VERSION ""

NS_ :

BS_:

BU_: AHLM ASBS CADM CBC DIAGNOST DPDM DTCM ECM EHPS ESC ESL ESM ETM EVCU2 GPF IC IRCM LTM OCM ORC PTS RF_HUB SCCM SGW TBM TCM

BO_ 1266 D_RS_GPF: 8 GPF
 SG_ D_RS_GPF : 7|64@0+ (1,0) [0|0] ""  SGW,TBM

BO_ 1284 D_RS_CBC: 8 CBC
 SG_ D_RS_CBC : 7|64@0+ (1,0) [0|0] ""  DIAGNOST,SGW,TBM

BO_ 1323 D_RS_TBM: 8 SGW
 SG_ D_RS_TBM : 7|64@0+ (1,0) [0|0] ""  DIAGNOST

BO_ 1408 ECU_APPL_RF_HUB: 8 RF_HUB
 SG_ ECU_APPL_RF_HUB : 7|64@0+ (1,0) [0|0] ""  DIAGNOST,SGW

BO_ 1409 ECU_APPL_CBC: 8 CBC
 SG_ ECU_APPL_CBC : 7|64@0+ (1,0) [0|0] ""  DIAGNOST,SGW

BO_ 1410 ECU_APPL_IC: 8 IC
 SG_ ECU_APPL_IC : 7|64@0+ (1,0) [0|0] ""  DIAGNOST,SGW

BO_ 1412 ECU_APPL_ORC: 8 ORC
 SG_ ECU_APPL_ORC : 7|64@0+ (1,0) [0|0] ""  DIAGNOST,SGW

BO_ 1415 ECU_APPL_ESC: 8 ESC
 SG_ ECU_APPL_ESC : 7|64@0+ (1,0) [0|0] ""  DIAGNOST,SGW

BO_ 1416 ECU_APPL_ESL: 8 ESL
 SG_ ECU_APPL_ESL : 7|64@0+ (1,0) [0|0] ""  DIAGNOST,SGW

BO_ 1417 ECU_APPL_ESM: 8 ESM
 SG_ ECU_APPL_ESM : 7|64@0+ (1,0) [0|0] ""  DIAGNOST,SGW

BO_ 1418 ECU_APPL_ASBS: 8 ASBS
 SG_ ECU_APPL_ASBS : 7|64@0+ (1,0) [0|0] ""  DIAGNOST,SGW

BO_ 1419 ECU_APPL_DTCM: 8 DTCM
 SG_ ECU_APPL_DTCM : 7|64@0+ (1,0) [0|0] ""  DIAGNOST,SGW

BO_ 1425 ECU_APPL_DPDM: 8 DPDM
 SG_ ECU_APPL_DPDM : 7|64@0+ (1,0) [0|0] ""  DIAGNOST,SGW

BO_ 1427 ECU_APPL_DASM: 8 CADM
 SG_ ECU_APPL_DASM : 7|64@0+ (1,0) [0|0] ""  DIAGNOST,SGW

BO_ 1434 ECU_APPL_EPS: 8 EHPS
 SG_ ECU_APPL_EPS : 7|64@0+ (1,0) [0|0] ""  DIAGNOST,SGW

BO_ 1438 ECU_APPL_OCM: 8 OCM
 SG_ ECU_APPL_OCM : 7|64@0+ (1,0) [0|0] ""  DIAGNOST,SGW

BO_ 1442 ECU_APPL_PTS: 8 PTS
 SG_ ECU_APPL_PTS : 7|64@0+ (1,0) [0|0] ""  DIAGNOST,SGW

BO_ 1443 ECU_APPL_SCCM: 8 SCCM
 SG_ ECU_APPL_SCCM : 7|64@0+ (1,0) [0|0] ""  DIAGNOST,SGW

BO_ 1449 ECU_APPL_AHLM: 8 AHLM
 SG_ ECU_APPL_AHLM : 7|64@0+ (1,0) [0|0] ""  DIAGNOST,SGW

BO_ 1464 ECU_APPL_ECM: 8 ECM
 SG_ ECU_APPL_ECM : 7|64@0+ (1,0) [0|0] ""  DIAGNOST,SGW

BO_ 1465 ECU_APPL_TCM: 8 TCM
 SG_ ECU_APPL_TCM : 7|64@0+ (1,0) [0|0] ""  DIAGNOST,SGW

BO_ 1468 ECU_APPL_BSMO: 8 ESC
 SG_ ECU_APPL_BSMO : 7|64@0+ (1,0) [0|0] ""  DIAGNOST,SGW

BO_ 1515 ECU_APPL_TBM: 8 SGW
 SG_ ECU_APPL_TBM : 7|64@0+ (1,0) [0|0] ""  DIAGNOST

BO_ 1536 SD_RS_RF_HUB: 8 RF_HUB
 SG_ SD_RS_RF_HUB : 7|64@0+ (1,0) [0|0] ""  SGW,TBM

BO_ 1537 SD_RS_CBC: 8 CBC
 SG_ SD_RS_CBC : 7|64@0+ (1,0) [0|0] ""  SGW,TBM

BO_ 1538 SD_RS_IC: 8 IC
 SG_ SD_RS_IC : 7|64@0+ (1,0) [0|0] ""  SGW,TBM

BO_ 1540 SD_RS_ORC: 8 ORC
 SG_ SD_RS_ORC : 7|64@0+ (1,0) [0|0] ""  SGW,TBM

BO_ 1543 SD_RS_ESC: 8 ESC
 SG_ SD_RS_ESC : 7|64@0+ (1,0) [0|0] ""  SGW,TBM

BO_ 1544 SD_RS_ESL: 8 ESL
 SG_ SD_RS_ESL : 7|64@0+ (1,0) [0|0] ""  SGW,TBM

BO_ 1545 SD_RS_ESM: 8 ESM
 SG_ SD_RS_ESM : 7|64@0+ (1,0) [0|0] ""  SGW,TBM

BO_ 1546 SD_RS_ASBS: 8 ASBS
 SG_ SD_RS_ASBS : 7|64@0+ (1,0) [0|0] ""  SGW,TBM

BO_ 1547 SD_RS_DTCM: 8 DTCM
 SG_ SD_RS_DTCM : 7|64@0+ (1,0) [0|0] ""  SGW,TBM

BO_ 1553 SD_RS_DPDM: 8 DPDM
 SG_ SD_RS_DPDM : 7|64@0+ (1,0) [0|0] ""  SGW,TBM

BO_ 1555 SD_RS_DASM: 8 CADM
 SG_ SD_RS_DASM : 7|64@0+ (1,0) [0|0] ""  SGW,TBM

BO_ 1562 SD_RS_EPS: 8 EHPS
 SG_ SD_RS_EPS : 7|64@0+ (1,0) [0|0] ""  SGW,TBM

BO_ 1566 SD_RS_OCM: 8 OCM
 SG_ SD_RS_OCM : 7|64@0+ (1,0) [0|0] ""  SGW,TBM

BO_ 1568 D_RQ_CBC: 8 DIAGNOST
 SG_ D_RQ_CBC : 7|64@0+ (1,0) [0|0] ""  CBC

BO_ 1570 SD_RS_PTS: 8 PTS
 SG_ SD_RS_PTS : 7|64@0+ (1,0) [0|0] ""  SGW,TBM

BO_ 1571 SD_RS_SCCM: 8 SCCM
 SG_ SD_RS_SCCM : 7|64@0+ (1,0) [0|0] ""  SGW,TBM

BO_ 1577 SD_RS_AHLM: 8 AHLM
 SG_ SD_RS_AHLM : 7|64@0+ (1,0) [0|0] ""  SGW,TBM

BO_ 1586 SD_RS_GPF: 8 GPF
 SG_ SD_RS_GPF : 7|64@0+ (1,0) [0|0] ""  SGW,TBM

BO_ 1592 SD_RS_ECM: 8 ECM
 SG_ SD_RS_ECM : 7|64@0+ (1,0) [0|0] ""  DIAGNOST,SGW,TBM

BO_ 1593 SD_RS_TCM: 8 TCM
 SG_ SD_RS_TCM : 7|64@0+ (1,0) [0|0] ""  SGW,TBM

BO_ 1596 SD_RS_BSMO: 8 ESC
 SG_ SD_RS_BSMO : 7|64@0+ (1,0) [0|0] ""  ETM,SGW,TBM

BO_ 1643 SD_RS_TBM: 8 SGW
 SG_ SD_RS_TBM : 7|64@0+ (1,0) [0|0] "" Vector__XXX

BO_ 1728 APPL_ECU_RF_HUB: 8 DIAGNOST
 SG_ APPL_ECU_RF_HUB : 7|64@0+ (1,0) [0|0] ""  RF_HUB

BO_ 1729 APPL_ECU_CBC: 8 DIAGNOST
 SG_ APPL_ECU_CBC : 7|64@0+ (1,0) [0|0] ""  CBC

BO_ 1730 APPL_ECU_IC: 8 DIAGNOST
 SG_ APPL_ECU_IC : 7|64@0+ (1,0) [0|0] ""  IC

BO_ 1732 APPL_ECU_ORC: 8 DIAGNOST
 SG_ APPL_ECU_ORC : 7|64@0+ (1,0) [0|0] ""  ORC

BO_ 1735 APPL_ECU_ESC: 8 DIAGNOST
 SG_ APPL_ECU_ESC : 7|64@0+ (1,0) [0|0] ""  ESC

BO_ 1736 APPL_ECU_ESL: 8 DIAGNOST
 SG_ APPL_ECU_ESL : 7|64@0+ (1,0) [0|0] ""  ESL

BO_ 1737 APPL_ECU_ESM: 8 DIAGNOST
 SG_ APPL_ECU_ESM : 7|64@0+ (1,0) [0|0] ""  ESM

BO_ 1738 APPL_ECU_ASBS: 8 DIAGNOST
 SG_ APPL_ECU_ASBS : 7|64@0+ (1,0) [0|0] ""  ASBS

BO_ 1739 APPL_ECU_DTCM: 8 DIAGNOST
 SG_ APPL_ECU_DTCM : 7|64@0+ (1,0) [0|0] ""  DTCM

BO_ 1745 APPL_ECU_DPDM: 8 DIAGNOST
 SG_ APPL_ECU_DPDM : 7|64@0+ (1,0) [0|0] ""  DPDM

BO_ 1747 APPL_ECU_DASM: 8 DIAGNOST
 SG_ APPL_ECU_DASM : 7|64@0+ (1,0) [0|0] ""  CADM,IRCM

BO_ 1754 APPL_ECU_EPS: 8 DIAGNOST
 SG_ APPL_ECU_EPS : 7|64@0+ (1,0) [0|0] ""  EHPS

BO_ 1758 APPL_ECU_OCM: 8 DIAGNOST
 SG_ APPL_ECU_OCM : 7|64@0+ (1,0) [0|0] ""  OCM

BO_ 1762 APPL_ECU_PTS: 8 DIAGNOST
 SG_ APPL_ECU_PTS : 7|64@0+ (1,0) [0|0] ""  PTS

BO_ 1763 APPL_ECU_SCCM: 8 DIAGNOST
 SG_ APPL_ECU_SCCM : 7|64@0+ (1,0) [0|0] ""  SCCM

BO_ 1769 APPL_ECU_AHLM: 8 DIAGNOST
 SG_ APPL_ECU_AHLM : 7|64@0+ (1,0) [0|0] ""  AHLM

BO_ 1784 APPL_ECU_ECM: 8 DIAGNOST
 SG_ APPL_ECU_ECM : 7|64@0+ (1,0) [0|0] ""  ECM

BO_ 1785 APPL_ECU_TCM: 8 DIAGNOST
 SG_ APPL_ECU_TCM : 7|64@0+ (1,0) [0|0] ""  TCM

BO_ 1788 APPL_ECU_BSMO: 8 DIAGNOST
 SG_ APPL_ECU_BSMO : 7|64@0+ (1,0) [0|0] ""  ESC

BO_ 1835 APPL_ECU_TBM: 8 DIAGNOST
 SG_ APPL_ECU_TBM : 7|64@0+ (1,0) [0|0] ""  TBM

BO_ 1856 D_RQ_RF_HUB: 8 DIAGNOST
 SG_ D_RQ_RF_HUB : 7|64@0+ (1,0) [0|0] ""  RF_HUB

BO_ 1858 D_RQ_IC: 8 DIAGNOST
 SG_ D_RQ_IC : 7|64@0+ (1,0) [0|0] ""  IC

BO_ 1860 D_RQ_ORC: 8 DIAGNOST
 SG_ D_RQ_ORC : 7|64@0+ (1,0) [0|0] ""  ORC

BO_ 1863 D_RQ_ESC: 8 DIAGNOST
 SG_ D_RQ_ESC : 7|64@0+ (1,0) [0|0] ""  ESC

BO_ 1864 D_RQ_ESL: 8 DIAGNOST
 SG_ D_RQ_ESL : 7|64@0+ (1,0) [0|0] ""  ESL

BO_ 1865 D_RQ_ESM: 8 DIAGNOST
 SG_ D_RQ_ESM : 7|64@0+ (1,0) [0|0] ""  ESM

BO_ 1866 D_RQ_ASBS: 8 DIAGNOST
 SG_ D_RQ_ASBS : 7|64@0+ (1,0) [0|0] ""  ASBS

BO_ 1867 D_RQ_DTCM: 8 DIAGNOST
 SG_ D_RQ_DTCM : 7|64@0+ (1,0) [0|0] ""  DTCM

BO_ 1873 D_RQ_DPDM: 8 DIAGNOST
 SG_ D_RQ_DPDM : 7|64@0+ (1,0) [0|0] ""  DPDM

BO_ 1875 D_RQ_DASM: 8 DIAGNOST
 SG_ D_RQ_DASM : 7|64@0+ (1,0) [0|0] ""  CADM,IRCM

BO_ 1882 D_RQ_EPS: 8 DIAGNOST
 SG_ D_RQ_EPS : 7|64@0+ (1,0) [0|0] ""  EHPS

BO_ 1886 D_RQ_OCM: 8 DIAGNOST
 SG_ D_RQ_OCM : 7|64@0+ (1,0) [0|0] ""  OCM

BO_ 1890 D_RQ_PTS: 8 DIAGNOST
 SG_ D_RQ_PTS : 7|64@0+ (1,0) [0|0] ""  PTS

BO_ 1891 D_RQ_SCCM: 8 DIAGNOST
 SG_ D_RQ_SCCM : 7|64@0+ (1,0) [0|0] ""  SCCM

BO_ 1897 D_RQ_AHLM: 8 DIAGNOST
 SG_ D_RQ_AHLM : 7|64@0+ (1,0) [0|0] ""  AHLM

BO_ 1901 D_RQ_IDCM: 8 DIAGNOST
 SG_ D_RQ_IDCM : 7|64@0+ (1,0) [0|0] ""  EVCU2

BO_ 1906 D_RQ_GPF: 8 SGW
 SG_ D_RQ_GPF : 7|64@0+ (1,0) [0|0] ""  GPF

BO_ 1963 D_RQ_TBM: 8 DIAGNOST
 SG_ D_RQ_TBM : 7|64@0+ (1,0) [0|0] ""  TBM

BO_ 2015 DG_RQ_GLOBAL: 8 DIAGNOST
 SG_ DG_RQ_GLOBAL : 7|64@0+ (1,0) [0|0] ""  ECM,EVCU2,TCM

BO_ 2016 D_RQ_ECM: 8 DIAGNOST
 SG_ D_RQ_ECM : 7|64@0+ (1,0) [0|0] ""  ECM

BO_ 2017 D_RQ_TCM: 8 DIAGNOST
 SG_ D_RQ_TCM : 7|64@0+ (1,0) [0|0] ""  TCM

BO_ 2020 D_RQ_BSMO: 8 DIAGNOST
 SG_ D_RQ_BSMO : 7|64@0+ (1,0) [0|0] ""  ESC

BO_ 2021 D_RQ_MCPA: 8 DIAGNOST
 SG_ D_RQ_MCPA : 7|64@0+ (1,0) [0|0] ""  EVCU2

BO_ 2023 D_RQ_BPCM: 8 DIAGNOST
 SG_ D_RQ_BPCM : 7|64@0+ (1,0) [0|0] ""  EVCU2

BO_ 2024 D_RS_ECM: 8 ECM
 SG_ D_RS_ECM : 7|64@0+ (1,0) [0|0] ""  DIAGNOST,SGW,TBM

BO_ 2025 D_RS_TCM: 8 TCM
 SG_ D_RS_TCM : 7|64@0+ (1,0) [0|0] ""  DIAGNOST,SGW,TBM

BO_ 2028 D_RS_BSMO: 8 ESC
 SG_ D_RS_BSMO : 7|64@0+ (1,0) [0|0] ""  DIAGNOST,ETM,SGW,TBM

BO_ 2029 D_RS_MCPA: 8 EVCU2
 SG_ D_RS_MCPA : 7|64@0+ (1,0) [0|0] ""  DIAGNOST,SGW,TBM

BO_ 2031 D_RS_BPCM: 8 EVCU2
 SG_ D_RS_BPCM : 7|64@0+ (1,0) [0|0] ""  DIAGNOST,SGW,TBM

BO_ 2047 WAKE_SGW: 1 SGW
 SG_ WAKE_SGW_Signal : 0|8@1+ (1,0) [0|0] "" Vector__XXX

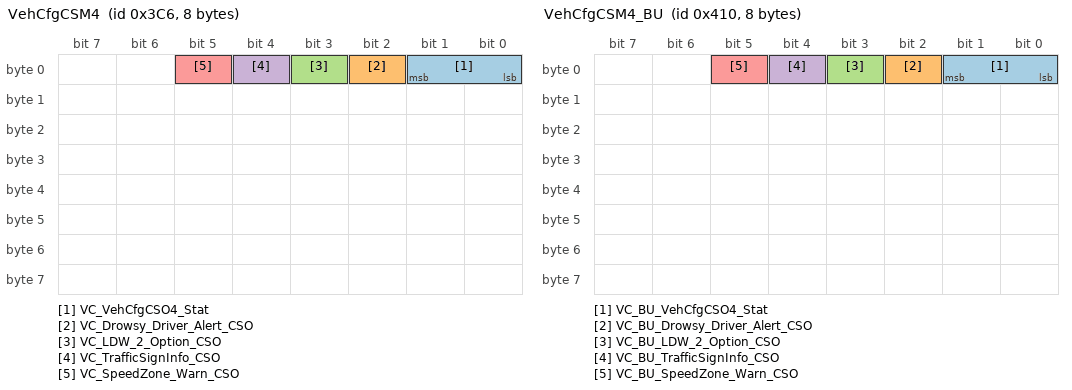
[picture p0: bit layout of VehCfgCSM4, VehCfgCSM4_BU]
BO_ 966 VehCfgCSM4: 8 CBC
 SG_ VC_VehCfgCSO4_Stat : 0|2@1+ (1,0) [0|0] ""  EVCU2,RF_HUB,SGW
 SG_ VC_Drowsy_Driver_Alert_CSO : 2|1@1+ (1,0) [0|0] ""  RF_HUB,SGW
 SG_ VC_LDW_2_Option_CSO : 3|1@1+ (1,0) [0|0] ""  RF_HUB,SGW
 SG_ VC_TrafficSignInfo_CSO : 4|1@1+ (1,0) [0|0] ""  RF_HUB,SGW
 SG_ VC_SpeedZone_Warn_CSO : 5|1@1+ (1,0) [0|0] ""  RF_HUB,SGW

BO_ 1040 VehCfgCSM4_BU: 8 RF_HUB
 SG_ VC_BU_VehCfgCSO4_Stat : 0|2@1+ (1,0) [0|0] ""  CBC,SGW
 SG_ VC_BU_Drowsy_Driver_Alert_CSO : 2|1@1+ (1,0) [0|0] ""  CBC,SGW
 SG_ VC_BU_LDW_2_Option_CSO : 3|1@1+ (1,0) [0|0] ""  CBC,SGW
 SG_ VC_BU_TrafficSignInfo_CSO : 4|1@1+ (1,0) [0|0] ""  CBC,SGW
 SG_ VC_BU_SpeedZone_Warn_CSO : 5|1@1+ (1,0) [0|0] ""  CBC,SGW

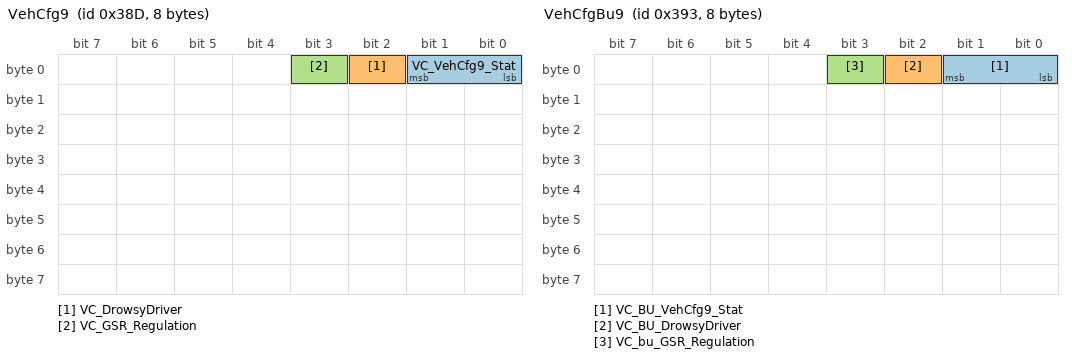
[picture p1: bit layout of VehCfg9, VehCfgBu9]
BO_ 909 VehCfg9: 8 CBC
 SG_ VC_VehCfg9_Stat : 0|2@1+ (1,0) [0|0] ""  CADM,EVCU2,IC,ORC,SGW
 SG_ VC_DrowsyDriver : 2|1@1+ (1,0) [0|0] ""  CADM,IC,ORC,RF_HUB,SGW
 SG_ VC_GSR_Regulation : 3|1@1+ (1,0) [0|0] ""  IC,CADM,ESC,IRCM,RF_HUB,SGW

BO_ 915 VehCfgBu9: 8 RF_HUB
 SG_ VC_BU_VehCfg9_Stat : 0|2@1+ (1,0) [0|0] ""  CBC,SGW
 SG_ VC_BU_DrowsyDriver : 2|1@1+ (1,0) [0|0] ""  CBC,SGW
 SG_ VC_bu_GSR_Regulation : 3|1@1+ (1,0) [0|0] ""  CBC,SGW

BO_ 232 DAS_A4: 8 CADM
 SG_ HMI_Screens : 0|8@1+ (1,0) [0|254] "Text"  IC,SGW
 SG_ SetSpeed_KPH : 8|8@1+ (1,0) [0|250] "km/h"  ECM,EVCU2,IC,SGW,TCM
 SG_ SetSpeed_MPH : 16|8@1+ (1,0) [0|250] "mph"  IC,ORC,SGW,TCM
 SG_ FCW_Error : 26|2@1+ (1,0) [0|0] ""  IC,ORC,SGW
 SG_ FCW_BrkOn : 29|1@1+ (1,0) [0|0] ""  CBC,ORC,SGW
 SG_ CIPV_Fused : 30|1@1+ (1,0) [0|0] ""  ORC,SGW
 SG_ ACCOnOff : 36|3@1+ (1,0) [0|0] ""  ECM,ETM,EVCU2,IC,ORC,SGW,TBM
 SG_ RadarBlocked : 46|1@1+ (1,0) [0|0] ""  CBC,IC,ORC,SGW
 SG_ FCWBrakingOff : 47|1@1+ (1,0) [0|0] ""  IC,SGW
 SG_ ACConlyNA_DASMSts : 48|1@1+ (1,0) [0|0] ""  ETM,IC,SGW,TBM
 SG_ NCConlyNA_DASMSts : 49|1@1+ (1,0) [0|0] ""  ETM,IC,SGW,TBM
 SG_ ACCFaulted : 50|1@1+ (1,0) [0|0] ""  ETM,IC,ORC,SGW,TBM
 SG_ FCWonlyNA_DASMSts : 51|1@1+ (1,0) [0|0] ""  IC,SGW
 SG_ ACCNA_DASMSts : 52|1@1+ (1,0) [0|0] ""  IC,SGW
 SG_ NCCNA_DASMSts : 53|1@1+ (1,0) [0|0] ""  IC,SGW
 SG_ CameraBlocked : 54|1@1+ (1,0) [0|0] ""  CBC,IC,ORC,SGW
 SG_ CameraFailure : 55|1@1+ (1,0) [0|0] ""  IC,ORC,SGW
 SG_ ObjIntrstDist : 56|8@1+ (1,0) [0|253] "m"  ORC,SGW,TCM
 SG_ Sm_ICON_Dspl : 40|6@1+ (1,0) [0|0] ""  IC,SGW

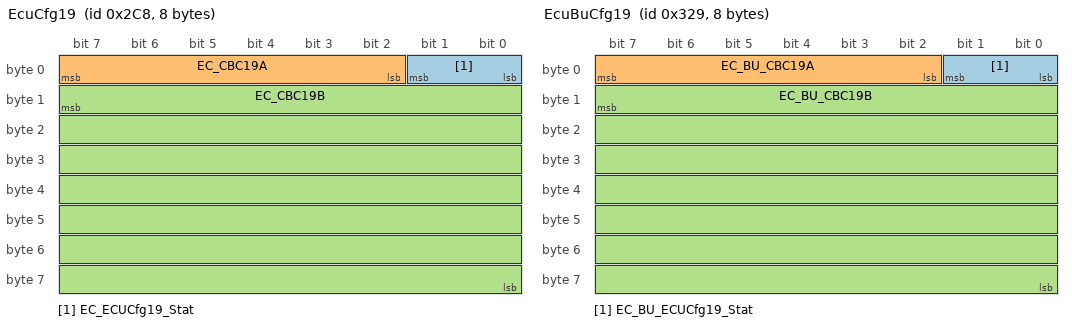
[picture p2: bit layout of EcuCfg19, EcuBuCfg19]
BO_ 712 EcuCfg19: 8 CBC
 SG_ EC_ECUCfg19_Stat : 0|2@1+ (1,0) [0|0] ""  RF_HUB,SGW
 SG_ EC_CBC19A : 2|6@1+ (1,0) [0|0] ""  RF_HUB,SGW
 SG_ EC_CBC19B : 15|56@0+ (1,0) [0|0] ""  RF_HUB,SGW

BO_ 809 EcuBuCfg19: 8 RF_HUB
 SG_ EC_BU_ECUCfg19_Stat : 0|2@1+ (1,0) [0|0] ""  CBC,SGW
 SG_ EC_BU_CBC19A : 2|6@1+ (1,0) [0|0] ""  CBC,SGW
 SG_ EC_BU_CBC19B : 15|56@0+ (1,0) [0|0] ""  CBC,SGW

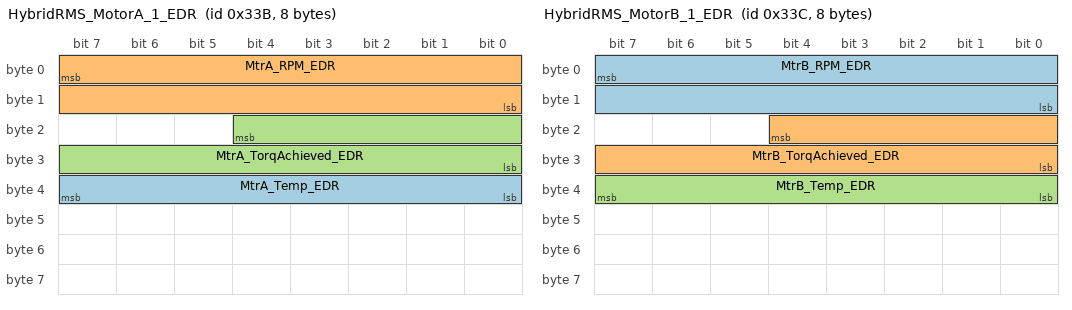
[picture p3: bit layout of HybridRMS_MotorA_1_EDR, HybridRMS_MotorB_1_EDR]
BO_ 827 HybridRMS_MotorA_1_EDR: 8 EVCU2
 SG_ MtrA_Temp_EDR : 32|8@1+ (1,-40) [-40|215] "∞C"  SGW,TBM
 SG_ MtrA_RPM_EDR : 7|16@0+ (1,-32768) [-32768|32767] "RPM"  ORC,SGW,TBM
 SG_ MtrA_TorqAchieved_EDR : 20|13@0+ (0.125,-512) [-512|511.875] "Nm"  SGW,TBM

BO_ 828 HybridRMS_MotorB_1_EDR: 8 EVCU2
 SG_ MtrB_RPM_EDR : 7|16@0+ (1,-32768) [-32768|32767] "RPM"  ORC,SGW,TBM
 SG_ MtrB_TorqAchieved_EDR : 20|13@0+ (0.125,-512) [-512|511.875] "Nm"  SGW,TBM
 SG_ MtrB_Temp_EDR : 32|8@1+ (1,-40) [-40|215] "∞C"  SGW,TBM

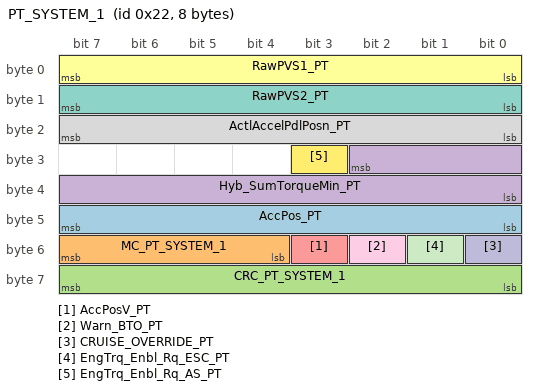
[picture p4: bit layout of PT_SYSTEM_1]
BO_ 34 PT_SYSTEM_1: 8 EVCU2
 SG_ AccPos_PT : 40|8@1+ (0.392157,0) [0|99.607878] "%"  CBC,DTCM,ECM,ESC,SGW,TBM,TCM
 SG_ MC_PT_SYSTEM_1 : 52|4@1+ (1,0) [0|15] ""  ECM,ESC,ORC,SGW,TCM
 SG_ CRC_PT_SYSTEM_1 : 56|8@1+ (1,0) [0|0] ""  ECM,ESC,ORC,SGW,TCM
 SG_ Hyb_SumTorqueMin_PT : 26|11@0+ (1,-500) [-500|1546] "Nm"  DTCM,ESC,SGW,TCM
 SG_ AccPosV_PT : 51|1@1+ (1,0) [0|0] ""  CBC,DTCM,ECM,ESC,SGW,TCM
 SG_ RawPVS1_PT : 0|8@1+ (0.019607843,0) [0|4.999999965] "Volts"  ORC,SGW
 SG_ RawPVS2_PT : 8|8@1+ (0.019607843,0) [0|4.999999965] "Volts"  ORC,SGW
 SG_ ActlAccelPdlPosn_PT : 16|8@1+ (0.4,0) [0|102] "%"  ECM,ESC,ETM,ORC,SGW,TBM
 SG_ Warn_BTO_PT : 50|1@1+ (1,0) [0|0] ""  IC,SGW
 SG_ CRUISE_OVERRIDE_PT : 48|1@1+ (1,0) [0|0] ""  ECM,ESC,ORC,SGW,TCM
 SG_ EngTrq_Enbl_Rq_ESC_PT : 49|1@1+ (1,0) [0|0] ""  ECM,ESC,SGW
 SG_ EngTrq_Enbl_Rq_AS_PT : 27|1@1+ (1,0) [0|0] ""  ECM,ESC,SGW

BO_ 2026 D_RS_EVCU2: 8 EVCU2
 SG_ D_RS_EVCU2 : 7|64@0+ (1,0) [0|0] ""  DIAGNOST,SGW,TBM

BO_ 1594 SD_RS_EVCU2: 8 EVCU2
 SG_ SD_RS_EVCU2 : 7|64@0+ (1,0) [0|0] ""  SGW,TBM

BO_ 2018 D_RQ_EVCU2: 8 DIAGNOST
 SG_ D_RQ_EVCU2 : 7|64@0+ (1,0) [0|0] ""  EVCU2

BO_ 1466 ECU_APPL_EVCU2: 8 EVCU2
 SG_ ECU_APPL_EVCU2 : 7|64@0+ (1,0) [0|0] ""  DIAGNOST,SGW

BO_ 1786 APPL_ECU_EVCU2: 8 DIAGNOST
 SG_ APPL_ECU_EVCU2 : 7|64@0+ (1,0) [0|0] ""  EVCU2

BO_ 1082 NM_EVCU2: 8 EVCU2
 SG_ NM_Mode : 0|8@1+ (1,0) [0|0] ""  CBC,EHPS,ESC,ESL,ESM,EVCU2,IC,RF_HUB,SCCM,SGW
 SG_ NM_Sleep_Ack : 22|1@1+ (1,0) [0|0] ""  CBC,EHPS,ESC,ESL,ESM,EVCU2,IC,RF_HUB,SCCM,SGW
 SG_ Nw_Id : 56|8@1+ (1,0) [0|0] ""  CBC,EHPS,ESC,ESL,ESM,EVCU2,IC,RF_HUB,SCCM,SGW
 SG_ NM_Successor : 8|8@1+ (1,0) [0|63] ""  CBC,EHPS,ESC,ESL,ESM,EVCU2,IC,RF_HUB,SCCM,SGW
 SG_ NM_Ud_Launch : 16|6@1+ (1,0) [0|0] ""  CBC,EHPS,ESC,ESL,ESM,EVCU2,IC,RF_HUB,SCCM,SGW
 SG_ NM_Sleep_Ind : 23|1@1+ (1,0) [0|0] ""  CBC,EHPS,ESC,ESL,ESM,EVCU2,IC,RF_HUB,SCCM,SGW
 SG_ NM_Ud_Srv M : 24|8@1+ (1,0) [0|0] ""  CBC,EHPS,ESC,ESL,ESM,EVCU2,IC,RF_HUB,SCCM,SGW
 SG_ WakeupRsn_EVCU2 m2 : 32|8@1+ (1,0) [0|0] ""  CBC,EHPS,ESC,ESL,ESM,EVCU2,IC,RF_HUB,SCCM,SGW
 SG_ Awake_Chg_ST m15 : 35|1@1+ (1,0) [0|0] ""  CBC,EHPS,ESC,ESL,ESM,EVCU2,IC,RF_HUB,SCCM,SGW
 SG_ Awake_OBCM_WU m15 : 34|1@1+ (1,0) [0|0] ""  CBC,EHPS,ESC,ESL,ESM,EVCU2,IC,RF_HUB,SCCM,SGW
 SG_ Awake_Diag_Actv m15 : 33|1@1+ (1,0) [0|0] ""  CBC,EHPS,ESC,ESL,ESM,EVCU2,IC,RF_HUB,SCCM,SGW
 SG_ Awake_NwSt m15 : 32|1@1+ (1,0) [0|0] ""  CBC,EHPS,ESC,ESL,ESM,EVCU2,IC,RF_HUB,SCCM,SGW
 SG_ WakeupCnt m2 : 40|8@1+ (1,0) [0|254] ""  CBC,EHPS,ESC,ESL,ESM,EVCU2,IC,RF_HUB,SCCM,SGW

BO_ 1268 D_RS_MCPB: 8 EVCU2
 SG_ D_RS_MCPB : 7|64@0+ (1,0) [0|0] ""  DIAGNOST,SGW,TBM

BO_TX_BU_ 1323 : SGW,TBM;
BO_TX_BU_ 1427 : CADM,IRCM;
BO_TX_BU_ 1515 : SGW,TBM;
BO_TX_BU_ 1555 : CADM,IRCM;
BO_TX_BU_ 1568 : DIAGNOST,SGW,TBM;
BO_TX_BU_ 1643 : SGW,TBM;
BO_TX_BU_ 1728 : DIAGNOST,SGW;
BO_TX_BU_ 1729 : DIAGNOST,SGW;
BO_TX_BU_ 1730 : DIAGNOST,SGW;
BO_TX_BU_ 1732 : DIAGNOST,SGW;
BO_TX_BU_ 1735 : DIAGNOST,SGW;
BO_TX_BU_ 1736 : DIAGNOST,SGW;
BO_TX_BU_ 1737 : DIAGNOST,SGW;
BO_TX_BU_ 1738 : DIAGNOST,SGW;
BO_TX_BU_ 1739 : DIAGNOST,SGW;
BO_TX_BU_ 1745 : DIAGNOST,SGW;
BO_TX_BU_ 1747 : DIAGNOST,SGW;
BO_TX_BU_ 1754 : DIAGNOST,SGW;
BO_TX_BU_ 1758 : DIAGNOST,SGW;
BO_TX_BU_ 1762 : DIAGNOST,SGW;
BO_TX_BU_ 1763 : DIAGNOST,SGW;
BO_TX_BU_ 1769 : DIAGNOST,SGW;
BO_TX_BU_ 1784 : DIAGNOST,SGW;
BO_TX_BU_ 1785 : DIAGNOST,SGW;
BO_TX_BU_ 1788 : DIAGNOST,SGW;
BO_TX_BU_ 1835 : DIAGNOST,SGW;
BO_TX_BU_ 1856 : DIAGNOST,SGW,TBM;
BO_TX_BU_ 1858 : DIAGNOST,SGW,TBM;
BO_TX_BU_ 1860 : DIAGNOST,SGW,TBM;
BO_TX_BU_ 1863 : DIAGNOST,SGW,TBM;
BO_TX_BU_ 1864 : DIAGNOST,SGW,TBM;
BO_TX_BU_ 1865 : DIAGNOST,SGW,TBM;
BO_TX_BU_ 1866 : DIAGNOST,SGW,TBM;
BO_TX_BU_ 1867 : DIAGNOST,SGW,TBM;
BO_TX_BU_ 1873 : DIAGNOST,SGW,TBM;
BO_TX_BU_ 1875 : DIAGNOST,SGW,TBM;
BO_TX_BU_ 1882 : DIAGNOST,SGW,TBM;
BO_TX_BU_ 1886 : DIAGNOST,SGW,TBM;
BO_TX_BU_ 1890 : DIAGNOST,SGW,TBM;
BO_TX_BU_ 1891 : DIAGNOST,SGW,TBM;
BO_TX_BU_ 1897 : DIAGNOST,SGW,TBM;
BO_TX_BU_ 1901 : DIAGNOST,SGW,TBM;
BO_TX_BU_ 1906 : SGW,TBM;
BO_TX_BU_ 1963 : DIAGNOST,SGW;
BO_TX_BU_ 2015 : DIAGNOST,SGW;
BO_TX_BU_ 2016 : DIAGNOST,SGW,TBM;
BO_TX_BU_ 2017 : DIAGNOST,SGW,TBM;
BO_TX_BU_ 2020 : DIAGNOST,ETM,SGW,TBM;
BO_TX_BU_ 2021 : DIAGNOST,SGW,TBM;
BO_TX_BU_ 2023 : DIAGNOST,SGW,TBM;
BO_TX_BU_ 232 : CADM,IRCM;
BO_TX_BU_ 2018 : DIAGNOST,SGW,TBM;
BO_TX_BU_ 1786 : DIAGNOST,SGW;
CM_ SG_ 1266 D_RS_GPF "Diagnostic-Response";
CM_ SG_ 1284 D_RS_CBC "Diagnostic-Response";
CM_ SG_ 1323 D_RS_TBM "Diagnostic-Response";
CM_ SG_ 1408 ECU_APPL_RF_HUB "ECU to External Application";
CM_ SG_ 1409 ECU_APPL_CBC "ECU to External Application";
CM_ SG_ 1410 ECU_APPL_IC "ECU to External Application";
CM_ SG_ 1412 ECU_APPL_ORC "ECU to External Application";
CM_ SG_ 1415 ECU_APPL_ESC "ECU to External Application";
CM_ SG_ 1416 ECU_APPL_ESL "ECU to External Application";
CM_ SG_ 1417 ECU_APPL_ESM "ECU to External Application";
CM_ SG_ 1418 ECU_APPL_ASBS "ECU to External Application";
CM_ SG_ 1419 ECU_APPL_DTCM "ECU to External Application";
CM_ SG_ 1425 ECU_APPL_DPDM "ECU to External Application";
CM_ SG_ 1427 ECU_APPL_DASM "ECU to External Application";
CM_ SG_ 1434 ECU_APPL_EPS "ECU to External Application";
CM_ SG_ 1438 ECU_APPL_OCM "ECU to External Application";
CM_ SG_ 1442 ECU_APPL_PTS "ECU to External Application";
CM_ SG_ 1443 ECU_APPL_SCCM "ECU to External Application";
CM_ SG_ 1449 ECU_APPL_AHLM "ECU to External Application";
CM_ SG_ 1464 ECU_APPL_ECM "ECU to External Application";
CM_ SG_ 1465 ECU_APPL_TCM "ECU to External Application";
CM_ SG_ 1468 ECU_APPL_BSMO "ECU to External Application";
CM_ SG_ 1515 ECU_APPL_TBM "ECU to External Application";
CM_ SG_ 1536 SD_RS_RF_HUB "Response on Event - light";
CM_ SG_ 1537 SD_RS_CBC "Response on Event - light";
CM_ SG_ 1538 SD_RS_IC "Response on Event - light";
CM_ SG_ 1540 SD_RS_ORC "Response on Event - light";
CM_ SG_ 1543 SD_RS_ESC "Response on Event - light";
CM_ SG_ 1544 SD_RS_ESL "Response on Event - light";
CM_ SG_ 1545 SD_RS_ESM "Response on Event - light";
CM_ SG_ 1546 SD_RS_ASBS "Response on Event - light";
CM_ SG_ 1547 SD_RS_DTCM "Response on Event - light";
CM_ SG_ 1553 SD_RS_DPDM "Response on Event - light";
CM_ SG_ 1555 SD_RS_DASM "Response on Event - light";
CM_ SG_ 1562 SD_RS_EPS "Response on Event - light";
CM_ SG_ 1566 SD_RS_OCM "Response on Event - light";
CM_ SG_ 1568 D_RQ_CBC "Diagnostic-Request";
CM_ SG_ 1570 SD_RS_PTS "Response on Event - light";
CM_ SG_ 1571 SD_RS_SCCM "Response on Event - light";
CM_ SG_ 1577 SD_RS_AHLM "Response on Event - light";
CM_ SG_ 1586 SD_RS_GPF "Response on Event - light";
CM_ SG_ 1592 SD_RS_ECM "Response on Event - light";
CM_ SG_ 1593 SD_RS_TCM "Response on Event - light";
CM_ SG_ 1596 SD_RS_BSMO "Response on Event - light";
CM_ SG_ 1643 SD_RS_TBM "Response on Event - light";
CM_ SG_ 1728 APPL_ECU_RF_HUB "External Application to ECU";
CM_ SG_ 1729 APPL_ECU_CBC "External Application to ECU";
CM_ SG_ 1730 APPL_ECU_IC "External Application to ECU";
CM_ SG_ 1732 APPL_ECU_ORC "External Application to ECU";
CM_ SG_ 1735 APPL_ECU_ESC "External Application to ECU";
CM_ SG_ 1736 APPL_ECU_ESL "External Application to ECU";
CM_ SG_ 1737 APPL_ECU_ESM "External Application to ECU";
CM_ SG_ 1738 APPL_ECU_ASBS "External Application to ECU";
CM_ SG_ 1739 APPL_ECU_DTCM "External Application to ECU";
CM_ SG_ 1745 APPL_ECU_DPDM "External Application to ECU";
CM_ SG_ 1747 APPL_ECU_DASM "External Application to ECU";
CM_ SG_ 1754 APPL_ECU_EPS "External Application to ECU";
CM_ SG_ 1758 APPL_ECU_OCM "External Application to ECU";
CM_ SG_ 1762 APPL_ECU_PTS "External Application to ECU";
CM_ SG_ 1763 APPL_ECU_SCCM "External Application to ECU";
CM_ SG_ 1769 APPL_ECU_AHLM "External Application to ECU";
CM_ SG_ 1784 APPL_ECU_ECM "External Application to ECU";
CM_ SG_ 1785 APPL_ECU_TCM "External Application to ECU";
CM_ SG_ 1788 APPL_ECU_BSMO "External Application to ECU";
CM_ SG_ 1835 APPL_ECU_TBM "External Application to ECU";
CM_ SG_ 1856 D_RQ_RF_HUB "Diagnostic-Request";
CM_ SG_ 1858 D_RQ_IC "Diagnostic-Request";
CM_ SG_ 1860 D_RQ_ORC "Diagnostic-Request";
CM_ SG_ 1863 D_RQ_ESC "Diagnostic-Request";
CM_ SG_ 1864 D_RQ_ESL "Diagnostic-Request";
CM_ SG_ 1865 D_RQ_ESM "Diagnostic-Request";
CM_ SG_ 1866 D_RQ_ASBS "Diagnostic-Request";
CM_ SG_ 1867 D_RQ_DTCM "Diagnostic-Request";
CM_ SG_ 1873 D_RQ_DPDM "Diagnostic-Request";
CM_ SG_ 1875 D_RQ_DASM "Diagnostic-Request";
CM_ SG_ 1882 D_RQ_EPS "Diagnostic-Request";
CM_ SG_ 1886 D_RQ_OCM "Diagnostic-Request";
CM_ SG_ 1890 D_RQ_PTS "Diagnostic-Request";
CM_ SG_ 1891 D_RQ_SCCM "Diagnostic-Request";
CM_ SG_ 1897 D_RQ_AHLM "Diagnostic-Request";
CM_ SG_ 1901 D_RQ_IDCM "Diagnostic-Request";
CM_ SG_ 1906 D_RQ_GPF "Diagnostic-Request";
CM_ SG_ 1963 D_RQ_TBM "Diagnostic-Request";
CM_ SG_ 2015 DG_RQ_GLOBAL "Diagnostic-Request";
CM_ SG_ 2016 D_RQ_ECM "Diagnostic-Request";
CM_ SG_ 2017 D_RQ_TCM "Diagnostic-Request";
CM_ SG_ 2020 D_RQ_BSMO "Diagnostic-Request";
CM_ SG_ 2021 D_RQ_MCPA "Diagnostic-Request";
CM_ SG_ 2023 D_RQ_BPCM "Diagnostic-Request";
CM_ SG_ 2024 D_RS_ECM "Diagnostic-Response";
CM_ SG_ 2025 D_RS_TCM "Diagnostic-Response";
CM_ SG_ 2028 D_RS_BSMO "Diagnostic-Response";
CM_ SG_ 2029 D_RS_MCPA "Diagnostic-Response";
CM_ SG_ 2031 D_RS_BPCM "Diagnostic-Response";
CM_ SG_ 2047 WAKE_SGW_Signal "This signal is used to wakeup networks";
CM_ SG_ 966 VC_VehCfgCSO4_Stat "Configuration message CSO4 status";
CM_ SG_ 966 VC_Drowsy_Driver_Alert_CSO "Droswy Driver Alert customer setting, Present = 1";
CM_ SG_ 966 VC_LDW_2_Option_CSO "Lane Departure Warning - 2 Option Customer setting, Present = 1";
CM_ SG_ 966 VC_TrafficSignInfo_CSO "Lane Departure Warning - 2 Option Customer setting, Present = 1";
CM_ SG_ 966 VC_SpeedZone_Warn_CSO "New Speed Zone Warning customer setting, Present = 1";
CM_ SG_ 1040 VC_BU_VehCfgCSO4_Stat "Configuration message CSO4 status";
CM_ SG_ 1040 VC_BU_Drowsy_Driver_Alert_CSO "Droswy Driver Alert customer setting, Present = 1";
CM_ SG_ 1040 VC_BU_LDW_2_Option_CSO "Lane Departure Warning - 2 Option Customer setting, Present = 1";
CM_ SG_ 1040 VC_BU_TrafficSignInfo_CSO "Lane Departure Warning - 2 Option Customer setting, Present = 1";
CM_ SG_ 1040 VC_BU_SpeedZone_Warn_CSO "New Speed Zone Warning customer setting, Present = 1";
CM_ SG_ 909 VC_VehCfg9_Stat "Configuration messages status 9";
CM_ SG_ 909 VC_DrowsyDriver "Trailer Reverse Guidance Present; 0 = Not Set, 1 = Set";
CM_ SG_ 909 VC_GSR_Regulation "Trailer Reverse Guidance Present; 0 = Off, 1 = On";
CM_ SG_ 915 VC_BU_VehCfg9_Stat "Backup for Configuration messages status 9";
CM_ SG_ 915 VC_BU_DrowsyDriver "Vehicle Configured for Drowsy Driver; 0 = On, 1 = Off";
CM_ SG_ 915 VC_bu_GSR_Regulation "Vehicle Configured to meet GSR Regulatory Requirements; 0 = On, 1 = Off";
CM_ SG_ 232 HMI_Screens "HMI screens";
CM_ SG_ 232 SetSpeed_KPH "Desired set speed in kilometers per hour";
CM_ SG_ 232 SetSpeed_MPH "Desired set speed in miles per hour";
CM_ SG_ 232 FCW_Error "Forward collision warning error";
CM_ SG_ 232 FCW_BrkOn "FCW braking is on; true = [1]";
CM_ SG_ 232 CIPV_Fused "Closest in-path vehicle is fused; True = [1]";
CM_ SG_ 232 ACCOnOff "ACC on off status";
CM_ SG_ 232 RadarBlocked "ACC FCW not available: clean radar snsr; True = [1]";
CM_ SG_ 232 FCWBrakingOff "FCW autobraking disabled; True = [1]";
CM_ SG_ 232 ACConlyNA_DASMSts "ACC only not available: vehicle system error; True = [1]";
CM_ SG_ 232 NCConlyNA_DASMSts "NCC only not available: vehicle system error; True = [1]";
CM_ SG_ 232 ACCFaulted "ACC faulted; True = [1]";
CM_ SG_ 232 FCWonlyNA_DASMSts "FCW only not available: vehicle system error; True = [1]";
CM_ SG_ 232 ACCNA_DASMSts "ACC/FCW not avail: vehicle system error; True = [1]";
CM_ SG_ 232 NCCNA_DASMSts "NCC/FCW not avail: vehicle system error; True = [1]";
CM_ SG_ 232 CameraBlocked "ACC FCW limited functionality: camera blocked; True = [1]";
CM_ SG_ 232 CameraFailure "ACC/FCW limited functionality: camera failure; True = [1]";
CM_ SG_ 232 ObjIntrstDist "Object of interest distance";
CM_ SG_ 232 Sm_ICON_Dspl "Small graphic display";
CM_ SG_ 712 EC_ECUCfg19_Stat "ECU Configuration messages status 19";
CM_ SG_ 712 EC_CBC19A "CBC ecu configuration 19A";
CM_ SG_ 712 EC_CBC19B "CBC ecu configuration 19B";
CM_ SG_ 809 EC_BU_ECUCfg19_Stat "Backup for ECU Configuration messages status 19";
CM_ SG_ 809 EC_BU_CBC19A "Backup for CBC ecu configuration 19A";
CM_ SG_ 809 EC_BU_CBC19B "Backup for CBC ecu configuration 19B";
CM_ SG_ 827 MtrA_Temp_EDR "Motor A temperature";
CM_ SG_ 827 MtrA_RPM_EDR "Motor A Speed Raw";
CM_ SG_ 827 MtrA_TorqAchieved_EDR "Motor A Torque Achieved";
CM_ SG_ 828 MtrB_RPM_EDR "Motor B Speed Raw";
CM_ SG_ 828 MtrB_TorqAchieved_EDR "Motor B Torque Achieved";
CM_ SG_ 828 MtrB_Temp_EDR "Motor B temperature";
CM_ SG_ 34 AccPos_PT "Accelerator Effective Position";
CM_ SG_ 34 MC_PT_SYSTEM_1 "Message counter";
CM_ SG_ 34 CRC_PT_SYSTEM_1 "CRC-checksum byte 1 to 7 according to SAE J1850";
CM_ SG_ 34 Hyb_SumTorqueMin_PT "Minimum sum torque (tactical limit)";
CM_ SG_ 34 AccPosV_PT "Accelerator effective position validity";
CM_ SG_ 34 RawPVS1_PT "Raw Pedal Voltage - Sensor 1";
CM_ SG_ 34 RawPVS2_PT "Raw Pedal Voltage - Sensor 2";
CM_ SG_ 34 ActlAccelPdlPosn_PT "Accelerator Pedal Position (actual)";
CM_ SG_ 34 Warn_BTO_PT "Brake Throttle Override status";
CM_ SG_ 34 CRUISE_OVERRIDE_PT "Driver is over-riding cruise set speed";
CM_ SG_ 34 EngTrq_Enbl_Rq_ESC_PT "Allow ESC torque request";
CM_ SG_ 34 EngTrq_Enbl_Rq_AS_PT "Allow LCM torque requests";
CM_ SG_ 2026 D_RS_EVCU2 "Diagnostic-Response";
CM_ SG_ 1594 SD_RS_EVCU2 "Response on Event - light";
CM_ SG_ 2018 D_RQ_EVCU2 "Diagnostic-Request";
CM_ SG_ 1466 ECU_APPL_EVCU2 "ECU to External Application";
CM_ SG_ 1786 APPL_ECU_EVCU2 "External Application to ECU";
CM_ SG_ 1082 NM_Mode "Network management mode";
CM_ SG_ 1082 NM_Sleep_Ack "Network management sleep acknowledge; True = [1]";
CM_ SG_ 1082 Nw_Id "Network identification no.";
CM_ SG_ 1082 NM_Successor "Network management logical successor";
CM_ SG_ 1082 NM_Ud_Launch "Network management userdata launch type";
CM_ SG_ 1082 NM_Sleep_Ind "Network management sleep indication; True = [1]";
CM_ SG_ 1082 NM_Ud_Srv "Network management userdata service no.";
CM_ SG_ 1082 WakeupRsn_EVCU2 "Wakeup reason EVCU2";
CM_ SG_ 1082 Awake_Chg_ST "Stay awake for charging status indiaction; True = [1]";
CM_ SG_ 1082 Awake_OBCM_WU "Stay awake for OBCM wakeup; True = [1]";
CM_ SG_ 1082 Awake_Diag_Actv "Stay awake for diagnostics active; True = [1]";
CM_ SG_ 1082 Awake_NwSt "Stay awake for network startup; True = [1]";
CM_ SG_ 1082 WakeupCnt "Counter for module wakeup states during network sleep";
CM_ SG_ 1268 D_RS_MCPB "Diagnostic-Response";
BA_DEF_ BO_  "App-Botschaft" ENUM  "nein","ja";
BA_DEF_ BO_  "CanMsgMinLen" INT 0 8;
BA_DEF_ BO_  "DiagRequest" ENUM  "nein","ja";
BA_DEF_ BO_  "DiagResponse" ENUM  "nein","ja";
BA_DEF_ BO_  "DiagState" ENUM  "nein","ja";
BA_DEF_ BO_  "GenMsgCycleTime" INT 0 65535;
BA_DEF_ BO_  "GenMsgCycleTimeActive" INT 0 65535;
BA_DEF_ BO_  "GenMsgDelayTime" INT 0 65535;
BA_DEF_ BO_  "GenMsgNrOfRepetitions" INT 0 65535;
BA_DEF_ BO_  "GenMsgSendType" ENUM  "cyclicX","spontanX","cyclicIfActiveX","spontanWithDelay","cyclicAndSpontanX","cyclicAndSpontanWithDelay","spontanWithRepitition","cyclicIfActiveAndSpontanWD","cyclicIfActiveFast","cyclicWithRepeatOnDemand","none";
BA_DEF_ BO_  "GenMsgStartDelayTime" INT 0 65535;
BA_DEF_ BO_  "GenMsgStartValue" STRING ;
BA_DEF_ BO_  "NWM-Botschaft" ENUM  "nein","ja";
BA_DEF_ BO_  "TpTxIndex" INT 0 99;
BA_DEF_ SG_  "FlexKomComment" STRING ;
BA_DEF_ SG_  "FlexKomIsMotorola" ENUM  "nein","ja";
BA_DEF_ SG_  "FlexKomSID" INT 0 2147483647;
BA_DEF_ SG_  "FlexKomSigLaenge" INT 0 64;
BA_DEF_ SG_  "FlexKomSigName" STRING ;
BA_DEF_ SG_  "FlexKomSigStartPos" INT 0 63;
BA_DEF_ SG_  "FlexKomSigStartValue" STRING ;
BA_DEF_ SG_  "GenSigCycleTime" INT 0 65535;
BA_DEF_ SG_  "GenSigCycleTimeActive" INT 0 65535;
BA_DEF_ SG_  "GenSigSendType" ENUM  "cyclicX","spontanX","cyclicIfActiveX","spontanWithDelay","cyclicAndSpontanX","cyclicAndSpontanWithDelay","spontanWithRepitition","cyclicIfActiveAndSpontanWD","cyclicIfActiveFast","cyclicWithRepeatOnDemand","none";
BA_DEF_ SG_  "GenSigSNA" STRING ;
BA_DEF_ SG_  "GenSigStartValue" HEX 0 2147483648;
BA_DEF_ SG_  "GenSigTimeout_AHLM" INT 0 65535;
BA_DEF_ SG_  "GenSigTimeout_ASBS" INT 0 65535;
BA_DEF_ SG_  "GenSigTimeout_CBC" INT 0 65535;
BA_DEF_ SG_  "GenSigTimeout_DPDM" INT 0 65535;
BA_DEF_ SG_  "GenSigTimeout_DTCM" INT 0 65535;
BA_DEF_ SG_  "GenSigTimeout_EHPS" INT 0 65535;
BA_DEF_ SG_  "GenSigTimeout_ESC" INT 0 65535;
BA_DEF_ SG_  "GenSigTimeout_ESL" INT 0 65535;
BA_DEF_ SG_  "GenSigTimeout_ESM" INT 0 65535;
BA_DEF_ SG_  "GenSigTimeout_ETM" INT 0 65535;
BA_DEF_ SG_  "GenSigTimeout_IC" INT 0 65535;
BA_DEF_ SG_  "GenSigTimeout_OCM" INT 0 65535;
BA_DEF_ SG_  "GenSigTimeout_ORC" INT 0 65535;
BA_DEF_ SG_  "GenSigTimeout_PTS" INT 0 65535;
BA_DEF_ SG_  "GenSigTimeout_RF_HUB" INT 0 65535;
BA_DEF_ SG_  "GenSigTimeout_SCCM" INT 0 65535;
BA_DEF_ SG_  "GenSigTimeout_TBM" INT 0 65535;
BA_DEF_ SG_  "GenSigTimeout_TCM" INT 0 65535;
BA_DEF_ SG_  "GenSigTimeout_TPM" INT 0 65535;
BA_DEF_ SG_  "RID" STRING ;
BA_DEF_ SG_  "SystemSignalLongSymbol" STRING ;
BA_DEF_DEF_  "App-Botschaft" "nein";
BA_DEF_DEF_  "CanMsgMinLen" 0;
BA_DEF_DEF_  "DiagRequest" "nein";
BA_DEF_DEF_  "DiagResponse" "nein";
BA_DEF_DEF_  "DiagState" "nein";
BA_DEF_DEF_  "GenMsgCycleTime" 0;
BA_DEF_DEF_  "GenMsgCycleTimeActive" 0;
BA_DEF_DEF_  "GenMsgDelayTime" 0;
BA_DEF_DEF_  "GenMsgNrOfRepetitions" 0;
BA_DEF_DEF_  "GenMsgSendType" "cyclicX";
BA_DEF_DEF_  "GenMsgStartDelayTime" 0;
BA_DEF_DEF_  "GenMsgStartValue" "";
BA_DEF_DEF_  "NWM-Botschaft" "nein";
BA_DEF_DEF_  "TpTxIndex" 0;
BA_DEF_DEF_  "FlexKomComment" "";
BA_DEF_DEF_  "FlexKomIsMotorola" "nein";
BA_DEF_DEF_  "FlexKomSID" 0;
BA_DEF_DEF_  "FlexKomSigLaenge" 0;
BA_DEF_DEF_  "FlexKomSigName" "";
BA_DEF_DEF_  "FlexKomSigStartPos" 0;
BA_DEF_DEF_  "FlexKomSigStartValue" "";
BA_DEF_DEF_  "GenSigCycleTime" 0;
BA_DEF_DEF_  "GenSigCycleTimeActive" 0;
BA_DEF_DEF_  "GenSigSendType" "cyclicX";
BA_DEF_DEF_  "GenSigSNA" "";
BA_DEF_DEF_  "GenSigStartValue" 0;
BA_DEF_DEF_  "GenSigTimeout_AHLM" 0;
BA_DEF_DEF_  "GenSigTimeout_ASBS" 0;
BA_DEF_DEF_  "GenSigTimeout_CBC" 0;
BA_DEF_DEF_  "GenSigTimeout_DPDM" 0;
BA_DEF_DEF_  "GenSigTimeout_DTCM" 0;
BA_DEF_DEF_  "GenSigTimeout_EHPS" 0;
BA_DEF_DEF_  "GenSigTimeout_ESC" 0;
BA_DEF_DEF_  "GenSigTimeout_ESL" 0;
BA_DEF_DEF_  "GenSigTimeout_ESM" 0;
BA_DEF_DEF_  "GenSigTimeout_ETM" 0;
BA_DEF_DEF_  "GenSigTimeout_IC" 0;
BA_DEF_DEF_  "GenSigTimeout_OCM" 0;
BA_DEF_DEF_  "GenSigTimeout_ORC" 0;
BA_DEF_DEF_  "GenSigTimeout_PTS" 0;
BA_DEF_DEF_  "GenSigTimeout_RF_HUB" 0;
BA_DEF_DEF_  "GenSigTimeout_SCCM" 0;
BA_DEF_DEF_  "GenSigTimeout_TBM" 0;
BA_DEF_DEF_  "GenSigTimeout_TCM" 0;
BA_DEF_DEF_  "GenSigTimeout_TPM" 0;
BA_DEF_DEF_  "RID" "";
BA_DEF_DEF_  "SystemSignalLongSymbol" "";
BA_ "GenMsgStartValue" BO_ 1266 "0000000000000000h";
BA_ "GenMsgSendType" BO_ 1266 1;
BA_ "GenMsgNrOfRepetitions" BO_ 1266 2;
BA_ "GenMsgDelayTime" BO_ 1266 20;
BA_ "DiagResponse" BO_ 1266 1;
BA_ "GenMsgStartValue" BO_ 1284 "0000000000000000h";
BA_ "GenMsgSendType" BO_ 1284 1;
BA_ "GenMsgNrOfRepetitions" BO_ 1284 2;
BA_ "GenMsgDelayTime" BO_ 1284 20;
BA_ "DiagResponse" BO_ 1284 1;
BA_ "GenMsgStartValue" BO_ 1323 "0000000000000000h";
BA_ "GenMsgSendType" BO_ 1323 1;
BA_ "GenMsgNrOfRepetitions" BO_ 1323 2;
BA_ "GenMsgDelayTime" BO_ 1323 20;
BA_ "DiagResponse" BO_ 1323 1;
BA_ "GenMsgStartValue" BO_ 1408 "0000000000000000h";
BA_ "GenMsgSendType" BO_ 1408 1;
BA_ "GenMsgNrOfRepetitions" BO_ 1408 2;
BA_ "GenMsgDelayTime" BO_ 1408 20;
BA_ "App-Botschaft" BO_ 1408 1;
BA_ "GenMsgStartValue" BO_ 1409 "0000000000000000h";
BA_ "GenMsgSendType" BO_ 1409 1;
BA_ "GenMsgNrOfRepetitions" BO_ 1409 2;
BA_ "GenMsgDelayTime" BO_ 1409 20;
BA_ "App-Botschaft" BO_ 1409 1;
BA_ "GenMsgStartValue" BO_ 1410 "0000000000000000h";
BA_ "GenMsgSendType" BO_ 1410 1;
BA_ "GenMsgNrOfRepetitions" BO_ 1410 2;
BA_ "GenMsgDelayTime" BO_ 1410 20;
BA_ "App-Botschaft" BO_ 1410 1;
BA_ "GenMsgStartValue" BO_ 1412 "0000000000000000h";
BA_ "GenMsgSendType" BO_ 1412 1;
BA_ "GenMsgNrOfRepetitions" BO_ 1412 2;
BA_ "GenMsgDelayTime" BO_ 1412 20;
BA_ "App-Botschaft" BO_ 1412 1;
BA_ "GenMsgStartValue" BO_ 1415 "0000000000000000h";
BA_ "GenMsgSendType" BO_ 1415 1;
BA_ "GenMsgNrOfRepetitions" BO_ 1415 2;
BA_ "GenMsgDelayTime" BO_ 1415 20;
BA_ "App-Botschaft" BO_ 1415 1;
BA_ "GenMsgStartValue" BO_ 1416 "0000000000000000h";
BA_ "GenMsgSendType" BO_ 1416 1;
BA_ "GenMsgNrOfRepetitions" BO_ 1416 2;
BA_ "GenMsgDelayTime" BO_ 1416 20;
BA_ "App-Botschaft" BO_ 1416 1;
BA_ "GenMsgStartValue" BO_ 1417 "0000000000000000h";
BA_ "GenMsgSendType" BO_ 1417 1;
BA_ "GenMsgNrOfRepetitions" BO_ 1417 2;
BA_ "GenMsgDelayTime" BO_ 1417 20;
BA_ "App-Botschaft" BO_ 1417 1;
BA_ "GenMsgStartValue" BO_ 1418 "0000000000000000h";
BA_ "GenMsgSendType" BO_ 1418 1;
BA_ "GenMsgNrOfRepetitions" BO_ 1418 2;
BA_ "GenMsgDelayTime" BO_ 1418 20;
BA_ "App-Botschaft" BO_ 1418 1;
BA_ "GenMsgStartValue" BO_ 1419 "0000000000000000h";
BA_ "GenMsgSendType" BO_ 1419 1;
BA_ "GenMsgNrOfRepetitions" BO_ 1419 2;
BA_ "GenMsgDelayTime" BO_ 1419 20;
BA_ "App-Botschaft" BO_ 1419 1;
BA_ "GenMsgStartValue" BO_ 1425 "0000000000000000h";
BA_ "GenMsgSendType" BO_ 1425 1;
BA_ "GenMsgNrOfRepetitions" BO_ 1425 2;
BA_ "GenMsgDelayTime" BO_ 1425 20;
BA_ "App-Botschaft" BO_ 1425 1;
BA_ "GenMsgStartValue" BO_ 1427 "0000000000000000h";
BA_ "GenMsgSendType" BO_ 1427 1;
BA_ "GenMsgNrOfRepetitions" BO_ 1427 2;
BA_ "GenMsgDelayTime" BO_ 1427 20;
BA_ "App-Botschaft" BO_ 1427 1;
BA_ "GenMsgStartValue" BO_ 1434 "0000000000000000h";
BA_ "GenMsgSendType" BO_ 1434 1;
BA_ "GenMsgNrOfRepetitions" BO_ 1434 2;
BA_ "GenMsgDelayTime" BO_ 1434 20;
BA_ "App-Botschaft" BO_ 1434 1;
BA_ "GenMsgStartValue" BO_ 1438 "0000000000000000h";
BA_ "GenMsgSendType" BO_ 1438 1;
BA_ "GenMsgNrOfRepetitions" BO_ 1438 2;
BA_ "GenMsgDelayTime" BO_ 1438 20;
BA_ "App-Botschaft" BO_ 1438 1;
BA_ "GenMsgStartValue" BO_ 1442 "0000000000000000h";
BA_ "GenMsgSendType" BO_ 1442 1;
BA_ "GenMsgNrOfRepetitions" BO_ 1442 2;
BA_ "GenMsgDelayTime" BO_ 1442 20;
BA_ "App-Botschaft" BO_ 1442 1;
BA_ "GenMsgStartValue" BO_ 1443 "0000000000000000h";
BA_ "GenMsgSendType" BO_ 1443 1;
BA_ "GenMsgNrOfRepetitions" BO_ 1443 2;
BA_ "GenMsgDelayTime" BO_ 1443 20;
BA_ "App-Botschaft" BO_ 1443 1;
BA_ "GenMsgStartValue" BO_ 1449 "0000000000000000h";
BA_ "GenMsgSendType" BO_ 1449 1;
BA_ "GenMsgNrOfRepetitions" BO_ 1449 2;
BA_ "GenMsgDelayTime" BO_ 1449 20;
BA_ "App-Botschaft" BO_ 1449 1;
BA_ "GenMsgStartValue" BO_ 1464 "0000000000000000h";
BA_ "GenMsgSendType" BO_ 1464 1;
BA_ "GenMsgNrOfRepetitions" BO_ 1464 2;
BA_ "GenMsgDelayTime" BO_ 1464 20;
BA_ "App-Botschaft" BO_ 1464 1;
BA_ "GenMsgStartValue" BO_ 1465 "0000000000000000h";
BA_ "GenMsgSendType" BO_ 1465 1;
BA_ "GenMsgNrOfRepetitions" BO_ 1465 2;
BA_ "GenMsgDelayTime" BO_ 1465 20;
BA_ "App-Botschaft" BO_ 1465 1;
BA_ "GenMsgStartValue" BO_ 1468 "0000000000000000h";
BA_ "GenMsgSendType" BO_ 1468 1;
BA_ "GenMsgNrOfRepetitions" BO_ 1468 2;
BA_ "GenMsgDelayTime" BO_ 1468 20;
BA_ "App-Botschaft" BO_ 1468 1;
BA_ "GenMsgStartValue" BO_ 1515 "0000000000000000h";
BA_ "GenMsgSendType" BO_ 1515 1;
BA_ "GenMsgNrOfRepetitions" BO_ 1515 2;
BA_ "GenMsgDelayTime" BO_ 1515 20;
BA_ "App-Botschaft" BO_ 1515 1;
BA_ "GenMsgStartValue" BO_ 1536 "0000000000000000h";
BA_ "GenMsgStartDelayTime" BO_ 1536 800;
BA_ "GenMsgSendType" BO_ 1536 9;
BA_ "GenMsgDelayTime" BO_ 1536 200;
BA_ "GenMsgCycleTime" BO_ 1536 200;
BA_ "GenMsgStartValue" BO_ 1537 "0000000000000000h";
BA_ "GenMsgStartDelayTime" BO_ 1537 810;
BA_ "GenMsgSendType" BO_ 1537 9;
BA_ "GenMsgDelayTime" BO_ 1537 200;
BA_ "GenMsgCycleTime" BO_ 1537 200;
BA_ "GenMsgStartValue" BO_ 1538 "0000000000000000h";
BA_ "GenMsgStartDelayTime" BO_ 1538 820;
BA_ "GenMsgSendType" BO_ 1538 9;
BA_ "GenMsgDelayTime" BO_ 1538 200;
BA_ "GenMsgCycleTime" BO_ 1538 200;
BA_ "GenMsgStartValue" BO_ 1540 "0000000000000000h";
BA_ "GenMsgStartDelayTime" BO_ 1540 800;
BA_ "GenMsgSendType" BO_ 1540 9;
BA_ "GenMsgDelayTime" BO_ 1540 200;
BA_ "GenMsgCycleTime" BO_ 1540 200;
BA_ "GenMsgStartValue" BO_ 1543 "0000000000000000h";
BA_ "GenMsgStartDelayTime" BO_ 1543 870;
BA_ "GenMsgSendType" BO_ 1543 9;
BA_ "GenMsgDelayTime" BO_ 1543 200;
BA_ "GenMsgCycleTime" BO_ 1543 200;
BA_ "GenMsgStartValue" BO_ 1544 "0000000000000000h";
BA_ "GenMsgStartDelayTime" BO_ 1544 880;
BA_ "GenMsgSendType" BO_ 1544 9;
BA_ "GenMsgDelayTime" BO_ 1544 200;
BA_ "GenMsgCycleTime" BO_ 1544 200;
BA_ "GenMsgStartValue" BO_ 1545 "0000000000000000h";
BA_ "GenMsgStartDelayTime" BO_ 1545 890;
BA_ "GenMsgSendType" BO_ 1545 9;
BA_ "GenMsgDelayTime" BO_ 1545 200;
BA_ "GenMsgCycleTime" BO_ 1545 200;
BA_ "GenMsgStartValue" BO_ 1546 "0000000000000000h";
BA_ "GenMsgStartDelayTime" BO_ 1546 800;
BA_ "GenMsgSendType" BO_ 1546 9;
BA_ "GenMsgDelayTime" BO_ 1546 200;
BA_ "GenMsgCycleTime" BO_ 1546 200;
BA_ "GenMsgStartValue" BO_ 1547 "0000000000000000h";
BA_ "GenMsgStartDelayTime" BO_ 1547 800;
BA_ "GenMsgSendType" BO_ 1547 9;
BA_ "GenMsgDelayTime" BO_ 1547 200;
BA_ "GenMsgCycleTime" BO_ 1547 200;
BA_ "GenMsgStartValue" BO_ 1553 "0000000000000000h";
BA_ "GenMsgStartDelayTime" BO_ 1553 800;
BA_ "GenMsgSendType" BO_ 1553 9;
BA_ "GenMsgDelayTime" BO_ 1553 200;
BA_ "GenMsgCycleTime" BO_ 1553 200;
BA_ "GenMsgStartValue" BO_ 1555 "0000000000000000h";
BA_ "GenMsgStartDelayTime" BO_ 1555 800;
BA_ "GenMsgSendType" BO_ 1555 9;
BA_ "GenMsgDelayTime" BO_ 1555 200;
BA_ "GenMsgCycleTime" BO_ 1555 200;
BA_ "GenMsgStartValue" BO_ 1562 "0000000000000000h";
BA_ "GenMsgStartDelayTime" BO_ 1562 860;
BA_ "GenMsgSendType" BO_ 1562 9;
BA_ "GenMsgDelayTime" BO_ 1562 200;
BA_ "GenMsgCycleTime" BO_ 1562 200;
BA_ "GenMsgStartValue" BO_ 1566 "0000000000000000h";
BA_ "GenMsgStartDelayTime" BO_ 1566 800;
BA_ "GenMsgSendType" BO_ 1566 9;
BA_ "GenMsgDelayTime" BO_ 1566 200;
BA_ "GenMsgCycleTime" BO_ 1566 200;
BA_ "GenMsgStartValue" BO_ 1568 "0000000000000000h";
BA_ "GenMsgSendType" BO_ 1568 1;
BA_ "GenMsgNrOfRepetitions" BO_ 1568 2;
BA_ "GenMsgDelayTime" BO_ 1568 20;
BA_ "DiagRequest" BO_ 1568 1;
BA_ "GenMsgStartValue" BO_ 1570 "0000000000000000h";
BA_ "GenMsgStartDelayTime" BO_ 1570 800;
BA_ "GenMsgSendType" BO_ 1570 9;
BA_ "GenMsgDelayTime" BO_ 1570 200;
BA_ "GenMsgCycleTime" BO_ 1570 200;
BA_ "GenMsgStartValue" BO_ 1571 "0000000000000000h";
BA_ "GenMsgStartDelayTime" BO_ 1571 950;
BA_ "GenMsgSendType" BO_ 1571 9;
BA_ "GenMsgDelayTime" BO_ 1571 200;
BA_ "GenMsgCycleTime" BO_ 1571 200;
BA_ "GenMsgStartValue" BO_ 1577 "0000000000000000h";
BA_ "GenMsgStartDelayTime" BO_ 1577 800;
BA_ "GenMsgSendType" BO_ 1577 9;
BA_ "GenMsgDelayTime" BO_ 1577 200;
BA_ "GenMsgCycleTime" BO_ 1577 200;
BA_ "GenMsgStartValue" BO_ 1586 "0000000000000000h";
BA_ "GenMsgStartDelayTime" BO_ 1586 860;
BA_ "GenMsgSendType" BO_ 1586 9;
BA_ "GenMsgDelayTime" BO_ 1586 200;
BA_ "GenMsgCycleTime" BO_ 1586 200;
BA_ "GenMsgStartValue" BO_ 1592 "0000000000000000h";
BA_ "GenMsgStartDelayTime" BO_ 1592 800;
BA_ "GenMsgSendType" BO_ 1592 9;
BA_ "GenMsgDelayTime" BO_ 1592 200;
BA_ "GenMsgCycleTime" BO_ 1592 200;
BA_ "GenMsgStartValue" BO_ 1593 "0000000000000000h";
BA_ "GenMsgStartDelayTime" BO_ 1593 800;
BA_ "GenMsgSendType" BO_ 1593 9;
BA_ "GenMsgDelayTime" BO_ 1593 200;
BA_ "GenMsgCycleTime" BO_ 1593 200;
BA_ "GenMsgStartValue" BO_ 1596 "0000000000000000h";
BA_ "GenMsgStartDelayTime" BO_ 1596 870;
BA_ "GenMsgSendType" BO_ 1596 9;
BA_ "GenMsgDelayTime" BO_ 1596 200;
BA_ "GenMsgCycleTime" BO_ 1596 200;
BA_ "GenMsgStartValue" BO_ 1643 "0000000000000000h";
BA_ "GenMsgStartDelayTime" BO_ 1643 830;
BA_ "GenMsgSendType" BO_ 1643 9;
BA_ "GenMsgDelayTime" BO_ 1643 200;
BA_ "GenMsgCycleTime" BO_ 1643 200;
BA_ "GenMsgStartValue" BO_ 1728 "0000000000000000h";
BA_ "GenMsgSendType" BO_ 1728 1;
BA_ "GenMsgNrOfRepetitions" BO_ 1728 2;
BA_ "GenMsgDelayTime" BO_ 1728 20;
BA_ "App-Botschaft" BO_ 1728 1;
BA_ "GenMsgStartValue" BO_ 1729 "0000000000000000h";
BA_ "GenMsgSendType" BO_ 1729 1;
BA_ "GenMsgNrOfRepetitions" BO_ 1729 2;
BA_ "GenMsgDelayTime" BO_ 1729 20;
BA_ "App-Botschaft" BO_ 1729 1;
BA_ "GenMsgStartValue" BO_ 1730 "0000000000000000h";
BA_ "GenMsgSendType" BO_ 1730 1;
BA_ "GenMsgNrOfRepetitions" BO_ 1730 2;
BA_ "GenMsgDelayTime" BO_ 1730 20;
BA_ "App-Botschaft" BO_ 1730 1;
BA_ "GenMsgStartValue" BO_ 1732 "0000000000000000h";
BA_ "GenMsgSendType" BO_ 1732 1;
BA_ "GenMsgNrOfRepetitions" BO_ 1732 2;
BA_ "GenMsgDelayTime" BO_ 1732 20;
BA_ "App-Botschaft" BO_ 1732 1;
BA_ "GenMsgStartValue" BO_ 1735 "0000000000000000h";
BA_ "GenMsgSendType" BO_ 1735 1;
BA_ "GenMsgNrOfRepetitions" BO_ 1735 2;
BA_ "GenMsgDelayTime" BO_ 1735 20;
BA_ "App-Botschaft" BO_ 1735 1;
BA_ "GenMsgStartValue" BO_ 1736 "0000000000000000h";
BA_ "GenMsgSendType" BO_ 1736 1;
BA_ "GenMsgNrOfRepetitions" BO_ 1736 2;
BA_ "GenMsgDelayTime" BO_ 1736 20;
BA_ "App-Botschaft" BO_ 1736 1;
BA_ "GenMsgStartValue" BO_ 1737 "0000000000000000h";
BA_ "GenMsgSendType" BO_ 1737 1;
BA_ "GenMsgNrOfRepetitions" BO_ 1737 2;
BA_ "GenMsgDelayTime" BO_ 1737 20;
BA_ "App-Botschaft" BO_ 1737 1;
BA_ "GenMsgStartValue" BO_ 1738 "0000000000000000h";
BA_ "GenMsgSendType" BO_ 1738 1;
BA_ "GenMsgNrOfRepetitions" BO_ 1738 2;
BA_ "GenMsgDelayTime" BO_ 1738 20;
BA_ "App-Botschaft" BO_ 1738 1;
BA_ "GenMsgStartValue" BO_ 1739 "0000000000000000h";
BA_ "GenMsgSendType" BO_ 1739 1;
BA_ "GenMsgNrOfRepetitions" BO_ 1739 2;
BA_ "GenMsgDelayTime" BO_ 1739 20;
BA_ "App-Botschaft" BO_ 1739 1;
BA_ "GenMsgStartValue" BO_ 1745 "0000000000000000h";
BA_ "GenMsgSendType" BO_ 1745 1;
BA_ "GenMsgNrOfRepetitions" BO_ 1745 2;
BA_ "GenMsgDelayTime" BO_ 1745 20;
BA_ "App-Botschaft" BO_ 1745 1;
BA_ "GenMsgStartValue" BO_ 1747 "0000000000000000h";
BA_ "GenMsgSendType" BO_ 1747 1;
BA_ "GenMsgNrOfRepetitions" BO_ 1747 2;
BA_ "GenMsgDelayTime" BO_ 1747 20;
BA_ "App-Botschaft" BO_ 1747 1;
BA_ "GenMsgStartValue" BO_ 1754 "0000000000000000h";
BA_ "GenMsgSendType" BO_ 1754 1;
BA_ "GenMsgNrOfRepetitions" BO_ 1754 2;
BA_ "GenMsgDelayTime" BO_ 1754 20;
BA_ "App-Botschaft" BO_ 1754 1;
BA_ "GenMsgStartValue" BO_ 1758 "0000000000000000h";
BA_ "GenMsgSendType" BO_ 1758 1;
BA_ "GenMsgNrOfRepetitions" BO_ 1758 2;
BA_ "GenMsgDelayTime" BO_ 1758 20;
BA_ "App-Botschaft" BO_ 1758 1;
BA_ "GenMsgStartValue" BO_ 1762 "0000000000000000h";
BA_ "GenMsgSendType" BO_ 1762 1;
BA_ "GenMsgNrOfRepetitions" BO_ 1762 2;
BA_ "GenMsgDelayTime" BO_ 1762 20;
BA_ "App-Botschaft" BO_ 1762 1;
BA_ "GenMsgStartValue" BO_ 1763 "0000000000000000h";
BA_ "GenMsgSendType" BO_ 1763 1;
BA_ "GenMsgNrOfRepetitions" BO_ 1763 2;
BA_ "GenMsgDelayTime" BO_ 1763 20;
BA_ "App-Botschaft" BO_ 1763 1;
BA_ "GenMsgStartValue" BO_ 1769 "0000000000000000h";
BA_ "GenMsgSendType" BO_ 1769 1;
BA_ "GenMsgNrOfRepetitions" BO_ 1769 2;
BA_ "GenMsgDelayTime" BO_ 1769 20;
BA_ "App-Botschaft" BO_ 1769 1;
BA_ "GenMsgStartValue" BO_ 1784 "0000000000000000h";
BA_ "GenMsgSendType" BO_ 1784 1;
BA_ "GenMsgNrOfRepetitions" BO_ 1784 2;
BA_ "GenMsgDelayTime" BO_ 1784 20;
BA_ "App-Botschaft" BO_ 1784 1;
BA_ "GenMsgStartValue" BO_ 1785 "0000000000000000h";
BA_ "GenMsgSendType" BO_ 1785 1;
BA_ "GenMsgNrOfRepetitions" BO_ 1785 2;
BA_ "GenMsgDelayTime" BO_ 1785 20;
BA_ "App-Botschaft" BO_ 1785 1;
BA_ "GenMsgStartValue" BO_ 1788 "0000000000000000h";
BA_ "GenMsgSendType" BO_ 1788 1;
BA_ "GenMsgNrOfRepetitions" BO_ 1788 2;
BA_ "GenMsgDelayTime" BO_ 1788 20;
BA_ "App-Botschaft" BO_ 1788 1;
BA_ "GenMsgStartValue" BO_ 1835 "0000000000000000h";
BA_ "GenMsgSendType" BO_ 1835 1;
BA_ "GenMsgNrOfRepetitions" BO_ 1835 2;
BA_ "GenMsgDelayTime" BO_ 1835 20;
BA_ "App-Botschaft" BO_ 1835 1;
BA_ "GenMsgStartValue" BO_ 1856 "0000000000000000h";
BA_ "GenMsgSendType" BO_ 1856 1;
BA_ "GenMsgNrOfRepetitions" BO_ 1856 2;
BA_ "GenMsgDelayTime" BO_ 1856 20;
BA_ "DiagRequest" BO_ 1856 1;
BA_ "GenMsgStartValue" BO_ 1858 "0000000000000000h";
BA_ "GenMsgSendType" BO_ 1858 1;
BA_ "GenMsgNrOfRepetitions" BO_ 1858 2;
BA_ "GenMsgDelayTime" BO_ 1858 20;
BA_ "DiagRequest" BO_ 1858 1;
BA_ "GenMsgStartValue" BO_ 1860 "0000000000000000h";
BA_ "GenMsgSendType" BO_ 1860 1;
BA_ "GenMsgNrOfRepetitions" BO_ 1860 2;
BA_ "GenMsgDelayTime" BO_ 1860 20;
BA_ "DiagRequest" BO_ 1860 1;
BA_ "GenMsgStartValue" BO_ 1863 "0000000000000000h";
BA_ "GenMsgSendType" BO_ 1863 1;
BA_ "GenMsgNrOfRepetitions" BO_ 1863 2;
BA_ "GenMsgDelayTime" BO_ 1863 20;
BA_ "DiagRequest" BO_ 1863 1;
BA_ "GenMsgStartValue" BO_ 1864 "0000000000000000h";
BA_ "GenMsgSendType" BO_ 1864 1;
BA_ "GenMsgNrOfRepetitions" BO_ 1864 2;
BA_ "GenMsgDelayTime" BO_ 1864 20;
BA_ "DiagRequest" BO_ 1864 1;
BA_ "GenMsgStartValue" BO_ 1865 "0000000000000000h";
BA_ "GenMsgSendType" BO_ 1865 1;
BA_ "GenMsgNrOfRepetitions" BO_ 1865 2;
BA_ "GenMsgDelayTime" BO_ 1865 20;
BA_ "DiagRequest" BO_ 1865 1;
BA_ "GenMsgStartValue" BO_ 1866 "0000000000000000h";
BA_ "GenMsgSendType" BO_ 1866 1;
BA_ "GenMsgNrOfRepetitions" BO_ 1866 2;
BA_ "GenMsgDelayTime" BO_ 1866 20;
BA_ "DiagRequest" BO_ 1866 1;
BA_ "GenMsgStartValue" BO_ 1867 "0000000000000000h";
BA_ "GenMsgSendType" BO_ 1867 1;
BA_ "GenMsgNrOfRepetitions" BO_ 1867 2;
BA_ "GenMsgDelayTime" BO_ 1867 20;
BA_ "DiagRequest" BO_ 1867 1;
BA_ "GenMsgStartValue" BO_ 1873 "0000000000000000h";
BA_ "GenMsgSendType" BO_ 1873 1;
BA_ "GenMsgNrOfRepetitions" BO_ 1873 2;
BA_ "GenMsgDelayTime" BO_ 1873 20;
BA_ "DiagRequest" BO_ 1873 1;
BA_ "GenMsgStartValue" BO_ 1875 "0000000000000000h";
BA_ "GenMsgSendType" BO_ 1875 1;
BA_ "GenMsgNrOfRepetitions" BO_ 1875 2;
BA_ "GenMsgDelayTime" BO_ 1875 20;
BA_ "DiagRequest" BO_ 1875 1;
BA_ "GenMsgStartValue" BO_ 1882 "0000000000000000h";
BA_ "GenMsgSendType" BO_ 1882 1;
BA_ "GenMsgNrOfRepetitions" BO_ 1882 2;
BA_ "GenMsgDelayTime" BO_ 1882 20;
BA_ "DiagRequest" BO_ 1882 1;
BA_ "GenMsgStartValue" BO_ 1886 "0000000000000000h";
BA_ "GenMsgSendType" BO_ 1886 1;
BA_ "GenMsgNrOfRepetitions" BO_ 1886 2;
BA_ "GenMsgDelayTime" BO_ 1886 20;
BA_ "DiagRequest" BO_ 1886 1;
BA_ "GenMsgStartValue" BO_ 1890 "0000000000000000h";
BA_ "GenMsgSendType" BO_ 1890 1;
BA_ "GenMsgNrOfRepetitions" BO_ 1890 2;
BA_ "GenMsgDelayTime" BO_ 1890 20;
BA_ "DiagRequest" BO_ 1890 1;
BA_ "GenMsgStartValue" BO_ 1891 "0000000000000000h";
BA_ "GenMsgSendType" BO_ 1891 1;
BA_ "GenMsgNrOfRepetitions" BO_ 1891 2;
BA_ "GenMsgDelayTime" BO_ 1891 20;
BA_ "DiagRequest" BO_ 1891 1;
BA_ "GenMsgStartValue" BO_ 1897 "0000000000000000h";
BA_ "GenMsgSendType" BO_ 1897 1;
BA_ "GenMsgNrOfRepetitions" BO_ 1897 2;
BA_ "GenMsgDelayTime" BO_ 1897 20;
BA_ "DiagRequest" BO_ 1897 1;
BA_ "GenMsgStartValue" BO_ 1901 "0000000000000000h";
BA_ "GenMsgSendType" BO_ 1901 1;
BA_ "GenMsgNrOfRepetitions" BO_ 1901 2;
BA_ "GenMsgDelayTime" BO_ 1901 20;
BA_ "DiagRequest" BO_ 1901 1;
BA_ "GenMsgStartValue" BO_ 1906 "0000000000000000h";
BA_ "GenMsgSendType" BO_ 1906 1;
BA_ "GenMsgNrOfRepetitions" BO_ 1906 2;
BA_ "GenMsgDelayTime" BO_ 1906 20;
BA_ "DiagRequest" BO_ 1906 1;
BA_ "GenMsgStartValue" BO_ 1963 "0000000000000000h";
BA_ "GenMsgSendType" BO_ 1963 1;
BA_ "GenMsgNrOfRepetitions" BO_ 1963 2;
BA_ "GenMsgDelayTime" BO_ 1963 20;
BA_ "DiagRequest" BO_ 1963 1;
BA_ "GenMsgStartValue" BO_ 2015 "0000000000000000h";
BA_ "GenMsgNrOfRepetitions" BO_ 2015 2;
BA_ "GenMsgDelayTime" BO_ 2015 20;
BA_ "DiagState" BO_ 2015 1;
BA_ "GenMsgStartValue" BO_ 2016 "0000000000000000h";
BA_ "GenMsgSendType" BO_ 2016 1;
BA_ "GenMsgNrOfRepetitions" BO_ 2016 2;
BA_ "GenMsgDelayTime" BO_ 2016 20;
BA_ "DiagRequest" BO_ 2016 1;
BA_ "GenMsgStartValue" BO_ 2017 "0000000000000000h";
BA_ "GenMsgSendType" BO_ 2017 1;
BA_ "GenMsgNrOfRepetitions" BO_ 2017 2;
BA_ "GenMsgDelayTime" BO_ 2017 20;
BA_ "DiagRequest" BO_ 2017 1;
BA_ "GenMsgStartValue" BO_ 2020 "0000000000000000h";
BA_ "GenMsgSendType" BO_ 2020 1;
BA_ "GenMsgNrOfRepetitions" BO_ 2020 2;
BA_ "GenMsgDelayTime" BO_ 2020 20;
BA_ "DiagRequest" BO_ 2020 1;
BA_ "GenMsgStartValue" BO_ 2021 "0000000000000000h";
BA_ "GenMsgSendType" BO_ 2021 1;
BA_ "GenMsgNrOfRepetitions" BO_ 2021 2;
BA_ "GenMsgDelayTime" BO_ 2021 20;
BA_ "DiagRequest" BO_ 2021 1;
BA_ "GenMsgStartValue" BO_ 2023 "0000000000000000h";
BA_ "GenMsgSendType" BO_ 2023 1;
BA_ "GenMsgNrOfRepetitions" BO_ 2023 2;
BA_ "GenMsgDelayTime" BO_ 2023 20;
BA_ "DiagRequest" BO_ 2023 1;
BA_ "GenMsgStartValue" BO_ 2024 "0000000000000000h";
BA_ "GenMsgSendType" BO_ 2024 1;
BA_ "GenMsgNrOfRepetitions" BO_ 2024 2;
BA_ "GenMsgDelayTime" BO_ 2024 20;
BA_ "DiagResponse" BO_ 2024 1;
BA_ "GenMsgStartValue" BO_ 2025 "0000000000000000h";
BA_ "GenMsgSendType" BO_ 2025 1;
BA_ "GenMsgNrOfRepetitions" BO_ 2025 2;
BA_ "GenMsgDelayTime" BO_ 2025 20;
BA_ "DiagResponse" BO_ 2025 1;
BA_ "GenMsgStartValue" BO_ 2028 "0000000000000000h";
BA_ "GenMsgSendType" BO_ 2028 1;
BA_ "GenMsgNrOfRepetitions" BO_ 2028 2;
BA_ "GenMsgDelayTime" BO_ 2028 20;
BA_ "DiagResponse" BO_ 2028 1;
BA_ "GenMsgStartValue" BO_ 2029 "0000000000000000h";
BA_ "GenMsgSendType" BO_ 2029 1;
BA_ "GenMsgNrOfRepetitions" BO_ 2029 2;
BA_ "GenMsgDelayTime" BO_ 2029 20;
BA_ "DiagResponse" BO_ 2029 1;
BA_ "GenMsgStartValue" BO_ 2031 "0000000000000000h";
BA_ "GenMsgSendType" BO_ 2031 1;
BA_ "GenMsgNrOfRepetitions" BO_ 2031 2;
BA_ "GenMsgDelayTime" BO_ 2031 20;
BA_ "DiagResponse" BO_ 2031 1;
BA_ "GenMsgStartValue" BO_ 2047 "00h";
BA_ "GenMsgSendType" BO_ 2047 1;
BA_ "GenMsgNrOfRepetitions" BO_ 2047 2;
BA_ "GenMsgDelayTime" BO_ 2047 20;
BA_ "GenMsgStartValue" BO_ 966 "0300000000000000h";
BA_ "GenMsgStartDelayTime" BO_ 966 70;
BA_ "GenMsgSendType" BO_ 966 5;
BA_ "GenMsgNrOfRepetitions" BO_ 966 2;
BA_ "GenMsgDelayTime" BO_ 966 20;
BA_ "GenMsgCycleTime" BO_ 966 2000;
BA_ "GenMsgStartValue" BO_ 1040 "0300000000000000h";
BA_ "GenMsgSendType" BO_ 1040 1;
BA_ "GenMsgNrOfRepetitions" BO_ 1040 2;
BA_ "GenMsgDelayTime" BO_ 1040 20;
BA_ "GenMsgCycleTime" BO_ 1040 2000;
BA_ "GenMsgStartValue" BO_ 909 "0300000000000000h";
BA_ "GenMsgSendType" BO_ 909 5;
BA_ "GenMsgNrOfRepetitions" BO_ 909 2;
BA_ "GenMsgDelayTime" BO_ 909 20;
BA_ "GenMsgCycleTime" BO_ 909 2000;
BA_ "GenMsgStartValue" BO_ 915 "0300000000000000h";
BA_ "GenMsgSendType" BO_ 915 1;
BA_ "GenMsgNrOfRepetitions" BO_ 915 2;
BA_ "GenMsgDelayTime" BO_ 915 20;
BA_ "GenMsgStartValue" BO_ 232 "00FFFF00000000FFh";
BA_ "GenMsgSendType" BO_ 232 5;
BA_ "GenMsgNrOfRepetitions" BO_ 232 2;
BA_ "GenMsgDelayTime" BO_ 232 20;
BA_ "GenMsgCycleTime" BO_ 232 60;
BA_ "GenMsgStartValue" BO_ 712 "0300000000000000h";
BA_ "GenMsgSendType" BO_ 712 5;
BA_ "GenMsgNrOfRepetitions" BO_ 712 2;
BA_ "GenMsgDelayTime" BO_ 712 20;
BA_ "GenMsgCycleTime" BO_ 712 2000;
BA_ "GenMsgStartValue" BO_ 809 "0300000000000000h";
BA_ "GenMsgSendType" BO_ 809 1;
BA_ "GenMsgNrOfRepetitions" BO_ 809 2;
BA_ "GenMsgDelayTime" BO_ 809 20;
BA_ "GenMsgCycleTime" BO_ 809 2000;
BA_ "GenMsgStartValue" BO_ 827 "8000100028000000h";
BA_ "GenMsgNrOfRepetitions" BO_ 827 2;
BA_ "GenMsgDelayTime" BO_ 827 20;
BA_ "GenMsgCycleTime" BO_ 827 500;
BA_ "GenMsgStartValue" BO_ 828 "8000100028000000h";
BA_ "GenMsgNrOfRepetitions" BO_ 828 2;
BA_ "GenMsgDelayTime" BO_ 828 20;
BA_ "GenMsgCycleTime" BO_ 828 500;
BA_ "GenMsgStartValue" BO_ 34 "00000001F40000FFh";
BA_ "GenMsgNrOfRepetitions" BO_ 34 2;
BA_ "GenMsgDelayTime" BO_ 34 20;
BA_ "GenMsgCycleTime" BO_ 34 10;
BA_ "GenMsgStartValue" BO_ 2026 "0000000000000000h";
BA_ "GenMsgSendType" BO_ 2026 1;
BA_ "GenMsgNrOfRepetitions" BO_ 2026 2;
BA_ "GenMsgDelayTime" BO_ 2026 20;
BA_ "DiagResponse" BO_ 2026 1;
BA_ "GenMsgStartValue" BO_ 1594 "0000000000000000h";
BA_ "GenMsgStartDelayTime" BO_ 1594 980;
BA_ "GenMsgSendType" BO_ 1594 9;
BA_ "GenMsgDelayTime" BO_ 1594 200;
BA_ "GenMsgCycleTime" BO_ 1594 200;
BA_ "GenMsgStartValue" BO_ 2018 "0000000000000000h";
BA_ "GenMsgSendType" BO_ 2018 1;
BA_ "GenMsgNrOfRepetitions" BO_ 2018 2;
BA_ "GenMsgDelayTime" BO_ 2018 20;
BA_ "DiagRequest" BO_ 2018 1;
BA_ "GenMsgStartValue" BO_ 1466 "0000000000000000h";
BA_ "GenMsgSendType" BO_ 1466 1;
BA_ "GenMsgNrOfRepetitions" BO_ 1466 2;
BA_ "GenMsgDelayTime" BO_ 1466 20;
BA_ "App-Botschaft" BO_ 1466 1;
BA_ "GenMsgStartValue" BO_ 1786 "0000000000000000h";
BA_ "GenMsgSendType" BO_ 1786 1;
BA_ "GenMsgNrOfRepetitions" BO_ 1786 2;
BA_ "GenMsgDelayTime" BO_ 1786 20;
BA_ "App-Botschaft" BO_ 1786 1;
BA_ "NWM-Botschaft" BO_ 1082 1;
BA_ "GenMsgStartValue" BO_ 1082 "FFFFFFFF000000FFh";
BA_ "GenMsgSendType" BO_ 1082 1;
BA_ "GenMsgNrOfRepetitions" BO_ 1082 2;
BA_ "GenMsgDelayTime" BO_ 1082 20;
BA_ "GenMsgStartValue" BO_ 1268 "0000000000000000h";
BA_ "GenMsgNrOfRepetitions" BO_ 1268 2;
BA_ "GenMsgDelayTime" BO_ 1268 20;
BA_ "DiagResponse" BO_ 1268 1;
BA_ "GenSigSNA" SG_ 1266 D_RS_GPF "0h";
BA_ "GenSigSendType" SG_ 1266 D_RS_GPF 1;
BA_ "FlexKomSigStartValue" SG_ 1266 D_RS_GPF "0000000000000000h";
BA_ "FlexKomSigStartPos" SG_ 1266 D_RS_GPF 7;
BA_ "FlexKomSigName" SG_ 1266 D_RS_GPF "D_RS_GPF";
BA_ "FlexKomSigLaenge" SG_ 1266 D_RS_GPF 64;
BA_ "FlexKomSID" SG_ 1266 D_RS_GPF 2825;
BA_ "FlexKomIsMotorola" SG_ 1266 D_RS_GPF 1;
BA_ "FlexKomComment" SG_ 1266 D_RS_GPF "Diagnostic-Response";
BA_ "GenSigSNA" SG_ 1284 D_RS_CBC "0h";
BA_ "GenSigSendType" SG_ 1284 D_RS_CBC 1;
BA_ "FlexKomSigStartValue" SG_ 1284 D_RS_CBC "0000000000000000h";
BA_ "FlexKomSigStartPos" SG_ 1284 D_RS_CBC 7;
BA_ "FlexKomSigName" SG_ 1284 D_RS_CBC "D_RS_CBC";
BA_ "FlexKomSigLaenge" SG_ 1284 D_RS_CBC 64;
BA_ "FlexKomSID" SG_ 1284 D_RS_CBC 132;
BA_ "FlexKomIsMotorola" SG_ 1284 D_RS_CBC 1;
BA_ "FlexKomComment" SG_ 1284 D_RS_CBC "Diagnostic-Response";
BA_ "GenSigSNA" SG_ 1323 D_RS_TBM "0h";
BA_ "GenSigSendType" SG_ 1323 D_RS_TBM 1;
BA_ "FlexKomSigStartValue" SG_ 1323 D_RS_TBM "0000000000000000h";
BA_ "FlexKomSigStartPos" SG_ 1323 D_RS_TBM 7;
BA_ "FlexKomSigName" SG_ 1323 D_RS_TBM "D_RS_TBM";
BA_ "FlexKomSigLaenge" SG_ 1323 D_RS_TBM 64;
BA_ "FlexKomSID" SG_ 1323 D_RS_TBM 2431;
BA_ "FlexKomIsMotorola" SG_ 1323 D_RS_TBM 1;
BA_ "FlexKomComment" SG_ 1323 D_RS_TBM "Diagnostic-Response";
BA_ "GenSigSNA" SG_ 1408 ECU_APPL_RF_HUB "0h";
BA_ "GenSigSendType" SG_ 1408 ECU_APPL_RF_HUB 1;
BA_ "FlexKomSigStartValue" SG_ 1408 ECU_APPL_RF_HUB "0000000000000000h";
BA_ "FlexKomSigStartPos" SG_ 1408 ECU_APPL_RF_HUB 7;
BA_ "FlexKomSigName" SG_ 1408 ECU_APPL_RF_HUB "ECU_APPL_RF_HUB";
BA_ "FlexKomSigLaenge" SG_ 1408 ECU_APPL_RF_HUB 64;
BA_ "FlexKomSID" SG_ 1408 ECU_APPL_RF_HUB 358;
BA_ "FlexKomIsMotorola" SG_ 1408 ECU_APPL_RF_HUB 1;
BA_ "FlexKomComment" SG_ 1408 ECU_APPL_RF_HUB "ECU to External Application";
BA_ "GenSigSNA" SG_ 1409 ECU_APPL_CBC "0h";
BA_ "GenSigSendType" SG_ 1409 ECU_APPL_CBC 1;
BA_ "FlexKomSigStartValue" SG_ 1409 ECU_APPL_CBC "0000000000000000h";
BA_ "FlexKomSigStartPos" SG_ 1409 ECU_APPL_CBC 7;
BA_ "FlexKomSigName" SG_ 1409 ECU_APPL_CBC "ECU_APPL_CBC";
BA_ "FlexKomSigLaenge" SG_ 1409 ECU_APPL_CBC 64;
BA_ "FlexKomSID" SG_ 1409 ECU_APPL_CBC 344;
BA_ "FlexKomIsMotorola" SG_ 1409 ECU_APPL_CBC 1;
BA_ "FlexKomComment" SG_ 1409 ECU_APPL_CBC "ECU to External Application";
BA_ "GenSigSNA" SG_ 1410 ECU_APPL_IC "0h";
BA_ "GenSigSendType" SG_ 1410 ECU_APPL_IC 1;
BA_ "FlexKomSigStartValue" SG_ 1410 ECU_APPL_IC "0000000000000000h";
BA_ "FlexKomSigStartPos" SG_ 1410 ECU_APPL_IC 7;
BA_ "FlexKomSigName" SG_ 1410 ECU_APPL_IC "ECU_APPL_IC";
BA_ "FlexKomSigLaenge" SG_ 1410 ECU_APPL_IC 64;
BA_ "FlexKomSID" SG_ 1410 ECU_APPL_IC 361;
BA_ "FlexKomIsMotorola" SG_ 1410 ECU_APPL_IC 1;
BA_ "FlexKomComment" SG_ 1410 ECU_APPL_IC "ECU to External Application";
BA_ "GenSigSNA" SG_ 1412 ECU_APPL_ORC "0h";
BA_ "GenSigSendType" SG_ 1412 ECU_APPL_ORC 1;
BA_ "FlexKomSigStartValue" SG_ 1412 ECU_APPL_ORC "0000000000000000h";
BA_ "FlexKomSigStartPos" SG_ 1412 ECU_APPL_ORC 7;
BA_ "FlexKomSigName" SG_ 1412 ECU_APPL_ORC "ECU_APPL_ORC";
BA_ "FlexKomSigLaenge" SG_ 1412 ECU_APPL_ORC 64;
BA_ "FlexKomSID" SG_ 1412 ECU_APPL_ORC 368;
BA_ "FlexKomIsMotorola" SG_ 1412 ECU_APPL_ORC 1;
BA_ "FlexKomComment" SG_ 1412 ECU_APPL_ORC "ECU to External Application";
BA_ "GenSigSNA" SG_ 1415 ECU_APPL_ESC "0h";
BA_ "GenSigSendType" SG_ 1415 ECU_APPL_ESC 1;
BA_ "FlexKomSigStartValue" SG_ 1415 ECU_APPL_ESC "0000000000000000h";
BA_ "FlexKomSigStartPos" SG_ 1415 ECU_APPL_ESC 7;
BA_ "FlexKomSigName" SG_ 1415 ECU_APPL_ESC "ECU_APPL_ESC";
BA_ "FlexKomSigLaenge" SG_ 1415 ECU_APPL_ESC 64;
BA_ "FlexKomSID" SG_ 1415 ECU_APPL_ESC 356;
BA_ "FlexKomIsMotorola" SG_ 1415 ECU_APPL_ESC 1;
BA_ "FlexKomComment" SG_ 1415 ECU_APPL_ESC "ECU to External Application";
BA_ "GenSigSNA" SG_ 1416 ECU_APPL_ESL "0h";
BA_ "GenSigSendType" SG_ 1416 ECU_APPL_ESL 1;
BA_ "FlexKomSigStartValue" SG_ 1416 ECU_APPL_ESL "0000000000000000h";
BA_ "FlexKomSigStartPos" SG_ 1416 ECU_APPL_ESL 7;
BA_ "FlexKomSigName" SG_ 1416 ECU_APPL_ESL "ECU_APPL_ESL";
BA_ "FlexKomSigLaenge" SG_ 1416 ECU_APPL_ESL 64;
BA_ "FlexKomSID" SG_ 1416 ECU_APPL_ESL 2341;
BA_ "FlexKomIsMotorola" SG_ 1416 ECU_APPL_ESL 1;
BA_ "FlexKomComment" SG_ 1416 ECU_APPL_ESL "ECU to External Application";
BA_ "GenSigSNA" SG_ 1417 ECU_APPL_ESM "0h";
BA_ "GenSigSendType" SG_ 1417 ECU_APPL_ESM 1;
BA_ "FlexKomSigStartValue" SG_ 1417 ECU_APPL_ESM "0000000000000000h";
BA_ "FlexKomSigStartPos" SG_ 1417 ECU_APPL_ESM 7;
BA_ "FlexKomSigName" SG_ 1417 ECU_APPL_ESM "ECU_APPL_ESM";
BA_ "FlexKomSigLaenge" SG_ 1417 ECU_APPL_ESM 64;
BA_ "FlexKomSID" SG_ 1417 ECU_APPL_ESM 355;
BA_ "FlexKomIsMotorola" SG_ 1417 ECU_APPL_ESM 1;
BA_ "FlexKomComment" SG_ 1417 ECU_APPL_ESM "ECU to External Application";
BA_ "GenSigSNA" SG_ 1418 ECU_APPL_ASBS "0h";
BA_ "GenSigSendType" SG_ 1418 ECU_APPL_ASBS 1;
BA_ "FlexKomSigStartValue" SG_ 1418 ECU_APPL_ASBS "0000000000000000h";
BA_ "FlexKomSigStartPos" SG_ 1418 ECU_APPL_ASBS 7;
BA_ "FlexKomSigName" SG_ 1418 ECU_APPL_ASBS "ECU_APPL_ASBS";
BA_ "FlexKomSigLaenge" SG_ 1418 ECU_APPL_ASBS 64;
BA_ "FlexKomSID" SG_ 1418 ECU_APPL_ASBS 2625;
BA_ "FlexKomIsMotorola" SG_ 1418 ECU_APPL_ASBS 1;
BA_ "FlexKomComment" SG_ 1418 ECU_APPL_ASBS "ECU to External Application";
BA_ "GenSigSNA" SG_ 1419 ECU_APPL_DTCM "0h";
BA_ "GenSigSendType" SG_ 1419 ECU_APPL_DTCM 1;
BA_ "FlexKomSigStartValue" SG_ 1419 ECU_APPL_DTCM "0000000000000000h";
BA_ "FlexKomSigStartPos" SG_ 1419 ECU_APPL_DTCM 7;
BA_ "FlexKomSigName" SG_ 1419 ECU_APPL_DTCM "ECU_APPL_DTCM";
BA_ "FlexKomSigLaenge" SG_ 1419 ECU_APPL_DTCM 64;
BA_ "FlexKomSID" SG_ 1419 ECU_APPL_DTCM 351;
BA_ "FlexKomIsMotorola" SG_ 1419 ECU_APPL_DTCM 1;
BA_ "FlexKomComment" SG_ 1419 ECU_APPL_DTCM "ECU to External Application";
BA_ "GenSigSNA" SG_ 1425 ECU_APPL_DPDM "0h";
BA_ "GenSigSendType" SG_ 1425 ECU_APPL_DPDM 1;
BA_ "FlexKomSigStartValue" SG_ 1425 ECU_APPL_DPDM "0000000000000000h";
BA_ "FlexKomSigStartPos" SG_ 1425 ECU_APPL_DPDM 7;
BA_ "FlexKomSigName" SG_ 1425 ECU_APPL_DPDM "ECU_APPL_DPDM";
BA_ "FlexKomSigLaenge" SG_ 1425 ECU_APPL_DPDM 64;
BA_ "FlexKomSID" SG_ 1425 ECU_APPL_DPDM 2659;
BA_ "FlexKomIsMotorola" SG_ 1425 ECU_APPL_DPDM 1;
BA_ "FlexKomComment" SG_ 1425 ECU_APPL_DPDM "ECU to External Application";
BA_ "GenSigSNA" SG_ 1427 ECU_APPL_DASM "0h";
BA_ "GenSigSendType" SG_ 1427 ECU_APPL_DASM 1;
BA_ "FlexKomSigStartValue" SG_ 1427 ECU_APPL_DASM "0000000000000000h";
BA_ "FlexKomSigStartPos" SG_ 1427 ECU_APPL_DASM 7;
BA_ "FlexKomSigName" SG_ 1427 ECU_APPL_DASM "ECU_APPL_DASM";
BA_ "FlexKomSigLaenge" SG_ 1427 ECU_APPL_DASM 64;
BA_ "FlexKomSID" SG_ 1427 ECU_APPL_DASM 364;
BA_ "FlexKomIsMotorola" SG_ 1427 ECU_APPL_DASM 1;
BA_ "FlexKomComment" SG_ 1427 ECU_APPL_DASM "ECU to External Application";
BA_ "GenSigSNA" SG_ 1434 ECU_APPL_EPS "0h";
BA_ "GenSigSendType" SG_ 1434 ECU_APPL_EPS 1;
BA_ "FlexKomSigStartValue" SG_ 1434 ECU_APPL_EPS "0000000000000000h";
BA_ "FlexKomSigStartPos" SG_ 1434 ECU_APPL_EPS 7;
BA_ "FlexKomSigName" SG_ 1434 ECU_APPL_EPS "ECU_APPL_EPS";
BA_ "FlexKomSigLaenge" SG_ 1434 ECU_APPL_EPS 64;
BA_ "FlexKomSID" SG_ 1434 ECU_APPL_EPS 354;
BA_ "FlexKomIsMotorola" SG_ 1434 ECU_APPL_EPS 1;
BA_ "FlexKomComment" SG_ 1434 ECU_APPL_EPS "ECU to External Application";
BA_ "GenSigSNA" SG_ 1438 ECU_APPL_OCM "0h";
BA_ "GenSigSendType" SG_ 1438 ECU_APPL_OCM 1;
BA_ "FlexKomSigStartValue" SG_ 1438 ECU_APPL_OCM "0000000000000000h";
BA_ "FlexKomSigStartPos" SG_ 1438 ECU_APPL_OCM 7;
BA_ "FlexKomSigName" SG_ 1438 ECU_APPL_OCM "ECU_APPL_OCM";
BA_ "FlexKomSigLaenge" SG_ 1438 ECU_APPL_OCM 64;
BA_ "FlexKomSID" SG_ 1438 ECU_APPL_OCM 1540;
BA_ "FlexKomIsMotorola" SG_ 1438 ECU_APPL_OCM 1;
BA_ "FlexKomComment" SG_ 1438 ECU_APPL_OCM "ECU to External Application";
BA_ "GenSigSNA" SG_ 1442 ECU_APPL_PTS "0h";
BA_ "GenSigSendType" SG_ 1442 ECU_APPL_PTS 1;
BA_ "FlexKomSigStartValue" SG_ 1442 ECU_APPL_PTS "0000000000000000h";
BA_ "FlexKomSigStartPos" SG_ 1442 ECU_APPL_PTS 7;
BA_ "FlexKomSigName" SG_ 1442 ECU_APPL_PTS "ECU_APPL_PTS";
BA_ "FlexKomSigLaenge" SG_ 1442 ECU_APPL_PTS 64;
BA_ "FlexKomSID" SG_ 1442 ECU_APPL_PTS 376;
BA_ "FlexKomIsMotorola" SG_ 1442 ECU_APPL_PTS 1;
BA_ "FlexKomComment" SG_ 1442 ECU_APPL_PTS "ECU to External Application";
BA_ "GenSigSNA" SG_ 1443 ECU_APPL_SCCM "0h";
BA_ "GenSigSendType" SG_ 1443 ECU_APPL_SCCM 1;
BA_ "FlexKomSigStartValue" SG_ 1443 ECU_APPL_SCCM "0000000000000000h";
BA_ "FlexKomSigStartPos" SG_ 1443 ECU_APPL_SCCM 7;
BA_ "FlexKomSigName" SG_ 1443 ECU_APPL_SCCM "ECU_APPL_SCCM";
BA_ "FlexKomSigLaenge" SG_ 1443 ECU_APPL_SCCM 64;
BA_ "FlexKomSID" SG_ 1443 ECU_APPL_SCCM 380;
BA_ "FlexKomIsMotorola" SG_ 1443 ECU_APPL_SCCM 1;
BA_ "FlexKomComment" SG_ 1443 ECU_APPL_SCCM "ECU to External Application";
BA_ "GenSigSNA" SG_ 1449 ECU_APPL_AHLM "0h";
BA_ "GenSigSendType" SG_ 1449 ECU_APPL_AHLM 1;
BA_ "FlexKomSigStartValue" SG_ 1449 ECU_APPL_AHLM "0000000000000000h";
BA_ "FlexKomSigStartPos" SG_ 1449 ECU_APPL_AHLM 7;
BA_ "FlexKomSigName" SG_ 1449 ECU_APPL_AHLM "ECU_APPL_AHLM";
BA_ "FlexKomSigLaenge" SG_ 1449 ECU_APPL_AHLM 64;
BA_ "FlexKomSID" SG_ 1449 ECU_APPL_AHLM 339;
BA_ "FlexKomIsMotorola" SG_ 1449 ECU_APPL_AHLM 1;
BA_ "FlexKomComment" SG_ 1449 ECU_APPL_AHLM "ECU to External Application";
BA_ "GenSigSNA" SG_ 1464 ECU_APPL_ECM "0h";
BA_ "GenSigSendType" SG_ 1464 ECU_APPL_ECM 1;
BA_ "FlexKomSigStartValue" SG_ 1464 ECU_APPL_ECM "0000000000000000h";
BA_ "FlexKomSigStartPos" SG_ 1464 ECU_APPL_ECM 7;
BA_ "FlexKomSigName" SG_ 1464 ECU_APPL_ECM "ECU_APPL_ECM";
BA_ "FlexKomSigLaenge" SG_ 1464 ECU_APPL_ECM 64;
BA_ "FlexKomSID" SG_ 1464 ECU_APPL_ECM 352;
BA_ "FlexKomIsMotorola" SG_ 1464 ECU_APPL_ECM 1;
BA_ "FlexKomComment" SG_ 1464 ECU_APPL_ECM "ECU to External Application";
BA_ "GenSigSNA" SG_ 1465 ECU_APPL_TCM "0h";
BA_ "GenSigSendType" SG_ 1465 ECU_APPL_TCM 1;
BA_ "FlexKomSigStartValue" SG_ 1465 ECU_APPL_TCM "0000000000000000h";
BA_ "FlexKomSigStartPos" SG_ 1465 ECU_APPL_TCM 7;
BA_ "FlexKomSigName" SG_ 1465 ECU_APPL_TCM "ECU_APPL_TCM";
BA_ "FlexKomSigLaenge" SG_ 1465 ECU_APPL_TCM 64;
BA_ "FlexKomSID" SG_ 1465 ECU_APPL_TCM 384;
BA_ "FlexKomIsMotorola" SG_ 1465 ECU_APPL_TCM 1;
BA_ "FlexKomComment" SG_ 1465 ECU_APPL_TCM "ECU to External Application";
BA_ "GenSigSNA" SG_ 1468 ECU_APPL_BSMO "0h";
BA_ "GenSigSendType" SG_ 1468 ECU_APPL_BSMO 1;
BA_ "FlexKomSigStartValue" SG_ 1468 ECU_APPL_BSMO "0000000000000000h";
BA_ "FlexKomSigStartPos" SG_ 1468 ECU_APPL_BSMO 7;
BA_ "FlexKomSigName" SG_ 1468 ECU_APPL_BSMO "ECU_APPL_BSMO";
BA_ "FlexKomSigLaenge" SG_ 1468 ECU_APPL_BSMO 64;
BA_ "FlexKomSID" SG_ 1468 ECU_APPL_BSMO 2283;
BA_ "FlexKomIsMotorola" SG_ 1468 ECU_APPL_BSMO 1;
BA_ "FlexKomComment" SG_ 1468 ECU_APPL_BSMO "ECU to External Application";
BA_ "GenSigSNA" SG_ 1515 ECU_APPL_TBM "0h";
BA_ "GenSigSendType" SG_ 1515 ECU_APPL_TBM 1;
BA_ "FlexKomSigStartValue" SG_ 1515 ECU_APPL_TBM "0000000000000000h";
BA_ "FlexKomSigStartPos" SG_ 1515 ECU_APPL_TBM 7;
BA_ "FlexKomSigName" SG_ 1515 ECU_APPL_TBM "ECU_APPL_TBM";
BA_ "FlexKomSigLaenge" SG_ 1515 ECU_APPL_TBM 64;
BA_ "FlexKomSID" SG_ 1515 ECU_APPL_TBM 2432;
BA_ "FlexKomIsMotorola" SG_ 1515 ECU_APPL_TBM 1;
BA_ "FlexKomComment" SG_ 1515 ECU_APPL_TBM "ECU to External Application";
BA_ "GenSigSNA" SG_ 1536 SD_RS_RF_HUB "0h";
BA_ "GenSigSendType" SG_ 1536 SD_RS_RF_HUB 9;
BA_ "GenSigCycleTime" SG_ 1536 SD_RS_RF_HUB 200;
BA_ "FlexKomSigStartValue" SG_ 1536 SD_RS_RF_HUB "0000000000000000h";
BA_ "FlexKomSigStartPos" SG_ 1536 SD_RS_RF_HUB 7;
BA_ "FlexKomSigName" SG_ 1536 SD_RS_RF_HUB "SD_RS_RF_HUB";
BA_ "FlexKomSigLaenge" SG_ 1536 SD_RS_RF_HUB 64;
BA_ "FlexKomSID" SG_ 1536 SD_RS_RF_HUB 198;
BA_ "FlexKomIsMotorola" SG_ 1536 SD_RS_RF_HUB 1;
BA_ "FlexKomComment" SG_ 1536 SD_RS_RF_HUB "Response on Event - light";
BA_ "GenSigSNA" SG_ 1537 SD_RS_CBC "0h";
BA_ "GenSigSendType" SG_ 1537 SD_RS_CBC 9;
BA_ "GenSigCycleTime" SG_ 1537 SD_RS_CBC 200;
BA_ "FlexKomSigStartValue" SG_ 1537 SD_RS_CBC "0000000000000000h";
BA_ "FlexKomSigStartPos" SG_ 1537 SD_RS_CBC 7;
BA_ "FlexKomSigName" SG_ 1537 SD_RS_CBC "SD_RS_CBC";
BA_ "FlexKomSigLaenge" SG_ 1537 SD_RS_CBC 64;
BA_ "FlexKomSID" SG_ 1537 SD_RS_CBC 185;
BA_ "FlexKomIsMotorola" SG_ 1537 SD_RS_CBC 1;
BA_ "FlexKomComment" SG_ 1537 SD_RS_CBC "Response on Event - light";
BA_ "GenSigSNA" SG_ 1538 SD_RS_IC "0h";
BA_ "GenSigSendType" SG_ 1538 SD_RS_IC 9;
BA_ "GenSigCycleTime" SG_ 1538 SD_RS_IC 200;
BA_ "FlexKomSigStartValue" SG_ 1538 SD_RS_IC "0000000000000000h";
BA_ "FlexKomSigStartPos" SG_ 1538 SD_RS_IC 7;
BA_ "FlexKomSigName" SG_ 1538 SD_RS_IC "SD_RS_IC";
BA_ "FlexKomSigLaenge" SG_ 1538 SD_RS_IC 64;
BA_ "FlexKomSID" SG_ 1538 SD_RS_IC 201;
BA_ "FlexKomIsMotorola" SG_ 1538 SD_RS_IC 1;
BA_ "FlexKomComment" SG_ 1538 SD_RS_IC "Response on Event - light";
BA_ "GenSigSNA" SG_ 1540 SD_RS_ORC "0h";
BA_ "GenSigSendType" SG_ 1540 SD_RS_ORC 9;
BA_ "GenSigCycleTime" SG_ 1540 SD_RS_ORC 200;
BA_ "FlexKomSigStartValue" SG_ 1540 SD_RS_ORC "0000000000000000h";
BA_ "FlexKomSigStartPos" SG_ 1540 SD_RS_ORC 7;
BA_ "FlexKomSigName" SG_ 1540 SD_RS_ORC "SD_RS_ORC";
BA_ "FlexKomSigLaenge" SG_ 1540 SD_RS_ORC 64;
BA_ "FlexKomSID" SG_ 1540 SD_RS_ORC 207;
BA_ "FlexKomIsMotorola" SG_ 1540 SD_RS_ORC 1;
BA_ "FlexKomComment" SG_ 1540 SD_RS_ORC "Response on Event - light";
BA_ "GenSigSNA" SG_ 1543 SD_RS_ESC "0h";
BA_ "GenSigSendType" SG_ 1543 SD_RS_ESC 9;
BA_ "GenSigCycleTime" SG_ 1543 SD_RS_ESC 200;
BA_ "FlexKomSigStartValue" SG_ 1543 SD_RS_ESC "0000000000000000h";
BA_ "FlexKomSigStartPos" SG_ 1543 SD_RS_ESC 7;
BA_ "FlexKomSigName" SG_ 1543 SD_RS_ESC "SD_RS_ESC";
BA_ "FlexKomSigLaenge" SG_ 1543 SD_RS_ESC 64;
BA_ "FlexKomSID" SG_ 1543 SD_RS_ESC 196;
BA_ "FlexKomIsMotorola" SG_ 1543 SD_RS_ESC 1;
BA_ "FlexKomComment" SG_ 1543 SD_RS_ESC "Response on Event - light";
BA_ "GenSigSNA" SG_ 1544 SD_RS_ESL "0h";
BA_ "GenSigSendType" SG_ 1544 SD_RS_ESL 9;
BA_ "GenSigCycleTime" SG_ 1544 SD_RS_ESL 200;
BA_ "FlexKomSigStartValue" SG_ 1544 SD_RS_ESL "0000000000000000h";
BA_ "FlexKomSigStartPos" SG_ 1544 SD_RS_ESL 7;
BA_ "FlexKomSigName" SG_ 1544 SD_RS_ESL "SD_RS_ESL";
BA_ "FlexKomSigLaenge" SG_ 1544 SD_RS_ESL 64;
BA_ "FlexKomSID" SG_ 1544 SD_RS_ESL 2342;
BA_ "FlexKomIsMotorola" SG_ 1544 SD_RS_ESL 1;
BA_ "FlexKomComment" SG_ 1544 SD_RS_ESL "Response on Event - light";
BA_ "GenSigSNA" SG_ 1545 SD_RS_ESM "0h";
BA_ "GenSigSendType" SG_ 1545 SD_RS_ESM 9;
BA_ "GenSigCycleTime" SG_ 1545 SD_RS_ESM 200;
BA_ "FlexKomSigStartValue" SG_ 1545 SD_RS_ESM "0000000000000000h";
BA_ "FlexKomSigStartPos" SG_ 1545 SD_RS_ESM 7;
BA_ "FlexKomSigName" SG_ 1545 SD_RS_ESM "SD_RS_ESM";
BA_ "FlexKomSigLaenge" SG_ 1545 SD_RS_ESM 64;
BA_ "FlexKomSID" SG_ 1545 SD_RS_ESM 195;
BA_ "FlexKomIsMotorola" SG_ 1545 SD_RS_ESM 1;
BA_ "FlexKomComment" SG_ 1545 SD_RS_ESM "Response on Event - light";
BA_ "GenSigSNA" SG_ 1546 SD_RS_ASBS "0h";
BA_ "GenSigSendType" SG_ 1546 SD_RS_ASBS 9;
BA_ "GenSigCycleTime" SG_ 1546 SD_RS_ASBS 200;
BA_ "FlexKomSigStartValue" SG_ 1546 SD_RS_ASBS "0000000000000000h";
BA_ "FlexKomSigStartPos" SG_ 1546 SD_RS_ASBS 7;
BA_ "FlexKomSigName" SG_ 1546 SD_RS_ASBS "SD_RS_ASBS";
BA_ "FlexKomSigLaenge" SG_ 1546 SD_RS_ASBS 64;
BA_ "FlexKomSID" SG_ 1546 SD_RS_ASBS 2624;
BA_ "FlexKomIsMotorola" SG_ 1546 SD_RS_ASBS 1;
BA_ "FlexKomComment" SG_ 1546 SD_RS_ASBS "Response on Event - light";
BA_ "GenSigSNA" SG_ 1547 SD_RS_DTCM "0h";
BA_ "GenSigSendType" SG_ 1547 SD_RS_DTCM 9;
BA_ "GenSigCycleTime" SG_ 1547 SD_RS_DTCM 200;
BA_ "FlexKomSigStartValue" SG_ 1547 SD_RS_DTCM "0000000000000000h";
BA_ "FlexKomSigStartPos" SG_ 1547 SD_RS_DTCM 7;
BA_ "FlexKomSigName" SG_ 1547 SD_RS_DTCM "SD_RS_DTCM";
BA_ "FlexKomSigLaenge" SG_ 1547 SD_RS_DTCM 64;
BA_ "FlexKomSID" SG_ 1547 SD_RS_DTCM 191;
BA_ "FlexKomIsMotorola" SG_ 1547 SD_RS_DTCM 1;
BA_ "FlexKomComment" SG_ 1547 SD_RS_DTCM "Response on Event - light";
BA_ "GenSigSNA" SG_ 1553 SD_RS_DPDM "0h";
BA_ "GenSigSendType" SG_ 1553 SD_RS_DPDM 9;
BA_ "GenSigCycleTime" SG_ 1553 SD_RS_DPDM 200;
BA_ "FlexKomSigStartValue" SG_ 1553 SD_RS_DPDM "0000000000000000h";
BA_ "FlexKomSigStartPos" SG_ 1553 SD_RS_DPDM 7;
BA_ "FlexKomSigName" SG_ 1553 SD_RS_DPDM "SD_RS_DPDM";
BA_ "FlexKomSigLaenge" SG_ 1553 SD_RS_DPDM 64;
BA_ "FlexKomSID" SG_ 1553 SD_RS_DPDM 2662;
BA_ "FlexKomIsMotorola" SG_ 1553 SD_RS_DPDM 1;
BA_ "FlexKomComment" SG_ 1553 SD_RS_DPDM "Response on Event - light";
BA_ "GenSigSNA" SG_ 1555 SD_RS_DASM "0h";
BA_ "GenSigSendType" SG_ 1555 SD_RS_DASM 9;
BA_ "GenSigCycleTime" SG_ 1555 SD_RS_DASM 200;
BA_ "FlexKomSigStartValue" SG_ 1555 SD_RS_DASM "0000000000000000h";
BA_ "FlexKomSigStartPos" SG_ 1555 SD_RS_DASM 7;
BA_ "FlexKomSigName" SG_ 1555 SD_RS_DASM "SD_RS_DASM";
BA_ "FlexKomSigLaenge" SG_ 1555 SD_RS_DASM 64;
BA_ "FlexKomSID" SG_ 1555 SD_RS_DASM 203;
BA_ "FlexKomIsMotorola" SG_ 1555 SD_RS_DASM 1;
BA_ "FlexKomComment" SG_ 1555 SD_RS_DASM "Response on Event - light";
BA_ "GenSigSNA" SG_ 1562 SD_RS_EPS "0h";
BA_ "GenSigSendType" SG_ 1562 SD_RS_EPS 9;
BA_ "GenSigCycleTime" SG_ 1562 SD_RS_EPS 200;
BA_ "FlexKomSigStartValue" SG_ 1562 SD_RS_EPS "0000000000000000h";
BA_ "FlexKomSigStartPos" SG_ 1562 SD_RS_EPS 7;
BA_ "FlexKomSigName" SG_ 1562 SD_RS_EPS "SD_RS_EPS";
BA_ "FlexKomSigLaenge" SG_ 1562 SD_RS_EPS 64;
BA_ "FlexKomSID" SG_ 1562 SD_RS_EPS 194;
BA_ "FlexKomIsMotorola" SG_ 1562 SD_RS_EPS 1;
BA_ "FlexKomComment" SG_ 1562 SD_RS_EPS "Response on Event - light";
BA_ "GenSigSNA" SG_ 1566 SD_RS_OCM "0h";
BA_ "GenSigSendType" SG_ 1566 SD_RS_OCM 9;
BA_ "GenSigCycleTime" SG_ 1566 SD_RS_OCM 200;
BA_ "FlexKomSigStartValue" SG_ 1566 SD_RS_OCM "0000000000000000h";
BA_ "FlexKomSigStartPos" SG_ 1566 SD_RS_OCM 7;
BA_ "FlexKomSigName" SG_ 1566 SD_RS_OCM "SD_RS_OCM";
BA_ "FlexKomSigLaenge" SG_ 1566 SD_RS_OCM 64;
BA_ "FlexKomSID" SG_ 1566 SD_RS_OCM 1538;
BA_ "FlexKomIsMotorola" SG_ 1566 SD_RS_OCM 1;
BA_ "FlexKomComment" SG_ 1566 SD_RS_OCM "Response on Event - light";
BA_ "GenSigSNA" SG_ 1568 D_RQ_CBC "0h";
BA_ "GenSigSendType" SG_ 1568 D_RQ_CBC 1;
BA_ "FlexKomSigStartValue" SG_ 1568 D_RQ_CBC "0000000000000000h";
BA_ "FlexKomSigStartPos" SG_ 1568 D_RQ_CBC 7;
BA_ "FlexKomSigName" SG_ 1568 D_RQ_CBC "D_RQ_CBC";
BA_ "FlexKomSigLaenge" SG_ 1568 D_RQ_CBC 64;
BA_ "FlexKomSID" SG_ 1568 D_RQ_CBC 78;
BA_ "FlexKomIsMotorola" SG_ 1568 D_RQ_CBC 1;
BA_ "FlexKomComment" SG_ 1568 D_RQ_CBC "Diagnostic-Request";
BA_ "GenSigSNA" SG_ 1570 SD_RS_PTS "0h";
BA_ "GenSigSendType" SG_ 1570 SD_RS_PTS 9;
BA_ "GenSigCycleTime" SG_ 1570 SD_RS_PTS 200;
BA_ "FlexKomSigStartValue" SG_ 1570 SD_RS_PTS "0000000000000000h";
BA_ "FlexKomSigStartPos" SG_ 1570 SD_RS_PTS 7;
BA_ "FlexKomSigName" SG_ 1570 SD_RS_PTS "SD_RS_PTS";
BA_ "FlexKomSigLaenge" SG_ 1570 SD_RS_PTS 64;
BA_ "FlexKomSID" SG_ 1570 SD_RS_PTS 215;
BA_ "FlexKomIsMotorola" SG_ 1570 SD_RS_PTS 1;
BA_ "FlexKomComment" SG_ 1570 SD_RS_PTS "Response on Event - light";
BA_ "GenSigSNA" SG_ 1571 SD_RS_SCCM "0h";
BA_ "GenSigSendType" SG_ 1571 SD_RS_SCCM 9;
BA_ "GenSigCycleTime" SG_ 1571 SD_RS_SCCM 200;
BA_ "FlexKomSigStartValue" SG_ 1571 SD_RS_SCCM "0000000000000000h";
BA_ "FlexKomSigStartPos" SG_ 1571 SD_RS_SCCM 7;
BA_ "FlexKomSigName" SG_ 1571 SD_RS_SCCM "SD_RS_SCCM";
BA_ "FlexKomSigLaenge" SG_ 1571 SD_RS_SCCM 64;
BA_ "FlexKomSID" SG_ 1571 SD_RS_SCCM 219;
BA_ "FlexKomIsMotorola" SG_ 1571 SD_RS_SCCM 1;
BA_ "FlexKomComment" SG_ 1571 SD_RS_SCCM "Response on Event - light";
BA_ "GenSigSNA" SG_ 1577 SD_RS_AHLM "0h";
BA_ "GenSigSendType" SG_ 1577 SD_RS_AHLM 9;
BA_ "GenSigCycleTime" SG_ 1577 SD_RS_AHLM 200;
BA_ "FlexKomSigStartValue" SG_ 1577 SD_RS_AHLM "0000000000000000h";
BA_ "FlexKomSigStartPos" SG_ 1577 SD_RS_AHLM 7;
BA_ "FlexKomSigName" SG_ 1577 SD_RS_AHLM "SD_RS_AHLM";
BA_ "FlexKomSigLaenge" SG_ 1577 SD_RS_AHLM 64;
BA_ "FlexKomSID" SG_ 1577 SD_RS_AHLM 180;
BA_ "FlexKomIsMotorola" SG_ 1577 SD_RS_AHLM 1;
BA_ "FlexKomComment" SG_ 1577 SD_RS_AHLM "Response on Event - light";
BA_ "GenSigSNA" SG_ 1586 SD_RS_GPF "0h";
BA_ "GenSigSendType" SG_ 1586 SD_RS_GPF 9;
BA_ "GenSigCycleTime" SG_ 1586 SD_RS_GPF 200;
BA_ "FlexKomSigStartValue" SG_ 1586 SD_RS_GPF "0000000000000000h";
BA_ "FlexKomSigStartPos" SG_ 1586 SD_RS_GPF 7;
BA_ "FlexKomSigName" SG_ 1586 SD_RS_GPF "SD_RS_EPS";
BA_ "FlexKomSigLaenge" SG_ 1586 SD_RS_GPF 64;
BA_ "FlexKomSID" SG_ 1586 SD_RS_GPF 2829;
BA_ "FlexKomIsMotorola" SG_ 1586 SD_RS_GPF 1;
BA_ "FlexKomComment" SG_ 1586 SD_RS_GPF "Response on Event - light";
BA_ "GenSigSNA" SG_ 1592 SD_RS_ECM "0h";
BA_ "GenSigSendType" SG_ 1592 SD_RS_ECM 9;
BA_ "GenSigCycleTime" SG_ 1592 SD_RS_ECM 200;
BA_ "FlexKomSigStartValue" SG_ 1592 SD_RS_ECM "0000000000000000h";
BA_ "FlexKomSigStartPos" SG_ 1592 SD_RS_ECM 7;
BA_ "FlexKomSigName" SG_ 1592 SD_RS_ECM "SD_RS_ECM";
BA_ "FlexKomSigLaenge" SG_ 1592 SD_RS_ECM 64;
BA_ "FlexKomSID" SG_ 1592 SD_RS_ECM 192;
BA_ "FlexKomIsMotorola" SG_ 1592 SD_RS_ECM 1;
BA_ "FlexKomComment" SG_ 1592 SD_RS_ECM "Response on Event - light";
BA_ "GenSigSNA" SG_ 1593 SD_RS_TCM "0h";
BA_ "GenSigSendType" SG_ 1593 SD_RS_TCM 9;
BA_ "GenSigCycleTime" SG_ 1593 SD_RS_TCM 200;
BA_ "FlexKomSigStartValue" SG_ 1593 SD_RS_TCM "0000000000000000h";
BA_ "FlexKomSigStartPos" SG_ 1593 SD_RS_TCM 7;
BA_ "FlexKomSigName" SG_ 1593 SD_RS_TCM "SD_RS_TCM";
BA_ "FlexKomSigLaenge" SG_ 1593 SD_RS_TCM 64;
BA_ "FlexKomSID" SG_ 1593 SD_RS_TCM 223;
BA_ "FlexKomIsMotorola" SG_ 1593 SD_RS_TCM 1;
BA_ "FlexKomComment" SG_ 1593 SD_RS_TCM "Response on Event - light";
BA_ "GenSigSNA" SG_ 1596 SD_RS_BSMO "0h";
BA_ "GenSigSendType" SG_ 1596 SD_RS_BSMO 9;
BA_ "GenSigCycleTime" SG_ 1596 SD_RS_BSMO 200;
BA_ "FlexKomSigStartValue" SG_ 1596 SD_RS_BSMO "0000000000000000h";
BA_ "FlexKomSigStartPos" SG_ 1596 SD_RS_BSMO 7;
BA_ "FlexKomSigName" SG_ 1596 SD_RS_BSMO "SD_RS_BSMO";
BA_ "FlexKomSigLaenge" SG_ 1596 SD_RS_BSMO 64;
BA_ "FlexKomSID" SG_ 1596 SD_RS_BSMO 2282;
BA_ "FlexKomIsMotorola" SG_ 1596 SD_RS_BSMO 1;
BA_ "FlexKomComment" SG_ 1596 SD_RS_BSMO "Response on Event - light";
BA_ "GenSigSNA" SG_ 1643 SD_RS_TBM "0h";
BA_ "GenSigSendType" SG_ 1643 SD_RS_TBM 9;
BA_ "GenSigCycleTime" SG_ 1643 SD_RS_TBM 200;
BA_ "FlexKomSigStartValue" SG_ 1643 SD_RS_TBM "0000000000000000h";
BA_ "FlexKomSigStartPos" SG_ 1643 SD_RS_TBM 7;
BA_ "FlexKomSigName" SG_ 1643 SD_RS_TBM "SD_RS_TBM";
BA_ "FlexKomSigLaenge" SG_ 1643 SD_RS_TBM 64;
BA_ "FlexKomSID" SG_ 1643 SD_RS_TBM 2433;
BA_ "FlexKomIsMotorola" SG_ 1643 SD_RS_TBM 1;
BA_ "FlexKomComment" SG_ 1643 SD_RS_TBM "Response on Event - light";
BA_ "GenSigSNA" SG_ 1728 APPL_ECU_RF_HUB "0h";
BA_ "GenSigSendType" SG_ 1728 APPL_ECU_RF_HUB 1;
BA_ "FlexKomSigStartValue" SG_ 1728 APPL_ECU_RF_HUB "0000000000000000h";
BA_ "FlexKomSigStartPos" SG_ 1728 APPL_ECU_RF_HUB 7;
BA_ "FlexKomSigName" SG_ 1728 APPL_ECU_RF_HUB "APPL_ECU_RF_HUB";
BA_ "FlexKomSigLaenge" SG_ 1728 APPL_ECU_RF_HUB 64;
BA_ "FlexKomSID" SG_ 1728 APPL_ECU_RF_HUB 293;
BA_ "FlexKomIsMotorola" SG_ 1728 APPL_ECU_RF_HUB 1;
BA_ "FlexKomComment" SG_ 1728 APPL_ECU_RF_HUB "External Application to ECU";
BA_ "GenSigSNA" SG_ 1729 APPL_ECU_CBC "0h";
BA_ "GenSigSendType" SG_ 1729 APPL_ECU_CBC 1;
BA_ "FlexKomSigStartValue" SG_ 1729 APPL_ECU_CBC "0000000000000000h";
BA_ "FlexKomSigStartPos" SG_ 1729 APPL_ECU_CBC 7;
BA_ "FlexKomSigName" SG_ 1729 APPL_ECU_CBC "APPL_ECU_CBC";
BA_ "FlexKomSigLaenge" SG_ 1729 APPL_ECU_CBC 64;
BA_ "FlexKomSID" SG_ 1729 APPL_ECU_CBC 280;
BA_ "FlexKomIsMotorola" SG_ 1729 APPL_ECU_CBC 1;
BA_ "FlexKomComment" SG_ 1729 APPL_ECU_CBC "External Application to ECU";
BA_ "GenSigSNA" SG_ 1730 APPL_ECU_IC "0h";
BA_ "GenSigSendType" SG_ 1730 APPL_ECU_IC 1;
BA_ "FlexKomSigStartValue" SG_ 1730 APPL_ECU_IC "0000000000000000h";
BA_ "FlexKomSigStartPos" SG_ 1730 APPL_ECU_IC 7;
BA_ "FlexKomSigName" SG_ 1730 APPL_ECU_IC "APPL_ECU_IC";
BA_ "FlexKomSigLaenge" SG_ 1730 APPL_ECU_IC 64;
BA_ "FlexKomSID" SG_ 1730 APPL_ECU_IC 296;
BA_ "FlexKomIsMotorola" SG_ 1730 APPL_ECU_IC 1;
BA_ "FlexKomComment" SG_ 1730 APPL_ECU_IC "External Application to ECU";
BA_ "GenSigSNA" SG_ 1732 APPL_ECU_ORC "0h";
BA_ "GenSigSendType" SG_ 1732 APPL_ECU_ORC 1;
BA_ "FlexKomSigStartValue" SG_ 1732 APPL_ECU_ORC "0000000000000000h";
BA_ "FlexKomSigStartPos" SG_ 1732 APPL_ECU_ORC 7;
BA_ "FlexKomSigName" SG_ 1732 APPL_ECU_ORC "APPL_ECU_ORC";
BA_ "FlexKomSigLaenge" SG_ 1732 APPL_ECU_ORC 64;
BA_ "FlexKomSID" SG_ 1732 APPL_ECU_ORC 302;
BA_ "FlexKomIsMotorola" SG_ 1732 APPL_ECU_ORC 1;
BA_ "FlexKomComment" SG_ 1732 APPL_ECU_ORC "External Application to ECU";
BA_ "GenSigSNA" SG_ 1735 APPL_ECU_ESC "0h";
BA_ "GenSigSendType" SG_ 1735 APPL_ECU_ESC 1;
BA_ "FlexKomSigStartValue" SG_ 1735 APPL_ECU_ESC "0000000000000000h";
BA_ "FlexKomSigStartPos" SG_ 1735 APPL_ECU_ESC 7;
BA_ "FlexKomSigName" SG_ 1735 APPL_ECU_ESC "APPL_ECU_ESC";
BA_ "FlexKomSigLaenge" SG_ 1735 APPL_ECU_ESC 64;
BA_ "FlexKomSID" SG_ 1735 APPL_ECU_ESC 291;
BA_ "FlexKomIsMotorola" SG_ 1735 APPL_ECU_ESC 1;
BA_ "FlexKomComment" SG_ 1735 APPL_ECU_ESC "External Application to ECU";
BA_ "GenSigSNA" SG_ 1736 APPL_ECU_ESL "0h";
BA_ "GenSigSendType" SG_ 1736 APPL_ECU_ESL 1;
BA_ "FlexKomSigStartValue" SG_ 1736 APPL_ECU_ESL "0000000000000000h";
BA_ "FlexKomSigStartPos" SG_ 1736 APPL_ECU_ESL 7;
BA_ "FlexKomSigName" SG_ 1736 APPL_ECU_ESL "APPL_ECU_ESL";
BA_ "FlexKomSigLaenge" SG_ 1736 APPL_ECU_ESL 64;
BA_ "FlexKomSID" SG_ 1736 APPL_ECU_ESL 2338;
BA_ "FlexKomIsMotorola" SG_ 1736 APPL_ECU_ESL 1;
BA_ "FlexKomComment" SG_ 1736 APPL_ECU_ESL "External Application to ECU";
BA_ "GenSigSNA" SG_ 1737 APPL_ECU_ESM "0h";
BA_ "GenSigSendType" SG_ 1737 APPL_ECU_ESM 1;
BA_ "FlexKomSigStartValue" SG_ 1737 APPL_ECU_ESM "0000000000000000h";
BA_ "FlexKomSigStartPos" SG_ 1737 APPL_ECU_ESM 7;
BA_ "FlexKomSigName" SG_ 1737 APPL_ECU_ESM "APPL_ECU_ESM";
BA_ "FlexKomSigLaenge" SG_ 1737 APPL_ECU_ESM 64;
BA_ "FlexKomSID" SG_ 1737 APPL_ECU_ESM 290;
BA_ "FlexKomIsMotorola" SG_ 1737 APPL_ECU_ESM 1;
BA_ "FlexKomComment" SG_ 1737 APPL_ECU_ESM "External Application to ECU";
BA_ "GenSigSNA" SG_ 1738 APPL_ECU_ASBS "0h";
BA_ "GenSigSendType" SG_ 1738 APPL_ECU_ASBS 1;
BA_ "FlexKomSigStartValue" SG_ 1738 APPL_ECU_ASBS "0000000000000000h";
BA_ "FlexKomSigStartPos" SG_ 1738 APPL_ECU_ASBS 7;
BA_ "FlexKomSigName" SG_ 1738 APPL_ECU_ASBS "APPL_ECU_ASBS";
BA_ "FlexKomSigLaenge" SG_ 1738 APPL_ECU_ASBS 64;
BA_ "FlexKomSID" SG_ 1738 APPL_ECU_ASBS 2622;
BA_ "FlexKomIsMotorola" SG_ 1738 APPL_ECU_ASBS 1;
BA_ "FlexKomComment" SG_ 1738 APPL_ECU_ASBS "External Application to ECU";
BA_ "GenSigSNA" SG_ 1739 APPL_ECU_DTCM "0h";
BA_ "GenSigSendType" SG_ 1739 APPL_ECU_DTCM 1;
BA_ "FlexKomSigStartValue" SG_ 1739 APPL_ECU_DTCM "0000000000000000h";
BA_ "FlexKomSigStartPos" SG_ 1739 APPL_ECU_DTCM 7;
BA_ "FlexKomSigName" SG_ 1739 APPL_ECU_DTCM "APPL_ECU_DTCM";
BA_ "FlexKomSigLaenge" SG_ 1739 APPL_ECU_DTCM 64;
BA_ "FlexKomSID" SG_ 1739 APPL_ECU_DTCM 286;
BA_ "FlexKomIsMotorola" SG_ 1739 APPL_ECU_DTCM 1;
BA_ "FlexKomComment" SG_ 1739 APPL_ECU_DTCM "External Application to ECU";
BA_ "GenSigSNA" SG_ 1745 APPL_ECU_DPDM "0h";
BA_ "GenSigSendType" SG_ 1745 APPL_ECU_DPDM 1;
BA_ "FlexKomSigStartValue" SG_ 1745 APPL_ECU_DPDM "0000000000000000h";
BA_ "FlexKomSigStartPos" SG_ 1745 APPL_ECU_DPDM 7;
BA_ "FlexKomSigName" SG_ 1745 APPL_ECU_DPDM "APPL_ECU_DPDM";
BA_ "FlexKomSigLaenge" SG_ 1745 APPL_ECU_DPDM 64;
BA_ "FlexKomSID" SG_ 1745 APPL_ECU_DPDM 2658;
BA_ "FlexKomIsMotorola" SG_ 1745 APPL_ECU_DPDM 1;
BA_ "FlexKomComment" SG_ 1745 APPL_ECU_DPDM "External Application to ECU";
BA_ "GenSigSNA" SG_ 1747 APPL_ECU_DASM "0h";
BA_ "GenSigSendType" SG_ 1747 APPL_ECU_DASM 1;
BA_ "FlexKomSigStartValue" SG_ 1747 APPL_ECU_DASM "0000000000000000h";
BA_ "FlexKomSigStartPos" SG_ 1747 APPL_ECU_DASM 7;
BA_ "FlexKomSigName" SG_ 1747 APPL_ECU_DASM "APPL_ECU_DASM";
BA_ "FlexKomSigLaenge" SG_ 1747 APPL_ECU_DASM 64;
BA_ "FlexKomSID" SG_ 1747 APPL_ECU_DASM 298;
BA_ "FlexKomIsMotorola" SG_ 1747 APPL_ECU_DASM 1;
BA_ "FlexKomComment" SG_ 1747 APPL_ECU_DASM "External Application to ECU";
BA_ "GenSigSNA" SG_ 1754 APPL_ECU_EPS "0h";
BA_ "GenSigSendType" SG_ 1754 APPL_ECU_EPS 1;
BA_ "FlexKomSigStartValue" SG_ 1754 APPL_ECU_EPS "0000000000000000h";
BA_ "FlexKomSigStartPos" SG_ 1754 APPL_ECU_EPS 7;
BA_ "FlexKomSigName" SG_ 1754 APPL_ECU_EPS "APPL_ECU_EPS";
BA_ "FlexKomSigLaenge" SG_ 1754 APPL_ECU_EPS 64;
BA_ "FlexKomSID" SG_ 1754 APPL_ECU_EPS 289;
BA_ "FlexKomIsMotorola" SG_ 1754 APPL_ECU_EPS 1;
BA_ "FlexKomComment" SG_ 1754 APPL_ECU_EPS "External Application to ECU";
BA_ "GenSigSNA" SG_ 1758 APPL_ECU_OCM "0h";
BA_ "GenSigSendType" SG_ 1758 APPL_ECU_OCM 1;
BA_ "FlexKomSigStartValue" SG_ 1758 APPL_ECU_OCM "0000000000000000h";
BA_ "FlexKomSigStartPos" SG_ 1758 APPL_ECU_OCM 7;
BA_ "FlexKomSigName" SG_ 1758 APPL_ECU_OCM "APPL_ECU_OCM";
BA_ "FlexKomSigLaenge" SG_ 1758 APPL_ECU_OCM 64;
BA_ "FlexKomSID" SG_ 1758 APPL_ECU_OCM 1539;
BA_ "FlexKomIsMotorola" SG_ 1758 APPL_ECU_OCM 1;
BA_ "FlexKomComment" SG_ 1758 APPL_ECU_OCM "External Application to ECU";
BA_ "GenSigSNA" SG_ 1762 APPL_ECU_PTS "0h";
BA_ "GenSigSendType" SG_ 1762 APPL_ECU_PTS 1;
BA_ "FlexKomSigStartValue" SG_ 1762 APPL_ECU_PTS "0000000000000000h";
BA_ "FlexKomSigStartPos" SG_ 1762 APPL_ECU_PTS 7;
BA_ "FlexKomSigName" SG_ 1762 APPL_ECU_PTS "APPL_ECU_PTS";
BA_ "FlexKomSigLaenge" SG_ 1762 APPL_ECU_PTS 64;
BA_ "FlexKomSID" SG_ 1762 APPL_ECU_PTS 310;
BA_ "FlexKomIsMotorola" SG_ 1762 APPL_ECU_PTS 1;
BA_ "FlexKomComment" SG_ 1762 APPL_ECU_PTS "External Application to ECU";
BA_ "GenSigSNA" SG_ 1763 APPL_ECU_SCCM "0h";
BA_ "GenSigSendType" SG_ 1763 APPL_ECU_SCCM 1;
BA_ "FlexKomSigStartValue" SG_ 1763 APPL_ECU_SCCM "0000000000000000h";
BA_ "FlexKomSigStartPos" SG_ 1763 APPL_ECU_SCCM 7;
BA_ "FlexKomSigName" SG_ 1763 APPL_ECU_SCCM "APPL_ECU_SCCM";
BA_ "FlexKomSigLaenge" SG_ 1763 APPL_ECU_SCCM 64;
BA_ "FlexKomSID" SG_ 1763 APPL_ECU_SCCM 314;
BA_ "FlexKomIsMotorola" SG_ 1763 APPL_ECU_SCCM 1;
BA_ "FlexKomComment" SG_ 1763 APPL_ECU_SCCM "External Application to ECU";
BA_ "GenSigSNA" SG_ 1769 APPL_ECU_AHLM "0h";
BA_ "GenSigSendType" SG_ 1769 APPL_ECU_AHLM 1;
BA_ "FlexKomSigStartValue" SG_ 1769 APPL_ECU_AHLM "0000000000000000h";
BA_ "FlexKomSigStartPos" SG_ 1769 APPL_ECU_AHLM 7;
BA_ "FlexKomSigName" SG_ 1769 APPL_ECU_AHLM "APPL_ECU_AHLM";
BA_ "FlexKomSigLaenge" SG_ 1769 APPL_ECU_AHLM 64;
BA_ "FlexKomSID" SG_ 1769 APPL_ECU_AHLM 275;
BA_ "FlexKomIsMotorola" SG_ 1769 APPL_ECU_AHLM 1;
BA_ "FlexKomComment" SG_ 1769 APPL_ECU_AHLM "External Application to ECU";
BA_ "GenSigSNA" SG_ 1784 APPL_ECU_ECM "0h";
BA_ "GenSigSendType" SG_ 1784 APPL_ECU_ECM 1;
BA_ "FlexKomSigStartValue" SG_ 1784 APPL_ECU_ECM "0000000000000000h";
BA_ "FlexKomSigStartPos" SG_ 1784 APPL_ECU_ECM 7;
BA_ "FlexKomSigName" SG_ 1784 APPL_ECU_ECM "APPL_ECU_ECM";
BA_ "FlexKomSigLaenge" SG_ 1784 APPL_ECU_ECM 64;
BA_ "FlexKomSID" SG_ 1784 APPL_ECU_ECM 287;
BA_ "FlexKomIsMotorola" SG_ 1784 APPL_ECU_ECM 1;
BA_ "FlexKomComment" SG_ 1784 APPL_ECU_ECM "External Application to ECU";
BA_ "GenSigSNA" SG_ 1785 APPL_ECU_TCM "0h";
BA_ "GenSigSendType" SG_ 1785 APPL_ECU_TCM 1;
BA_ "FlexKomSigStartValue" SG_ 1785 APPL_ECU_TCM "0000000000000000h";
BA_ "FlexKomSigStartPos" SG_ 1785 APPL_ECU_TCM 7;
BA_ "FlexKomSigName" SG_ 1785 APPL_ECU_TCM "APPL_ECU_TCM";
BA_ "FlexKomSigLaenge" SG_ 1785 APPL_ECU_TCM 64;
BA_ "FlexKomSID" SG_ 1785 APPL_ECU_TCM 318;
BA_ "FlexKomIsMotorola" SG_ 1785 APPL_ECU_TCM 1;
BA_ "FlexKomComment" SG_ 1785 APPL_ECU_TCM "External Application to ECU";
BA_ "GenSigSNA" SG_ 1788 APPL_ECU_BSMO "0h";
BA_ "GenSigSendType" SG_ 1788 APPL_ECU_BSMO 1;
BA_ "FlexKomSigStartValue" SG_ 1788 APPL_ECU_BSMO "0000000000000000h";
BA_ "FlexKomSigStartPos" SG_ 1788 APPL_ECU_BSMO 7;
BA_ "FlexKomSigName" SG_ 1788 APPL_ECU_BSMO "APPL_ECU_BSMO";
BA_ "FlexKomSigLaenge" SG_ 1788 APPL_ECU_BSMO 64;
BA_ "FlexKomSID" SG_ 1788 APPL_ECU_BSMO 2285;
BA_ "FlexKomIsMotorola" SG_ 1788 APPL_ECU_BSMO 1;
BA_ "FlexKomComment" SG_ 1788 APPL_ECU_BSMO "External Application to ECU";
BA_ "GenSigSNA" SG_ 1835 APPL_ECU_TBM "0h";
BA_ "GenSigSendType" SG_ 1835 APPL_ECU_TBM 1;
BA_ "FlexKomSigStartValue" SG_ 1835 APPL_ECU_TBM "0000000000000000h";
BA_ "FlexKomSigStartPos" SG_ 1835 APPL_ECU_TBM 7;
BA_ "FlexKomSigName" SG_ 1835 APPL_ECU_TBM "APPL_ECU_TBM";
BA_ "FlexKomSigLaenge" SG_ 1835 APPL_ECU_TBM 64;
BA_ "FlexKomSID" SG_ 1835 APPL_ECU_TBM 2932;
BA_ "FlexKomIsMotorola" SG_ 1835 APPL_ECU_TBM 1;
BA_ "FlexKomComment" SG_ 1835 APPL_ECU_TBM "External Application to ECU";
BA_ "GenSigSNA" SG_ 1856 D_RQ_RF_HUB "0h";
BA_ "GenSigSendType" SG_ 1856 D_RQ_RF_HUB 1;
BA_ "FlexKomSigStartValue" SG_ 1856 D_RQ_RF_HUB "0000000000000000h";
BA_ "FlexKomSigStartPos" SG_ 1856 D_RQ_RF_HUB 7;
BA_ "FlexKomSigName" SG_ 1856 D_RQ_RF_HUB "D_RQ_RF_HUB";
BA_ "FlexKomSigLaenge" SG_ 1856 D_RQ_RF_HUB 64;
BA_ "FlexKomSID" SG_ 1856 D_RQ_RF_HUB 92;
BA_ "FlexKomIsMotorola" SG_ 1856 D_RQ_RF_HUB 1;
BA_ "FlexKomComment" SG_ 1856 D_RQ_RF_HUB "Diagnostic-Request";
BA_ "GenSigSNA" SG_ 1858 D_RQ_IC "0h";
BA_ "GenSigSendType" SG_ 1858 D_RQ_IC 1;
BA_ "FlexKomSigStartValue" SG_ 1858 D_RQ_IC "0000000000000000h";
BA_ "FlexKomSigStartPos" SG_ 1858 D_RQ_IC 7;
BA_ "FlexKomSigName" SG_ 1858 D_RQ_IC "D_RQ_IC";
BA_ "FlexKomSigLaenge" SG_ 1858 D_RQ_IC 64;
BA_ "FlexKomSID" SG_ 1858 D_RQ_IC 95;
BA_ "FlexKomIsMotorola" SG_ 1858 D_RQ_IC 1;
BA_ "FlexKomComment" SG_ 1858 D_RQ_IC "Diagnostic-Request";
BA_ "GenSigSNA" SG_ 1860 D_RQ_ORC "0h";
BA_ "GenSigSendType" SG_ 1860 D_RQ_ORC 1;
BA_ "FlexKomSigStartValue" SG_ 1860 D_RQ_ORC "0000000000000000h";
BA_ "FlexKomSigStartPos" SG_ 1860 D_RQ_ORC 7;
BA_ "FlexKomSigName" SG_ 1860 D_RQ_ORC "D_RQ_ORC";
BA_ "FlexKomSigLaenge" SG_ 1860 D_RQ_ORC 64;
BA_ "FlexKomSID" SG_ 1860 D_RQ_ORC 101;
BA_ "FlexKomIsMotorola" SG_ 1860 D_RQ_ORC 1;
BA_ "FlexKomComment" SG_ 1860 D_RQ_ORC "Diagnostic-Request";
BA_ "GenSigSNA" SG_ 1863 D_RQ_ESC "0h";
BA_ "GenSigSendType" SG_ 1863 D_RQ_ESC 1;
BA_ "FlexKomSigStartValue" SG_ 1863 D_RQ_ESC "0000000000000000h";
BA_ "FlexKomSigStartPos" SG_ 1863 D_RQ_ESC 7;
BA_ "FlexKomSigName" SG_ 1863 D_RQ_ESC "D_RQ_ESC";
BA_ "FlexKomSigLaenge" SG_ 1863 D_RQ_ESC 64;
BA_ "FlexKomSID" SG_ 1863 D_RQ_ESC 14;
BA_ "FlexKomIsMotorola" SG_ 1863 D_RQ_ESC 1;
BA_ "FlexKomComment" SG_ 1863 D_RQ_ESC "Diagnostic-Request";
BA_ "GenSigSNA" SG_ 1864 D_RQ_ESL "0h";
BA_ "GenSigSendType" SG_ 1864 D_RQ_ESL 1;
BA_ "FlexKomSigStartValue" SG_ 1864 D_RQ_ESL "0000000000000000h";
BA_ "FlexKomSigStartPos" SG_ 1864 D_RQ_ESL 7;
BA_ "FlexKomSigName" SG_ 1864 D_RQ_ESL "D_RQ_ESL";
BA_ "FlexKomSigLaenge" SG_ 1864 D_RQ_ESL 64;
BA_ "FlexKomSID" SG_ 1864 D_RQ_ESL 2339;
BA_ "FlexKomIsMotorola" SG_ 1864 D_RQ_ESL 1;
BA_ "FlexKomComment" SG_ 1864 D_RQ_ESL "Diagnostic-Request";
BA_ "GenSigSNA" SG_ 1865 D_RQ_ESM "0h";
BA_ "GenSigSendType" SG_ 1865 D_RQ_ESM 1;
BA_ "FlexKomSigStartValue" SG_ 1865 D_RQ_ESM "0000000000000000h";
BA_ "FlexKomSigStartPos" SG_ 1865 D_RQ_ESM 7;
BA_ "FlexKomSigName" SG_ 1865 D_RQ_ESM "D_RQ_ESM";
BA_ "FlexKomSigLaenge" SG_ 1865 D_RQ_ESM 64;
BA_ "FlexKomSID" SG_ 1865 D_RQ_ESM 90;
BA_ "FlexKomIsMotorola" SG_ 1865 D_RQ_ESM 1;
BA_ "FlexKomComment" SG_ 1865 D_RQ_ESM "Diagnostic-Request";
BA_ "GenSigSNA" SG_ 1866 D_RQ_ASBS "0h";
BA_ "GenSigSendType" SG_ 1866 D_RQ_ASBS 1;
BA_ "FlexKomSigStartValue" SG_ 1866 D_RQ_ASBS "0000000000000000h";
BA_ "FlexKomSigStartPos" SG_ 1866 D_RQ_ASBS 7;
BA_ "FlexKomSigName" SG_ 1866 D_RQ_ASBS "D_RQ_ASBS";
BA_ "FlexKomSigLaenge" SG_ 1866 D_RQ_ASBS 64;
BA_ "FlexKomSID" SG_ 1866 D_RQ_ASBS 2621;
BA_ "FlexKomIsMotorola" SG_ 1866 D_RQ_ASBS 1;
BA_ "FlexKomComment" SG_ 1866 D_RQ_ASBS "Diagnostic-Request";
BA_ "GenSigSNA" SG_ 1867 D_RQ_DTCM "0h";
BA_ "GenSigSendType" SG_ 1867 D_RQ_DTCM 1;
BA_ "FlexKomSigStartValue" SG_ 1867 D_RQ_DTCM "0000000000000000h";
BA_ "FlexKomSigStartPos" SG_ 1867 D_RQ_DTCM 7;
BA_ "FlexKomSigName" SG_ 1867 D_RQ_DTCM "D_RQ_DTCM";
BA_ "FlexKomSigLaenge" SG_ 1867 D_RQ_DTCM 64;
BA_ "FlexKomSID" SG_ 1867 D_RQ_DTCM 84;
BA_ "FlexKomIsMotorola" SG_ 1867 D_RQ_DTCM 1;
BA_ "FlexKomComment" SG_ 1867 D_RQ_DTCM "Diagnostic-Request";
BA_ "GenSigSNA" SG_ 1873 D_RQ_DPDM "0h";
BA_ "GenSigSendType" SG_ 1873 D_RQ_DPDM 1;
BA_ "FlexKomSigStartValue" SG_ 1873 D_RQ_DPDM "0000000000000000h";
BA_ "FlexKomSigStartPos" SG_ 1873 D_RQ_DPDM 7;
BA_ "FlexKomSigName" SG_ 1873 D_RQ_DPDM "D_RQ_DPDM";
BA_ "FlexKomSigLaenge" SG_ 1873 D_RQ_DPDM 64;
BA_ "FlexKomSID" SG_ 1873 D_RQ_DPDM 2660;
BA_ "FlexKomIsMotorola" SG_ 1873 D_RQ_DPDM 1;
BA_ "FlexKomComment" SG_ 1873 D_RQ_DPDM "Diagnostic-Request";
BA_ "GenSigSNA" SG_ 1875 D_RQ_DASM "0h";
BA_ "GenSigSendType" SG_ 1875 D_RQ_DASM 1;
BA_ "FlexKomSigStartValue" SG_ 1875 D_RQ_DASM "0000000000000000h";
BA_ "FlexKomSigStartPos" SG_ 1875 D_RQ_DASM 7;
BA_ "FlexKomSigName" SG_ 1875 D_RQ_DASM "D_RQ_DASM";
BA_ "FlexKomSigLaenge" SG_ 1875 D_RQ_DASM 64;
BA_ "FlexKomSID" SG_ 1875 D_RQ_DASM 97;
BA_ "FlexKomIsMotorola" SG_ 1875 D_RQ_DASM 1;
BA_ "FlexKomComment" SG_ 1875 D_RQ_DASM "Diagnostic-Request";
BA_ "GenSigSNA" SG_ 1882 D_RQ_EPS "0h";
BA_ "GenSigSendType" SG_ 1882 D_RQ_EPS 1;
BA_ "FlexKomSigStartValue" SG_ 1882 D_RQ_EPS "0000000000000000h";
BA_ "FlexKomSigStartPos" SG_ 1882 D_RQ_EPS 7;
BA_ "FlexKomSigName" SG_ 1882 D_RQ_EPS "D_RQ_EPS";
BA_ "FlexKomSigLaenge" SG_ 1882 D_RQ_EPS 64;
BA_ "FlexKomSID" SG_ 1882 D_RQ_EPS 87;
BA_ "FlexKomIsMotorola" SG_ 1882 D_RQ_EPS 1;
BA_ "FlexKomComment" SG_ 1882 D_RQ_EPS "Diagnostic-Request";
BA_ "GenSigSNA" SG_ 1886 D_RQ_OCM "0h";
BA_ "GenSigSendType" SG_ 1886 D_RQ_OCM 1;
BA_ "FlexKomSigStartValue" SG_ 1886 D_RQ_OCM "0000000000000000h";
BA_ "FlexKomSigStartPos" SG_ 1886 D_RQ_OCM 7;
BA_ "FlexKomSigName" SG_ 1886 D_RQ_OCM "D_RQ_OCM";
BA_ "FlexKomSigLaenge" SG_ 1886 D_RQ_OCM 64;
BA_ "FlexKomSID" SG_ 1886 D_RQ_OCM 1536;
BA_ "FlexKomIsMotorola" SG_ 1886 D_RQ_OCM 1;
BA_ "FlexKomComment" SG_ 1886 D_RQ_OCM "Diagnostic-Request";
BA_ "GenSigSNA" SG_ 1890 D_RQ_PTS "0h";
BA_ "GenSigSendType" SG_ 1890 D_RQ_PTS 1;
BA_ "FlexKomSigStartValue" SG_ 1890 D_RQ_PTS "0000000000000000h";
BA_ "FlexKomSigStartPos" SG_ 1890 D_RQ_PTS 7;
BA_ "FlexKomSigName" SG_ 1890 D_RQ_PTS "D_RQ_PTS";
BA_ "FlexKomSigLaenge" SG_ 1890 D_RQ_PTS 64;
BA_ "FlexKomSID" SG_ 1890 D_RQ_PTS 109;
BA_ "FlexKomIsMotorola" SG_ 1890 D_RQ_PTS 1;
BA_ "FlexKomComment" SG_ 1890 D_RQ_PTS "Diagnostic-Request";
BA_ "GenSigSNA" SG_ 1891 D_RQ_SCCM "0h";
BA_ "GenSigSendType" SG_ 1891 D_RQ_SCCM 1;
BA_ "FlexKomSigStartValue" SG_ 1891 D_RQ_SCCM "0000000000000000h";
BA_ "FlexKomSigStartPos" SG_ 1891 D_RQ_SCCM 7;
BA_ "FlexKomSigName" SG_ 1891 D_RQ_SCCM "D_RQ_SCCM";
BA_ "FlexKomSigLaenge" SG_ 1891 D_RQ_SCCM 64;
BA_ "FlexKomSID" SG_ 1891 D_RQ_SCCM 113;
BA_ "FlexKomIsMotorola" SG_ 1891 D_RQ_SCCM 1;
BA_ "FlexKomComment" SG_ 1891 D_RQ_SCCM "Diagnostic-Request";
BA_ "GenSigSNA" SG_ 1897 D_RQ_AHLM "0h";
BA_ "GenSigSendType" SG_ 1897 D_RQ_AHLM 1;
BA_ "FlexKomSigStartValue" SG_ 1897 D_RQ_AHLM "0000000000000000h";
BA_ "FlexKomSigStartPos" SG_ 1897 D_RQ_AHLM 7;
BA_ "FlexKomSigName" SG_ 1897 D_RQ_AHLM "D_RQ_AHLM";
BA_ "FlexKomSigLaenge" SG_ 1897 D_RQ_AHLM 64;
BA_ "FlexKomSID" SG_ 1897 D_RQ_AHLM 73;
BA_ "FlexKomIsMotorola" SG_ 1897 D_RQ_AHLM 1;
BA_ "FlexKomComment" SG_ 1897 D_RQ_AHLM "Diagnostic-Request";
BA_ "GenSigSNA" SG_ 1901 D_RQ_IDCM "0h";
BA_ "GenSigSendType" SG_ 1901 D_RQ_IDCM 1;
BA_ "FlexKomSigStartValue" SG_ 1901 D_RQ_IDCM "0000000000000000h";
BA_ "FlexKomSigStartPos" SG_ 1901 D_RQ_IDCM 7;
BA_ "FlexKomSigName" SG_ 1901 D_RQ_IDCM "D_RQ_IDCM";
BA_ "FlexKomSigLaenge" SG_ 1901 D_RQ_IDCM 64;
BA_ "FlexKomSID" SG_ 1901 D_RQ_IDCM 2967;
BA_ "FlexKomIsMotorola" SG_ 1901 D_RQ_IDCM 1;
BA_ "FlexKomComment" SG_ 1901 D_RQ_IDCM "Diagnostic-Request";
BA_ "GenSigSNA" SG_ 1906 D_RQ_GPF "0h";
BA_ "GenSigSendType" SG_ 1906 D_RQ_GPF 1;
BA_ "FlexKomSigStartValue" SG_ 1906 D_RQ_GPF "0000000000000000h";
BA_ "FlexKomSigStartPos" SG_ 1906 D_RQ_GPF 7;
BA_ "FlexKomSigName" SG_ 1906 D_RQ_GPF "D_RQ_EPS";
BA_ "FlexKomSigLaenge" SG_ 1906 D_RQ_GPF 64;
BA_ "FlexKomSID" SG_ 1906 D_RQ_GPF 2826;
BA_ "FlexKomIsMotorola" SG_ 1906 D_RQ_GPF 1;
BA_ "FlexKomComment" SG_ 1906 D_RQ_GPF "Diagnostic-Request";
BA_ "GenSigSNA" SG_ 1963 D_RQ_TBM "0h";
BA_ "GenSigSendType" SG_ 1963 D_RQ_TBM 1;
BA_ "FlexKomSigStartValue" SG_ 1963 D_RQ_TBM "0000000000000000h";
BA_ "FlexKomSigStartPos" SG_ 1963 D_RQ_TBM 7;
BA_ "FlexKomSigName" SG_ 1963 D_RQ_TBM "D_RQ_TBM";
BA_ "FlexKomSigLaenge" SG_ 1963 D_RQ_TBM 64;
BA_ "FlexKomSID" SG_ 1963 D_RQ_TBM 2430;
BA_ "FlexKomIsMotorola" SG_ 1963 D_RQ_TBM 1;
BA_ "FlexKomComment" SG_ 1963 D_RQ_TBM "Diagnostic-Request";
BA_ "GenSigSNA" SG_ 2015 DG_RQ_GLOBAL "0h";
BA_ "FlexKomSigStartValue" SG_ 2015 DG_RQ_GLOBAL "0000000000000000h";
BA_ "FlexKomSigStartPos" SG_ 2015 DG_RQ_GLOBAL 7;
BA_ "FlexKomSigName" SG_ 2015 DG_RQ_GLOBAL "DG_RQ_GLOBAL";
BA_ "FlexKomSigLaenge" SG_ 2015 DG_RQ_GLOBAL 64;
BA_ "FlexKomSID" SG_ 2015 DG_RQ_GLOBAL 392;
BA_ "FlexKomIsMotorola" SG_ 2015 DG_RQ_GLOBAL 1;
BA_ "FlexKomComment" SG_ 2015 DG_RQ_GLOBAL "Diagnostic-Request";
BA_ "GenSigSNA" SG_ 2016 D_RQ_ECM "0h";
BA_ "GenSigSendType" SG_ 2016 D_RQ_ECM 1;
BA_ "FlexKomSigStartValue" SG_ 2016 D_RQ_ECM "0000000000000000h";
BA_ "FlexKomSigStartPos" SG_ 2016 D_RQ_ECM 7;
BA_ "FlexKomSigName" SG_ 2016 D_RQ_ECM "D_RQ_ECM";
BA_ "FlexKomSigLaenge" SG_ 2016 D_RQ_ECM 64;
BA_ "FlexKomSID" SG_ 2016 D_RQ_ECM 85;
BA_ "FlexKomIsMotorola" SG_ 2016 D_RQ_ECM 1;
BA_ "FlexKomComment" SG_ 2016 D_RQ_ECM "Diagnostic-Request";
BA_ "GenSigSNA" SG_ 2017 D_RQ_TCM "0h";
BA_ "GenSigSendType" SG_ 2017 D_RQ_TCM 1;
BA_ "FlexKomSigStartValue" SG_ 2017 D_RQ_TCM "0000000000000000h";
BA_ "FlexKomSigStartPos" SG_ 2017 D_RQ_TCM 7;
BA_ "FlexKomSigName" SG_ 2017 D_RQ_TCM "D_RQ_TCM";
BA_ "FlexKomSigLaenge" SG_ 2017 D_RQ_TCM 64;
BA_ "FlexKomSID" SG_ 2017 D_RQ_TCM 117;
BA_ "FlexKomIsMotorola" SG_ 2017 D_RQ_TCM 1;
BA_ "FlexKomComment" SG_ 2017 D_RQ_TCM "Diagnostic-Request";
BA_ "GenSigSNA" SG_ 2020 D_RQ_BSMO "0h";
BA_ "GenSigSendType" SG_ 2020 D_RQ_BSMO 1;
BA_ "FlexKomSigStartValue" SG_ 2020 D_RQ_BSMO "0000000000000000h";
BA_ "FlexKomSigStartPos" SG_ 2020 D_RQ_BSMO 7;
BA_ "FlexKomSigName" SG_ 2020 D_RQ_BSMO "D_RQ_BSMO";
BA_ "FlexKomSigLaenge" SG_ 2020 D_RQ_BSMO 64;
BA_ "FlexKomSID" SG_ 2020 D_RQ_BSMO 2284;
BA_ "FlexKomIsMotorola" SG_ 2020 D_RQ_BSMO 1;
BA_ "FlexKomComment" SG_ 2020 D_RQ_BSMO "Diagnostic-Request";
BA_ "GenSigSNA" SG_ 2021 D_RQ_MCPA "0h";
BA_ "GenSigSendType" SG_ 2021 D_RQ_MCPA 1;
BA_ "FlexKomSigStartValue" SG_ 2021 D_RQ_MCPA "0000000000000000h";
BA_ "FlexKomSigStartPos" SG_ 2021 D_RQ_MCPA 7;
BA_ "FlexKomSigName" SG_ 2021 D_RQ_MCPA "D_RQ_MCPA";
BA_ "FlexKomSigLaenge" SG_ 2021 D_RQ_MCPA 64;
BA_ "FlexKomSID" SG_ 2021 D_RQ_MCPA 3125;
BA_ "FlexKomIsMotorola" SG_ 2021 D_RQ_MCPA 1;
BA_ "FlexKomComment" SG_ 2021 D_RQ_MCPA "Diagnostic-Request";
BA_ "GenSigSNA" SG_ 2023 D_RQ_BPCM "0h";
BA_ "GenSigSendType" SG_ 2023 D_RQ_BPCM 1;
BA_ "FlexKomSigStartValue" SG_ 2023 D_RQ_BPCM "0000000000000000h";
BA_ "FlexKomSigStartPos" SG_ 2023 D_RQ_BPCM 7;
BA_ "FlexKomSigName" SG_ 2023 D_RQ_BPCM "D_RQ_BPCM";
BA_ "FlexKomSigLaenge" SG_ 2023 D_RQ_BPCM 64;
BA_ "FlexKomSID" SG_ 2023 D_RQ_BPCM 2138;
BA_ "FlexKomIsMotorola" SG_ 2023 D_RQ_BPCM 1;
BA_ "FlexKomComment" SG_ 2023 D_RQ_BPCM "Diagnostic-Request";
BA_ "GenSigSNA" SG_ 2024 D_RS_ECM "0h";
BA_ "GenSigSendType" SG_ 2024 D_RS_ECM 1;
BA_ "FlexKomSigStartValue" SG_ 2024 D_RS_ECM "0000000000000000h";
BA_ "FlexKomSigStartPos" SG_ 2024 D_RS_ECM 7;
BA_ "FlexKomSigName" SG_ 2024 D_RS_ECM "D_RS_ECM";
BA_ "FlexKomSigLaenge" SG_ 2024 D_RS_ECM 64;
BA_ "FlexKomSID" SG_ 2024 D_RS_ECM 139;
BA_ "FlexKomIsMotorola" SG_ 2024 D_RS_ECM 1;
BA_ "FlexKomComment" SG_ 2024 D_RS_ECM "Diagnostic-Response";
BA_ "GenSigSNA" SG_ 2025 D_RS_TCM "0h";
BA_ "GenSigSendType" SG_ 2025 D_RS_TCM 1;
BA_ "FlexKomSigStartValue" SG_ 2025 D_RS_TCM "0000000000000000h";
BA_ "FlexKomSigStartPos" SG_ 2025 D_RS_TCM 7;
BA_ "FlexKomSigName" SG_ 2025 D_RS_TCM "D_RS_TCM";
BA_ "FlexKomSigLaenge" SG_ 2025 D_RS_TCM 64;
BA_ "FlexKomSID" SG_ 2025 D_RS_TCM 169;
BA_ "FlexKomIsMotorola" SG_ 2025 D_RS_TCM 1;
BA_ "FlexKomComment" SG_ 2025 D_RS_TCM "Diagnostic-Response";
BA_ "GenSigSNA" SG_ 2028 D_RS_BSMO "0h";
BA_ "GenSigSendType" SG_ 2028 D_RS_BSMO 1;
BA_ "FlexKomSigStartValue" SG_ 2028 D_RS_BSMO "0000000000000000h";
BA_ "FlexKomSigStartPos" SG_ 2028 D_RS_BSMO 7;
BA_ "FlexKomSigName" SG_ 2028 D_RS_BSMO "D_RS_BSMO";
BA_ "FlexKomSigLaenge" SG_ 2028 D_RS_BSMO 64;
BA_ "FlexKomSID" SG_ 2028 D_RS_BSMO 2281;
BA_ "FlexKomIsMotorola" SG_ 2028 D_RS_BSMO 1;
BA_ "FlexKomComment" SG_ 2028 D_RS_BSMO "Diagnostic-Response";
BA_ "GenSigSNA" SG_ 2029 D_RS_MCPA "0h";
BA_ "GenSigSendType" SG_ 2029 D_RS_MCPA 1;
BA_ "FlexKomSigStartValue" SG_ 2029 D_RS_MCPA "0000000000000000h";
BA_ "FlexKomSigStartPos" SG_ 2029 D_RS_MCPA 7;
BA_ "FlexKomSigName" SG_ 2029 D_RS_MCPA "D_RS_MCPA";
BA_ "FlexKomSigLaenge" SG_ 2029 D_RS_MCPA 64;
BA_ "FlexKomSID" SG_ 2029 D_RS_MCPA 3124;
BA_ "FlexKomIsMotorola" SG_ 2029 D_RS_MCPA 1;
BA_ "FlexKomComment" SG_ 2029 D_RS_MCPA "Diagnostic-Response";
BA_ "GenSigSNA" SG_ 2031 D_RS_BPCM "0h";
BA_ "GenSigSendType" SG_ 2031 D_RS_BPCM 1;
BA_ "FlexKomSigStartValue" SG_ 2031 D_RS_BPCM "0000000000000000h";
BA_ "FlexKomSigStartPos" SG_ 2031 D_RS_BPCM 7;
BA_ "FlexKomSigName" SG_ 2031 D_RS_BPCM "D_RS_BPCM";
BA_ "FlexKomSigLaenge" SG_ 2031 D_RS_BPCM 64;
BA_ "FlexKomSID" SG_ 2031 D_RS_BPCM 2139;
BA_ "FlexKomIsMotorola" SG_ 2031 D_RS_BPCM 1;
BA_ "FlexKomComment" SG_ 2031 D_RS_BPCM "Diagnostic-Response";
BA_ "GenSigSNA" SG_ 2047 WAKE_SGW_Signal "0h";
BA_ "GenSigSendType" SG_ 2047 WAKE_SGW_Signal 1;
BA_ "FlexKomSigStartValue" SG_ 2047 WAKE_SGW_Signal "00h";
BA_ "FlexKomSigStartPos" SG_ 2047 WAKE_SGW_Signal 7;
BA_ "FlexKomSigName" SG_ 2047 WAKE_SGW_Signal "WAKE_SGW_Signal";
BA_ "FlexKomSigLaenge" SG_ 2047 WAKE_SGW_Signal 8;
BA_ "FlexKomSID" SG_ 2047 WAKE_SGW_Signal 2669;
BA_ "FlexKomIsMotorola" SG_ 2047 WAKE_SGW_Signal 1;
BA_ "FlexKomComment" SG_ 2047 WAKE_SGW_Signal "This signal is used to wakeup networks";
BA_ "GenSigStartValue" SG_ 966 VC_VehCfgCSO4_Stat 3;
BA_ "GenSigSNA" SG_ 966 VC_VehCfgCSO4_Stat "3h";
BA_ "GenSigSendType" SG_ 966 VC_VehCfgCSO4_Stat 5;
BA_ "GenSigCycleTime" SG_ 966 VC_VehCfgCSO4_Stat 2000;
BA_ "FlexKomSigStartValue" SG_ 966 VC_VehCfgCSO4_Stat "0300000000000000h";
BA_ "FlexKomSigStartPos" SG_ 966 VC_VehCfgCSO4_Stat 7;
BA_ "FlexKomSigName" SG_ 966 VC_VehCfgCSO4_Stat "VehCfgCSM4_Pkt";
BA_ "FlexKomSigLaenge" SG_ 966 VC_VehCfgCSO4_Stat 64;
BA_ "FlexKomSID" SG_ 966 VC_VehCfgCSO4_Stat 3283;
BA_ "FlexKomIsMotorola" SG_ 966 VC_VehCfgCSO4_Stat 1;
BA_ "FlexKomComment" SG_ 966 VC_VehCfgCSO4_Stat "Vehicle configuration - customer settings menu 4 P";
BA_ "GenSigSNA" SG_ 966 VC_Drowsy_Driver_Alert_CSO "0h";
BA_ "GenSigSendType" SG_ 966 VC_Drowsy_Driver_Alert_CSO 5;
BA_ "GenSigCycleTime" SG_ 966 VC_Drowsy_Driver_Alert_CSO 2000;
BA_ "FlexKomSigStartValue" SG_ 966 VC_Drowsy_Driver_Alert_CSO "0300000000000000h";
BA_ "FlexKomSigStartPos" SG_ 966 VC_Drowsy_Driver_Alert_CSO 7;
BA_ "FlexKomSigName" SG_ 966 VC_Drowsy_Driver_Alert_CSO "VehCfgCSM4_Pkt";
BA_ "FlexKomSigLaenge" SG_ 966 VC_Drowsy_Driver_Alert_CSO 64;
BA_ "FlexKomSID" SG_ 966 VC_Drowsy_Driver_Alert_CSO 3283;
BA_ "FlexKomIsMotorola" SG_ 966 VC_Drowsy_Driver_Alert_CSO 1;
BA_ "FlexKomComment" SG_ 966 VC_Drowsy_Driver_Alert_CSO "Vehicle configuration - customer settings menu 4 P";
BA_ "GenSigSNA" SG_ 966 VC_LDW_2_Option_CSO "0h";
BA_ "GenSigSendType" SG_ 966 VC_LDW_2_Option_CSO 5;
BA_ "GenSigCycleTime" SG_ 966 VC_LDW_2_Option_CSO 2000;
BA_ "FlexKomSigStartValue" SG_ 966 VC_LDW_2_Option_CSO "0300000000000000h";
BA_ "FlexKomSigStartPos" SG_ 966 VC_LDW_2_Option_CSO 7;
BA_ "FlexKomSigName" SG_ 966 VC_LDW_2_Option_CSO "VehCfgCSM4_Pkt";
BA_ "FlexKomSigLaenge" SG_ 966 VC_LDW_2_Option_CSO 64;
BA_ "FlexKomSID" SG_ 966 VC_LDW_2_Option_CSO 3283;
BA_ "FlexKomIsMotorola" SG_ 966 VC_LDW_2_Option_CSO 1;
BA_ "FlexKomComment" SG_ 966 VC_LDW_2_Option_CSO "Vehicle configuration - customer settings menu 4 P";
BA_ "GenSigSNA" SG_ 966 VC_TrafficSignInfo_CSO "0h";
BA_ "GenSigSendType" SG_ 966 VC_TrafficSignInfo_CSO 5;
BA_ "GenSigCycleTime" SG_ 966 VC_TrafficSignInfo_CSO 2000;
BA_ "FlexKomSigStartValue" SG_ 966 VC_TrafficSignInfo_CSO "0300000000000000h";
BA_ "FlexKomSigStartPos" SG_ 966 VC_TrafficSignInfo_CSO 7;
BA_ "FlexKomSigName" SG_ 966 VC_TrafficSignInfo_CSO "VehCfgCSM4_Pkt";
BA_ "FlexKomSigLaenge" SG_ 966 VC_TrafficSignInfo_CSO 64;
BA_ "FlexKomSID" SG_ 966 VC_TrafficSignInfo_CSO 3283;
BA_ "FlexKomIsMotorola" SG_ 966 VC_TrafficSignInfo_CSO 1;
BA_ "FlexKomComment" SG_ 966 VC_TrafficSignInfo_CSO "Vehicle configuration - customer settings menu 4 P";
BA_ "GenSigSNA" SG_ 966 VC_SpeedZone_Warn_CSO "0h";
BA_ "GenSigSendType" SG_ 966 VC_SpeedZone_Warn_CSO 5;
BA_ "GenSigCycleTime" SG_ 966 VC_SpeedZone_Warn_CSO 2000;
BA_ "FlexKomSigStartValue" SG_ 966 VC_SpeedZone_Warn_CSO "0300000000000000h";
BA_ "FlexKomSigStartPos" SG_ 966 VC_SpeedZone_Warn_CSO 7;
BA_ "FlexKomSigName" SG_ 966 VC_SpeedZone_Warn_CSO "VehCfgCSM4_Pkt";
BA_ "FlexKomSigLaenge" SG_ 966 VC_SpeedZone_Warn_CSO 64;
BA_ "FlexKomSID" SG_ 966 VC_SpeedZone_Warn_CSO 3283;
BA_ "FlexKomIsMotorola" SG_ 966 VC_SpeedZone_Warn_CSO 1;
BA_ "FlexKomComment" SG_ 966 VC_SpeedZone_Warn_CSO "Vehicle configuration - customer settings menu 4 P";
BA_ "GenSigStartValue" SG_ 1040 VC_BU_VehCfgCSO4_Stat 3;
BA_ "GenSigSNA" SG_ 1040 VC_BU_VehCfgCSO4_Stat "3h";
BA_ "GenSigSendType" SG_ 1040 VC_BU_VehCfgCSO4_Stat 1;
BA_ "GenSigCycleTime" SG_ 1040 VC_BU_VehCfgCSO4_Stat 2000;
BA_ "FlexKomSigStartValue" SG_ 1040 VC_BU_VehCfgCSO4_Stat "0300000000000000h";
BA_ "FlexKomSigStartPos" SG_ 1040 VC_BU_VehCfgCSO4_Stat 7;
BA_ "FlexKomSigName" SG_ 1040 VC_BU_VehCfgCSO4_Stat "VehCfgCSM4_Pkt";
BA_ "FlexKomSigLaenge" SG_ 1040 VC_BU_VehCfgCSO4_Stat 64;
BA_ "FlexKomSID" SG_ 1040 VC_BU_VehCfgCSO4_Stat 3283;
BA_ "FlexKomIsMotorola" SG_ 1040 VC_BU_VehCfgCSO4_Stat 1;
BA_ "FlexKomComment" SG_ 1040 VC_BU_VehCfgCSO4_Stat "Vehicle configuration - customer settings menu 4 P";
BA_ "GenSigSNA" SG_ 1040 VC_BU_Drowsy_Driver_Alert_CSO "0h";
BA_ "GenSigSendType" SG_ 1040 VC_BU_Drowsy_Driver_Alert_CSO 1;
BA_ "GenSigCycleTime" SG_ 1040 VC_BU_Drowsy_Driver_Alert_CSO 2000;
BA_ "FlexKomSigStartValue" SG_ 1040 VC_BU_Drowsy_Driver_Alert_CSO "0300000000000000h";
BA_ "FlexKomSigStartPos" SG_ 1040 VC_BU_Drowsy_Driver_Alert_CSO 7;
BA_ "FlexKomSigName" SG_ 1040 VC_BU_Drowsy_Driver_Alert_CSO "VehCfgCSM4_Pkt";
BA_ "FlexKomSigLaenge" SG_ 1040 VC_BU_Drowsy_Driver_Alert_CSO 64;
BA_ "FlexKomSID" SG_ 1040 VC_BU_Drowsy_Driver_Alert_CSO 3283;
BA_ "FlexKomIsMotorola" SG_ 1040 VC_BU_Drowsy_Driver_Alert_CSO 1;
BA_ "FlexKomComment" SG_ 1040 VC_BU_Drowsy_Driver_Alert_CSO "Vehicle configuration - customer settings menu 4 P";
BA_ "GenSigSNA" SG_ 1040 VC_BU_LDW_2_Option_CSO "0h";
BA_ "GenSigSendType" SG_ 1040 VC_BU_LDW_2_Option_CSO 1;
BA_ "GenSigCycleTime" SG_ 1040 VC_BU_LDW_2_Option_CSO 2000;
BA_ "FlexKomSigStartValue" SG_ 1040 VC_BU_LDW_2_Option_CSO "0300000000000000h";
BA_ "FlexKomSigStartPos" SG_ 1040 VC_BU_LDW_2_Option_CSO 7;
BA_ "FlexKomSigName" SG_ 1040 VC_BU_LDW_2_Option_CSO "VehCfgCSM4_Pkt";
BA_ "FlexKomSigLaenge" SG_ 1040 VC_BU_LDW_2_Option_CSO 64;
BA_ "FlexKomSID" SG_ 1040 VC_BU_LDW_2_Option_CSO 3283;
BA_ "FlexKomIsMotorola" SG_ 1040 VC_BU_LDW_2_Option_CSO 1;
BA_ "FlexKomComment" SG_ 1040 VC_BU_LDW_2_Option_CSO "Vehicle configuration - customer settings menu 4 P";
BA_ "GenSigSNA" SG_ 1040 VC_BU_TrafficSignInfo_CSO "0h";
BA_ "GenSigSendType" SG_ 1040 VC_BU_TrafficSignInfo_CSO 1;
BA_ "GenSigCycleTime" SG_ 1040 VC_BU_TrafficSignInfo_CSO 2000;
BA_ "FlexKomSigStartValue" SG_ 1040 VC_BU_TrafficSignInfo_CSO "0300000000000000h";
BA_ "FlexKomSigStartPos" SG_ 1040 VC_BU_TrafficSignInfo_CSO 7;
BA_ "FlexKomSigName" SG_ 1040 VC_BU_TrafficSignInfo_CSO "VehCfgCSM4_Pkt";
BA_ "FlexKomSigLaenge" SG_ 1040 VC_BU_TrafficSignInfo_CSO 64;
BA_ "FlexKomSID" SG_ 1040 VC_BU_TrafficSignInfo_CSO 3283;
BA_ "FlexKomIsMotorola" SG_ 1040 VC_BU_TrafficSignInfo_CSO 1;
BA_ "FlexKomComment" SG_ 1040 VC_BU_TrafficSignInfo_CSO "Vehicle configuration - customer settings menu 4 P";
BA_ "GenSigSNA" SG_ 1040 VC_BU_SpeedZone_Warn_CSO "0h";
BA_ "GenSigSendType" SG_ 1040 VC_BU_SpeedZone_Warn_CSO 1;
BA_ "GenSigCycleTime" SG_ 1040 VC_BU_SpeedZone_Warn_CSO 2000;
BA_ "FlexKomSigStartValue" SG_ 1040 VC_BU_SpeedZone_Warn_CSO "0300000000000000h";
BA_ "FlexKomSigStartPos" SG_ 1040 VC_BU_SpeedZone_Warn_CSO 7;
BA_ "FlexKomSigName" SG_ 1040 VC_BU_SpeedZone_Warn_CSO "VehCfgCSM4_Pkt";
BA_ "FlexKomSigLaenge" SG_ 1040 VC_BU_SpeedZone_Warn_CSO 64;
BA_ "FlexKomSID" SG_ 1040 VC_BU_SpeedZone_Warn_CSO 3283;
BA_ "FlexKomIsMotorola" SG_ 1040 VC_BU_SpeedZone_Warn_CSO 1;
BA_ "FlexKomComment" SG_ 1040 VC_BU_SpeedZone_Warn_CSO "Vehicle configuration - customer settings menu 4 P";
BA_ "GenSigStartValue" SG_ 909 VC_VehCfg9_Stat 3;
BA_ "GenSigSNA" SG_ 909 VC_VehCfg9_Stat "3h";
BA_ "GenSigSendType" SG_ 909 VC_VehCfg9_Stat 5;
BA_ "GenSigCycleTime" SG_ 909 VC_VehCfg9_Stat 2000;
BA_ "FlexKomSigStartValue" SG_ 909 VC_VehCfg9_Stat "0300000000000000h";
BA_ "FlexKomSigStartPos" SG_ 909 VC_VehCfg9_Stat 7;
BA_ "FlexKomSigName" SG_ 909 VC_VehCfg9_Stat "VehCfg9_Pkt";
BA_ "FlexKomSigLaenge" SG_ 909 VC_VehCfg9_Stat 64;
BA_ "FlexKomSID" SG_ 909 VC_VehCfg9_Stat 3287;
BA_ "FlexKomIsMotorola" SG_ 909 VC_VehCfg9_Stat 1;
BA_ "FlexKomComment" SG_ 909 VC_VehCfg9_Stat "Vehicle Configuration 9 Packet";
BA_ "GenSigSNA" SG_ 909 VC_DrowsyDriver "0h";
BA_ "GenSigSendType" SG_ 909 VC_DrowsyDriver 5;
BA_ "GenSigCycleTime" SG_ 909 VC_DrowsyDriver 2000;
BA_ "FlexKomSigStartValue" SG_ 909 VC_DrowsyDriver "0300000000000000h";
BA_ "FlexKomSigStartPos" SG_ 909 VC_DrowsyDriver 7;
BA_ "FlexKomSigName" SG_ 909 VC_DrowsyDriver "VehCfg9_Pkt";
BA_ "FlexKomSigLaenge" SG_ 909 VC_DrowsyDriver 64;
BA_ "FlexKomSID" SG_ 909 VC_DrowsyDriver 3287;
BA_ "FlexKomIsMotorola" SG_ 909 VC_DrowsyDriver 1;
BA_ "FlexKomComment" SG_ 909 VC_DrowsyDriver "Vehicle Configuration 9 Packet";
BA_ "GenSigSNA" SG_ 909 VC_GSR_Regulation "0h";
BA_ "GenSigSendType" SG_ 909 VC_GSR_Regulation 5;
BA_ "GenSigCycleTime" SG_ 909 VC_GSR_Regulation 2000;
BA_ "FlexKomSigStartValue" SG_ 909 VC_GSR_Regulation "0300000000000000h";
BA_ "FlexKomSigStartPos" SG_ 909 VC_GSR_Regulation 7;
BA_ "FlexKomSigName" SG_ 909 VC_GSR_Regulation "VehCfg9_Pkt";
BA_ "FlexKomSigLaenge" SG_ 909 VC_GSR_Regulation 64;
BA_ "FlexKomSID" SG_ 909 VC_GSR_Regulation 3287;
BA_ "FlexKomIsMotorola" SG_ 909 VC_GSR_Regulation 1;
BA_ "FlexKomComment" SG_ 909 VC_GSR_Regulation "Vehicle Configuration 9 Packet";
BA_ "GenSigStartValue" SG_ 915 VC_BU_VehCfg9_Stat 3;
BA_ "GenSigSNA" SG_ 915 VC_BU_VehCfg9_Stat "3h";
BA_ "GenSigSendType" SG_ 915 VC_BU_VehCfg9_Stat 1;
BA_ "FlexKomSigStartValue" SG_ 915 VC_BU_VehCfg9_Stat "0300000000000000h";
BA_ "FlexKomSigStartPos" SG_ 915 VC_BU_VehCfg9_Stat 7;
BA_ "FlexKomSigName" SG_ 915 VC_BU_VehCfg9_Stat "VehCfgBU9_Pkt";
BA_ "FlexKomSigLaenge" SG_ 915 VC_BU_VehCfg9_Stat 64;
BA_ "FlexKomSID" SG_ 915 VC_BU_VehCfg9_Stat 3288;
BA_ "FlexKomIsMotorola" SG_ 915 VC_BU_VehCfg9_Stat 1;
BA_ "FlexKomComment" SG_ 915 VC_BU_VehCfg9_Stat "Backup Vehicle Configuration 8 Packet";
BA_ "GenSigSNA" SG_ 915 VC_BU_DrowsyDriver "0h";
BA_ "GenSigSendType" SG_ 915 VC_BU_DrowsyDriver 1;
BA_ "FlexKomSigStartValue" SG_ 915 VC_BU_DrowsyDriver "0300000000000000h";
BA_ "FlexKomSigStartPos" SG_ 915 VC_BU_DrowsyDriver 7;
BA_ "FlexKomSigName" SG_ 915 VC_BU_DrowsyDriver "VehCfgBU9_Pkt";
BA_ "FlexKomSigLaenge" SG_ 915 VC_BU_DrowsyDriver 64;
BA_ "FlexKomSID" SG_ 915 VC_BU_DrowsyDriver 3288;
BA_ "FlexKomIsMotorola" SG_ 915 VC_BU_DrowsyDriver 1;
BA_ "FlexKomComment" SG_ 915 VC_BU_DrowsyDriver "Backup Vehicle Configuration 9 Packet";
BA_ "GenSigSNA" SG_ 915 VC_bu_GSR_Regulation "0h";
BA_ "GenSigSendType" SG_ 915 VC_bu_GSR_Regulation 1;
BA_ "FlexKomSigStartValue" SG_ 915 VC_bu_GSR_Regulation "0300000000000000h";
BA_ "FlexKomSigStartPos" SG_ 915 VC_bu_GSR_Regulation 7;
BA_ "FlexKomSigName" SG_ 915 VC_bu_GSR_Regulation "VehCfgBU9_Pkt";
BA_ "FlexKomSigLaenge" SG_ 915 VC_bu_GSR_Regulation 64;
BA_ "FlexKomSID" SG_ 915 VC_bu_GSR_Regulation 3288;
BA_ "FlexKomIsMotorola" SG_ 915 VC_bu_GSR_Regulation 1;
BA_ "FlexKomComment" SG_ 915 VC_bu_GSR_Regulation "Backup Vehicle Configuration 9 Packet";
BA_ "GenSigTimeout_ORC" SG_ 232 HMI_Screens 210;
BA_ "GenSigTimeout_IC" SG_ 232 HMI_Screens 630;
BA_ "GenSigSNA" SG_ 232 HMI_Screens "FFh";
BA_ "GenSigSendType" SG_ 232 HMI_Screens 5;
BA_ "GenSigCycleTime" SG_ 232 HMI_Screens 60;
BA_ "FlexKomSigStartValue" SG_ 232 HMI_Screens "00FFFF00000000FFh";
BA_ "FlexKomSigStartPos" SG_ 232 HMI_Screens 7;
BA_ "FlexKomSigName" SG_ 232 HMI_Screens "DAS_A4_PKT";
BA_ "FlexKomSigLaenge" SG_ 232 HMI_Screens 64;
BA_ "FlexKomSID" SG_ 232 HMI_Screens 1717;
BA_ "FlexKomIsMotorola" SG_ 232 HMI_Screens 1;
BA_ "FlexKomComment" SG_ 232 HMI_Screens "DAS_A4 Packet";
BA_ "GenSigTimeout_IC" SG_ 232 SetSpeed_KPH 630;
BA_ "GenSigStartValue" SG_ 232 SetSpeed_KPH 255;
BA_ "GenSigSNA" SG_ 232 SetSpeed_KPH "FFh";
BA_ "GenSigSendType" SG_ 232 SetSpeed_KPH 5;
BA_ "GenSigCycleTime" SG_ 232 SetSpeed_KPH 60;
BA_ "FlexKomSigStartValue" SG_ 232 SetSpeed_KPH "00FFFF00000000FFh";
BA_ "FlexKomSigStartPos" SG_ 232 SetSpeed_KPH 7;
BA_ "FlexKomSigName" SG_ 232 SetSpeed_KPH "DAS_A4_PKT";
BA_ "FlexKomSigLaenge" SG_ 232 SetSpeed_KPH 64;
BA_ "FlexKomSID" SG_ 232 SetSpeed_KPH 1717;
BA_ "FlexKomIsMotorola" SG_ 232 SetSpeed_KPH 1;
BA_ "FlexKomComment" SG_ 232 SetSpeed_KPH "DAS_A4 Packet";
BA_ "GenSigTimeout_ORC" SG_ 232 SetSpeed_MPH 210;
BA_ "GenSigTimeout_IC" SG_ 232 SetSpeed_MPH 630;
BA_ "GenSigStartValue" SG_ 232 SetSpeed_MPH 255;
BA_ "GenSigSNA" SG_ 232 SetSpeed_MPH "FFh";
BA_ "GenSigSendType" SG_ 232 SetSpeed_MPH 5;
BA_ "GenSigCycleTime" SG_ 232 SetSpeed_MPH 60;
BA_ "FlexKomSigStartValue" SG_ 232 SetSpeed_MPH "00FFFF00000000FFh";
BA_ "FlexKomSigStartPos" SG_ 232 SetSpeed_MPH 7;
BA_ "FlexKomSigName" SG_ 232 SetSpeed_MPH "DAS_A4_PKT";
BA_ "FlexKomSigLaenge" SG_ 232 SetSpeed_MPH 64;
BA_ "FlexKomSID" SG_ 232 SetSpeed_MPH 1717;
BA_ "FlexKomIsMotorola" SG_ 232 SetSpeed_MPH 1;
BA_ "FlexKomComment" SG_ 232 SetSpeed_MPH "DAS_A4 Packet";
BA_ "GenSigTimeout_ORC" SG_ 232 FCW_Error 210;
BA_ "GenSigTimeout_IC" SG_ 232 FCW_Error 630;
BA_ "GenSigSNA" SG_ 232 FCW_Error "3h";
BA_ "GenSigSendType" SG_ 232 FCW_Error 5;
BA_ "GenSigCycleTime" SG_ 232 FCW_Error 60;
BA_ "FlexKomSigStartValue" SG_ 232 FCW_Error "00FFFF00000000FFh";
BA_ "FlexKomSigStartPos" SG_ 232 FCW_Error 7;
BA_ "FlexKomSigName" SG_ 232 FCW_Error "DAS_A4_PKT";
BA_ "FlexKomSigLaenge" SG_ 232 FCW_Error 64;
BA_ "FlexKomSID" SG_ 232 FCW_Error 1717;
BA_ "FlexKomIsMotorola" SG_ 232 FCW_Error 1;
BA_ "FlexKomComment" SG_ 232 FCW_Error "DAS_A4 Packet";
BA_ "RID" SG_ 232 FCW_BrkOn "1882";
BA_ "GenSigTimeout_ORC" SG_ 232 FCW_BrkOn 210;
BA_ "GenSigTimeout_IC" SG_ 232 FCW_BrkOn 630;
BA_ "GenSigTimeout_CBC" SG_ 232 FCW_BrkOn 630;
BA_ "GenSigSNA" SG_ 232 FCW_BrkOn "0h";
BA_ "GenSigSendType" SG_ 232 FCW_BrkOn 5;
BA_ "GenSigCycleTime" SG_ 232 FCW_BrkOn 60;
BA_ "FlexKomSigStartValue" SG_ 232 FCW_BrkOn "00FFFF00000000FFh";
BA_ "FlexKomSigStartPos" SG_ 232 FCW_BrkOn 7;
BA_ "FlexKomSigName" SG_ 232 FCW_BrkOn "DAS_A4_PKT";
BA_ "FlexKomSigLaenge" SG_ 232 FCW_BrkOn 64;
BA_ "FlexKomSID" SG_ 232 FCW_BrkOn 1717;
BA_ "FlexKomIsMotorola" SG_ 232 FCW_BrkOn 1;
BA_ "FlexKomComment" SG_ 232 FCW_BrkOn "DAS_A4 Packet";
BA_ "GenSigTimeout_ORC" SG_ 232 CIPV_Fused 210;
BA_ "GenSigSNA" SG_ 232 CIPV_Fused "0h";
BA_ "GenSigSendType" SG_ 232 CIPV_Fused 5;
BA_ "GenSigCycleTime" SG_ 232 CIPV_Fused 60;
BA_ "FlexKomSigStartValue" SG_ 232 CIPV_Fused "00FFFF00000000FFh";
BA_ "FlexKomSigStartPos" SG_ 232 CIPV_Fused 7;
BA_ "FlexKomSigName" SG_ 232 CIPV_Fused "DAS_A4_PKT";
BA_ "FlexKomSigLaenge" SG_ 232 CIPV_Fused 64;
BA_ "FlexKomSID" SG_ 232 CIPV_Fused 1717;
BA_ "FlexKomIsMotorola" SG_ 232 CIPV_Fused 1;
BA_ "FlexKomComment" SG_ 232 CIPV_Fused "DAS_A4 Packet";
BA_ "GenSigTimeout_ORC" SG_ 232 ACCOnOff 210;
BA_ "GenSigTimeout_IC" SG_ 232 ACCOnOff 630;
BA_ "GenSigSNA" SG_ 232 ACCOnOff "7h";
BA_ "GenSigSendType" SG_ 232 ACCOnOff 5;
BA_ "GenSigCycleTime" SG_ 232 ACCOnOff 60;
BA_ "FlexKomSigStartValue" SG_ 232 ACCOnOff "00FFFF00000000FFh";
BA_ "FlexKomSigStartPos" SG_ 232 ACCOnOff 7;
BA_ "FlexKomSigName" SG_ 232 ACCOnOff "DAS_A4_PKT";
BA_ "FlexKomSigLaenge" SG_ 232 ACCOnOff 64;
BA_ "FlexKomSID" SG_ 232 ACCOnOff 1717;
BA_ "FlexKomIsMotorola" SG_ 232 ACCOnOff 1;
BA_ "FlexKomComment" SG_ 232 ACCOnOff "DAS_A4 Packet";
BA_ "GenSigTimeout_ORC" SG_ 232 RadarBlocked 210;
BA_ "GenSigTimeout_IC" SG_ 232 RadarBlocked 630;
BA_ "GenSigSNA" SG_ 232 RadarBlocked "0h";
BA_ "GenSigSendType" SG_ 232 RadarBlocked 5;
BA_ "GenSigCycleTime" SG_ 232 RadarBlocked 60;
BA_ "FlexKomSigStartValue" SG_ 232 RadarBlocked "00FFFF00000000FFh";
BA_ "FlexKomSigStartPos" SG_ 232 RadarBlocked 7;
BA_ "FlexKomSigName" SG_ 232 RadarBlocked "DAS_A4_PKT";
BA_ "FlexKomSigLaenge" SG_ 232 RadarBlocked 64;
BA_ "FlexKomSID" SG_ 232 RadarBlocked 1717;
BA_ "FlexKomIsMotorola" SG_ 232 RadarBlocked 1;
BA_ "FlexKomComment" SG_ 232 RadarBlocked "DAS_A4 Packet";
BA_ "GenSigTimeout_ORC" SG_ 232 FCWBrakingOff 210;
BA_ "GenSigTimeout_IC" SG_ 232 FCWBrakingOff 630;
BA_ "GenSigSNA" SG_ 232 FCWBrakingOff "0h";
BA_ "GenSigSendType" SG_ 232 FCWBrakingOff 5;
BA_ "GenSigCycleTime" SG_ 232 FCWBrakingOff 60;
BA_ "FlexKomSigStartValue" SG_ 232 FCWBrakingOff "00FFFF00000000FFh";
BA_ "FlexKomSigStartPos" SG_ 232 FCWBrakingOff 7;
BA_ "FlexKomSigName" SG_ 232 FCWBrakingOff "DAS_A4_PKT";
BA_ "FlexKomSigLaenge" SG_ 232 FCWBrakingOff 64;
BA_ "FlexKomSID" SG_ 232 FCWBrakingOff 1717;
BA_ "FlexKomIsMotorola" SG_ 232 FCWBrakingOff 1;
BA_ "FlexKomComment" SG_ 232 FCWBrakingOff "DAS_A4 Packet";
BA_ "GenSigTimeout_IC" SG_ 232 ACConlyNA_DASMSts 630;
BA_ "GenSigSNA" SG_ 232 ACConlyNA_DASMSts "0h";
BA_ "GenSigSendType" SG_ 232 ACConlyNA_DASMSts 5;
BA_ "GenSigCycleTime" SG_ 232 ACConlyNA_DASMSts 60;
BA_ "FlexKomSigStartValue" SG_ 232 ACConlyNA_DASMSts "00FFFF00000000FFh";
BA_ "FlexKomSigStartPos" SG_ 232 ACConlyNA_DASMSts 7;
BA_ "FlexKomSigName" SG_ 232 ACConlyNA_DASMSts "DAS_A4_PKT";
BA_ "FlexKomSigLaenge" SG_ 232 ACConlyNA_DASMSts 64;
BA_ "FlexKomSID" SG_ 232 ACConlyNA_DASMSts 1717;
BA_ "FlexKomIsMotorola" SG_ 232 ACConlyNA_DASMSts 1;
BA_ "FlexKomComment" SG_ 232 ACConlyNA_DASMSts "DAS_A4 Packet";
BA_ "GenSigTimeout_IC" SG_ 232 NCConlyNA_DASMSts 630;
BA_ "GenSigSNA" SG_ 232 NCConlyNA_DASMSts "0h";
BA_ "GenSigSendType" SG_ 232 NCConlyNA_DASMSts 5;
BA_ "GenSigCycleTime" SG_ 232 NCConlyNA_DASMSts 60;
BA_ "FlexKomSigStartValue" SG_ 232 NCConlyNA_DASMSts "00FFFF00000000FFh";
BA_ "FlexKomSigStartPos" SG_ 232 NCConlyNA_DASMSts 7;
BA_ "FlexKomSigName" SG_ 232 NCConlyNA_DASMSts "DAS_A4_PKT";
BA_ "FlexKomSigLaenge" SG_ 232 NCConlyNA_DASMSts 64;
BA_ "FlexKomSID" SG_ 232 NCConlyNA_DASMSts 1717;
BA_ "FlexKomIsMotorola" SG_ 232 NCConlyNA_DASMSts 1;
BA_ "FlexKomComment" SG_ 232 NCConlyNA_DASMSts "DAS_A4 Packet";
BA_ "GenSigTimeout_ORC" SG_ 232 ACCFaulted 210;
BA_ "GenSigTimeout_IC" SG_ 232 ACCFaulted 630;
BA_ "GenSigSNA" SG_ 232 ACCFaulted "0h";
BA_ "GenSigSendType" SG_ 232 ACCFaulted 5;
BA_ "GenSigCycleTime" SG_ 232 ACCFaulted 60;
BA_ "FlexKomSigStartValue" SG_ 232 ACCFaulted "00FFFF00000000FFh";
BA_ "FlexKomSigStartPos" SG_ 232 ACCFaulted 7;
BA_ "FlexKomSigName" SG_ 232 ACCFaulted "DAS_A4_PKT";
BA_ "FlexKomSigLaenge" SG_ 232 ACCFaulted 64;
BA_ "FlexKomSID" SG_ 232 ACCFaulted 1717;
BA_ "FlexKomIsMotorola" SG_ 232 ACCFaulted 1;
BA_ "FlexKomComment" SG_ 232 ACCFaulted "DAS_A4 Packet";
BA_ "GenSigSNA" SG_ 232 FCWonlyNA_DASMSts "0h";
BA_ "GenSigSendType" SG_ 232 FCWonlyNA_DASMSts 5;
BA_ "GenSigCycleTime" SG_ 232 FCWonlyNA_DASMSts 60;
BA_ "FlexKomSigStartValue" SG_ 232 FCWonlyNA_DASMSts "00FFFF00000000FFh";
BA_ "FlexKomSigStartPos" SG_ 232 FCWonlyNA_DASMSts 7;
BA_ "FlexKomSigName" SG_ 232 FCWonlyNA_DASMSts "DAS_A4_PKT";
BA_ "FlexKomSigLaenge" SG_ 232 FCWonlyNA_DASMSts 64;
BA_ "FlexKomSID" SG_ 232 FCWonlyNA_DASMSts 1717;
BA_ "FlexKomIsMotorola" SG_ 232 FCWonlyNA_DASMSts 1;
BA_ "FlexKomComment" SG_ 232 FCWonlyNA_DASMSts "DAS_A4 Packet";
BA_ "GenSigTimeout_ORC" SG_ 232 ACCNA_DASMSts 210;
BA_ "GenSigTimeout_IC" SG_ 232 ACCNA_DASMSts 630;
BA_ "GenSigSNA" SG_ 232 ACCNA_DASMSts "0h";
BA_ "GenSigSendType" SG_ 232 ACCNA_DASMSts 5;
BA_ "GenSigCycleTime" SG_ 232 ACCNA_DASMSts 60;
BA_ "FlexKomSigStartValue" SG_ 232 ACCNA_DASMSts "00FFFF00000000FFh";
BA_ "FlexKomSigStartPos" SG_ 232 ACCNA_DASMSts 7;
BA_ "FlexKomSigName" SG_ 232 ACCNA_DASMSts "DAS_A4_PKT";
BA_ "FlexKomSigLaenge" SG_ 232 ACCNA_DASMSts 64;
BA_ "FlexKomSID" SG_ 232 ACCNA_DASMSts 1717;
BA_ "FlexKomIsMotorola" SG_ 232 ACCNA_DASMSts 1;
BA_ "FlexKomComment" SG_ 232 ACCNA_DASMSts "DAS_A4 Packet";
BA_ "GenSigTimeout_ORC" SG_ 232 NCCNA_DASMSts 210;
BA_ "GenSigTimeout_IC" SG_ 232 NCCNA_DASMSts 630;
BA_ "GenSigSNA" SG_ 232 NCCNA_DASMSts "0h";
BA_ "GenSigSendType" SG_ 232 NCCNA_DASMSts 5;
BA_ "GenSigCycleTime" SG_ 232 NCCNA_DASMSts 60;
BA_ "FlexKomSigStartValue" SG_ 232 NCCNA_DASMSts "00FFFF00000000FFh";
BA_ "FlexKomSigStartPos" SG_ 232 NCCNA_DASMSts 7;
BA_ "FlexKomSigName" SG_ 232 NCCNA_DASMSts "DAS_A4_PKT";
BA_ "FlexKomSigLaenge" SG_ 232 NCCNA_DASMSts 64;
BA_ "FlexKomSID" SG_ 232 NCCNA_DASMSts 1717;
BA_ "FlexKomIsMotorola" SG_ 232 NCCNA_DASMSts 1;
BA_ "FlexKomComment" SG_ 232 NCCNA_DASMSts "DAS_A4 Packet";
BA_ "GenSigTimeout_ORC" SG_ 232 CameraBlocked 210;
BA_ "GenSigTimeout_IC" SG_ 232 CameraBlocked 630;
BA_ "GenSigSNA" SG_ 232 CameraBlocked "0h";
BA_ "GenSigSendType" SG_ 232 CameraBlocked 5;
BA_ "GenSigCycleTime" SG_ 232 CameraBlocked 60;
BA_ "FlexKomSigStartValue" SG_ 232 CameraBlocked "00FFFF00000000FFh";
BA_ "FlexKomSigStartPos" SG_ 232 CameraBlocked 7;
BA_ "FlexKomSigName" SG_ 232 CameraBlocked "DAS_A4_PKT";
BA_ "FlexKomSigLaenge" SG_ 232 CameraBlocked 64;
BA_ "FlexKomSID" SG_ 232 CameraBlocked 1717;
BA_ "FlexKomIsMotorola" SG_ 232 CameraBlocked 1;
BA_ "FlexKomComment" SG_ 232 CameraBlocked "DAS_A4 Packet";
BA_ "GenSigTimeout_ORC" SG_ 232 CameraFailure 210;
BA_ "GenSigTimeout_IC" SG_ 232 CameraFailure 630;
BA_ "GenSigSNA" SG_ 232 CameraFailure "0h";
BA_ "GenSigSendType" SG_ 232 CameraFailure 5;
BA_ "GenSigCycleTime" SG_ 232 CameraFailure 60;
BA_ "FlexKomSigStartValue" SG_ 232 CameraFailure "00FFFF00000000FFh";
BA_ "FlexKomSigStartPos" SG_ 232 CameraFailure 7;
BA_ "FlexKomSigName" SG_ 232 CameraFailure "DAS_A4_PKT";
BA_ "FlexKomSigLaenge" SG_ 232 CameraFailure 64;
BA_ "FlexKomSID" SG_ 232 CameraFailure 1717;
BA_ "FlexKomIsMotorola" SG_ 232 CameraFailure 1;
BA_ "FlexKomComment" SG_ 232 CameraFailure "DAS_A4 Packet";
BA_ "GenSigTimeout_ORC" SG_ 232 ObjIntrstDist 210;
BA_ "GenSigStartValue" SG_ 232 ObjIntrstDist 255;
BA_ "GenSigSNA" SG_ 232 ObjIntrstDist "FFh";
BA_ "GenSigSendType" SG_ 232 ObjIntrstDist 5;
BA_ "GenSigCycleTime" SG_ 232 ObjIntrstDist 60;
BA_ "FlexKomSigStartValue" SG_ 232 ObjIntrstDist "00FFFF00000000FFh";
BA_ "FlexKomSigStartPos" SG_ 232 ObjIntrstDist 7;
BA_ "FlexKomSigName" SG_ 232 ObjIntrstDist "DAS_A4_PKT";
BA_ "FlexKomSigLaenge" SG_ 232 ObjIntrstDist 64;
BA_ "FlexKomSID" SG_ 232 ObjIntrstDist 1717;
BA_ "FlexKomIsMotorola" SG_ 232 ObjIntrstDist 1;
BA_ "FlexKomComment" SG_ 232 ObjIntrstDist "DAS_A4 Packet";
BA_ "GenSigTimeout_IC" SG_ 232 Sm_ICON_Dspl 630;
BA_ "GenSigSNA" SG_ 232 Sm_ICON_Dspl "3Fh";
BA_ "GenSigSendType" SG_ 232 Sm_ICON_Dspl 5;
BA_ "GenSigCycleTime" SG_ 232 Sm_ICON_Dspl 60;
BA_ "FlexKomSigStartValue" SG_ 232 Sm_ICON_Dspl "00FFFF00000000FFh";
BA_ "FlexKomSigStartPos" SG_ 232 Sm_ICON_Dspl 7;
BA_ "FlexKomSigName" SG_ 232 Sm_ICON_Dspl "DAS_A4_PKT";
BA_ "FlexKomSigLaenge" SG_ 232 Sm_ICON_Dspl 64;
BA_ "FlexKomSID" SG_ 232 Sm_ICON_Dspl 1717;
BA_ "FlexKomIsMotorola" SG_ 232 Sm_ICON_Dspl 1;
BA_ "FlexKomComment" SG_ 232 Sm_ICON_Dspl "DAS_A4 Packet";
BA_ "GenSigStartValue" SG_ 712 EC_ECUCfg19_Stat 3;
BA_ "GenSigSNA" SG_ 712 EC_ECUCfg19_Stat "3h";
BA_ "GenSigSendType" SG_ 712 EC_ECUCfg19_Stat 5;
BA_ "GenSigCycleTime" SG_ 712 EC_ECUCfg19_Stat 2000;
BA_ "FlexKomSigStartValue" SG_ 712 EC_ECUCfg19_Stat "03h";
BA_ "FlexKomSigStartPos" SG_ 712 EC_ECUCfg19_Stat 1;
BA_ "FlexKomSigName" SG_ 712 EC_ECUCfg19_Stat "EC_ECUCfg19_Stat";
BA_ "FlexKomSigLaenge" SG_ 712 EC_ECUCfg19_Stat 2;
BA_ "FlexKomSID" SG_ 712 EC_ECUCfg19_Stat 3306;
BA_ "FlexKomIsMotorola" SG_ 712 EC_ECUCfg19_Stat 1;
BA_ "FlexKomComment" SG_ 712 EC_ECUCfg19_Stat "ECU Configuration messages status 14";
BA_ "GenSigSNA" SG_ 712 EC_CBC19A "0h";
BA_ "GenSigSendType" SG_ 712 EC_CBC19A 5;
BA_ "GenSigCycleTime" SG_ 712 EC_CBC19A 2000;
BA_ "FlexKomSigStartValue" SG_ 712 EC_CBC19A "0000000000000000h";
BA_ "FlexKomSigStartPos" SG_ 712 EC_CBC19A 7;
BA_ "FlexKomSigName" SG_ 712 EC_CBC19A "EC_CBC19";
BA_ "FlexKomSigLaenge" SG_ 712 EC_CBC19A 64;
BA_ "FlexKomSID" SG_ 712 EC_CBC19A 3305;
BA_ "FlexKomIsMotorola" SG_ 712 EC_CBC19A 1;
BA_ "FlexKomComment" SG_ 712 EC_CBC19A "CBC ecu configuration 19";
BA_ "GenSigSNA" SG_ 712 EC_CBC19B "0h";
BA_ "GenSigSendType" SG_ 712 EC_CBC19B 5;
BA_ "GenSigCycleTime" SG_ 712 EC_CBC19B 2000;
BA_ "FlexKomSigStartValue" SG_ 712 EC_CBC19B "0000000000000000h";
BA_ "FlexKomSigStartPos" SG_ 712 EC_CBC19B 7;
BA_ "FlexKomSigName" SG_ 712 EC_CBC19B "EC_CBC19";
BA_ "FlexKomSigLaenge" SG_ 712 EC_CBC19B 64;
BA_ "FlexKomSID" SG_ 712 EC_CBC19B 3305;
BA_ "FlexKomIsMotorola" SG_ 712 EC_CBC19B 1;
BA_ "FlexKomComment" SG_ 712 EC_CBC19B "CBC ecu configuration 19";
BA_ "GenSigStartValue" SG_ 809 EC_BU_ECUCfg19_Stat 3;
BA_ "GenSigSNA" SG_ 809 EC_BU_ECUCfg19_Stat "3h";
BA_ "GenSigSendType" SG_ 809 EC_BU_ECUCfg19_Stat 1;
BA_ "GenSigCycleTime" SG_ 809 EC_BU_ECUCfg19_Stat 2000;
BA_ "FlexKomSigStartValue" SG_ 809 EC_BU_ECUCfg19_Stat "03h";
BA_ "FlexKomSigStartPos" SG_ 809 EC_BU_ECUCfg19_Stat 1;
BA_ "FlexKomSigName" SG_ 809 EC_BU_ECUCfg19_Stat "EC_BU_ECUCfg19_Stat";
BA_ "FlexKomSigLaenge" SG_ 809 EC_BU_ECUCfg19_Stat 2;
BA_ "FlexKomSID" SG_ 809 EC_BU_ECUCfg19_Stat 3308;
BA_ "FlexKomIsMotorola" SG_ 809 EC_BU_ECUCfg19_Stat 1;
BA_ "FlexKomComment" SG_ 809 EC_BU_ECUCfg19_Stat "ECU backu Configuration messages status 94";
BA_ "GenSigSNA" SG_ 809 EC_BU_CBC19A "0h";
BA_ "GenSigSendType" SG_ 809 EC_BU_CBC19A 1;
BA_ "GenSigCycleTime" SG_ 809 EC_BU_CBC19A 2000;
BA_ "FlexKomSigStartValue" SG_ 809 EC_BU_CBC19A "0000000000000000h";
BA_ "FlexKomSigStartPos" SG_ 809 EC_BU_CBC19A 7;
BA_ "FlexKomSigName" SG_ 809 EC_BU_CBC19A "EC_BU_CBC19";
BA_ "FlexKomSigLaenge" SG_ 809 EC_BU_CBC19A 64;
BA_ "FlexKomSID" SG_ 809 EC_BU_CBC19A 3307;
BA_ "FlexKomIsMotorola" SG_ 809 EC_BU_CBC19A 1;
BA_ "FlexKomComment" SG_ 809 EC_BU_CBC19A "CBC backup ecu configuration 19";
BA_ "GenSigSNA" SG_ 809 EC_BU_CBC19B "0h";
BA_ "GenSigSendType" SG_ 809 EC_BU_CBC19B 1;
BA_ "GenSigCycleTime" SG_ 809 EC_BU_CBC19B 2000;
BA_ "FlexKomSigStartValue" SG_ 809 EC_BU_CBC19B "0000000000000000h";
BA_ "FlexKomSigStartPos" SG_ 809 EC_BU_CBC19B 7;
BA_ "FlexKomSigName" SG_ 809 EC_BU_CBC19B "EC_BU_CBC19";
BA_ "FlexKomSigLaenge" SG_ 809 EC_BU_CBC19B 64;
BA_ "FlexKomSID" SG_ 809 EC_BU_CBC19B 3307;
BA_ "FlexKomIsMotorola" SG_ 809 EC_BU_CBC19B 1;
BA_ "FlexKomComment" SG_ 809 EC_BU_CBC19B "CBC backup ecu  configuration 19";
BA_ "GenSigStartValue" SG_ 827 MtrA_Temp_EDR 40;
BA_ "GenSigSNA" SG_ 827 MtrA_Temp_EDR "28h";
BA_ "GenSigCycleTime" SG_ 827 MtrA_Temp_EDR 500;
BA_ "FlexKomSigStartValue" SG_ 827 MtrA_Temp_EDR "8000100028000000h";
BA_ "FlexKomSigStartPos" SG_ 827 MtrA_Temp_EDR 7;
BA_ "FlexKomSigName" SG_ 827 MtrA_Temp_EDR "HybridRMS_MotorA_1_EDR_PKT";
BA_ "FlexKomSigLaenge" SG_ 827 MtrA_Temp_EDR 64;
BA_ "FlexKomSID" SG_ 827 MtrA_Temp_EDR 3317;
BA_ "FlexKomIsMotorola" SG_ 827 MtrA_Temp_EDR 1;
BA_ "FlexKomComment" SG_ 827 MtrA_Temp_EDR ".";
BA_ "GenSigStartValue" SG_ 827 MtrA_RPM_EDR 32768;
BA_ "GenSigSNA" SG_ 827 MtrA_RPM_EDR "8000h";
BA_ "GenSigCycleTime" SG_ 827 MtrA_RPM_EDR 500;
BA_ "FlexKomSigStartValue" SG_ 827 MtrA_RPM_EDR "8000100028000000h";
BA_ "FlexKomSigStartPos" SG_ 827 MtrA_RPM_EDR 7;
BA_ "FlexKomSigName" SG_ 827 MtrA_RPM_EDR "HybridRMS_MotorA_1_EDR_PKT";
BA_ "FlexKomSigLaenge" SG_ 827 MtrA_RPM_EDR 64;
BA_ "FlexKomSID" SG_ 827 MtrA_RPM_EDR 3317;
BA_ "FlexKomIsMotorola" SG_ 827 MtrA_RPM_EDR 1;
BA_ "FlexKomComment" SG_ 827 MtrA_RPM_EDR ".";
BA_ "GenSigStartValue" SG_ 827 MtrA_TorqAchieved_EDR 4096;
BA_ "GenSigSNA" SG_ 827 MtrA_TorqAchieved_EDR "1000h";
BA_ "GenSigCycleTime" SG_ 827 MtrA_TorqAchieved_EDR 500;
BA_ "FlexKomSigStartValue" SG_ 827 MtrA_TorqAchieved_EDR "8000100028000000h";
BA_ "FlexKomSigStartPos" SG_ 827 MtrA_TorqAchieved_EDR 7;
BA_ "FlexKomSigName" SG_ 827 MtrA_TorqAchieved_EDR "HybridRMS_MotorA_1_EDR_PKT";
BA_ "FlexKomSigLaenge" SG_ 827 MtrA_TorqAchieved_EDR 64;
BA_ "FlexKomSID" SG_ 827 MtrA_TorqAchieved_EDR 3317;
BA_ "FlexKomIsMotorola" SG_ 827 MtrA_TorqAchieved_EDR 1;
BA_ "FlexKomComment" SG_ 827 MtrA_TorqAchieved_EDR ".";
BA_ "GenSigStartValue" SG_ 828 MtrB_RPM_EDR 32768;
BA_ "GenSigSNA" SG_ 828 MtrB_RPM_EDR "8000h";
BA_ "GenSigCycleTime" SG_ 828 MtrB_RPM_EDR 500;
BA_ "FlexKomSigStartValue" SG_ 828 MtrB_RPM_EDR "8000100028000000h";
BA_ "FlexKomSigStartPos" SG_ 828 MtrB_RPM_EDR 7;
BA_ "FlexKomSigName" SG_ 828 MtrB_RPM_EDR "HybridRMS_MotorB_1_EDR_PKT";
BA_ "FlexKomSigLaenge" SG_ 828 MtrB_RPM_EDR 64;
BA_ "FlexKomSID" SG_ 828 MtrB_RPM_EDR 3318;
BA_ "FlexKomIsMotorola" SG_ 828 MtrB_RPM_EDR 1;
BA_ "FlexKomComment" SG_ 828 MtrB_RPM_EDR ".";
BA_ "GenSigStartValue" SG_ 828 MtrB_TorqAchieved_EDR 4096;
BA_ "GenSigSNA" SG_ 828 MtrB_TorqAchieved_EDR "1000h";
BA_ "GenSigCycleTime" SG_ 828 MtrB_TorqAchieved_EDR 500;
BA_ "FlexKomSigStartValue" SG_ 828 MtrB_TorqAchieved_EDR "8000100028000000h";
BA_ "FlexKomSigStartPos" SG_ 828 MtrB_TorqAchieved_EDR 7;
BA_ "FlexKomSigName" SG_ 828 MtrB_TorqAchieved_EDR "HybridRMS_MotorB_1_EDR_PKT";
BA_ "FlexKomSigLaenge" SG_ 828 MtrB_TorqAchieved_EDR 64;
BA_ "FlexKomSID" SG_ 828 MtrB_TorqAchieved_EDR 3318;
BA_ "FlexKomIsMotorola" SG_ 828 MtrB_TorqAchieved_EDR 1;
BA_ "FlexKomComment" SG_ 828 MtrB_TorqAchieved_EDR ".";
BA_ "GenSigStartValue" SG_ 828 MtrB_Temp_EDR 40;
BA_ "GenSigSNA" SG_ 828 MtrB_Temp_EDR "28h";
BA_ "GenSigCycleTime" SG_ 828 MtrB_Temp_EDR 500;
BA_ "FlexKomSigStartValue" SG_ 828 MtrB_Temp_EDR "8000100028000000h";
BA_ "FlexKomSigStartPos" SG_ 828 MtrB_Temp_EDR 7;
BA_ "FlexKomSigName" SG_ 828 MtrB_Temp_EDR "HybridRMS_MotorB_1_EDR_PKT";
BA_ "FlexKomSigLaenge" SG_ 828 MtrB_Temp_EDR 64;
BA_ "FlexKomSID" SG_ 828 MtrB_Temp_EDR 3318;
BA_ "FlexKomIsMotorola" SG_ 828 MtrB_Temp_EDR 1;
BA_ "FlexKomComment" SG_ 828 MtrB_Temp_EDR ".";
BA_ "GenSigSNA" SG_ 34 AccPos_PT "FFh";
BA_ "GenSigCycleTime" SG_ 34 AccPos_PT 10;
BA_ "FlexKomSigStartValue" SG_ 34 AccPos_PT "FFFFFF01F40000FFh";
BA_ "FlexKomSigStartPos" SG_ 34 AccPos_PT 7;
BA_ "FlexKomSigName" SG_ 34 AccPos_PT "PT_SYSTEM_1_PKT";
BA_ "FlexKomSigLaenge" SG_ 34 AccPos_PT 64;
BA_ "FlexKomSID" SG_ 34 AccPos_PT 3370;
BA_ "FlexKomIsMotorola" SG_ 34 AccPos_PT 1;
BA_ "FlexKomComment" SG_ 34 AccPos_PT "PT_SYSTEM_1_PKT Packet";
BA_ "GenSigSNA" SG_ 34 MC_PT_SYSTEM_1 "0h";
BA_ "GenSigCycleTime" SG_ 34 MC_PT_SYSTEM_1 10;
BA_ "FlexKomSigStartValue" SG_ 34 MC_PT_SYSTEM_1 "FFFFFF01F40000FFh";
BA_ "FlexKomSigStartPos" SG_ 34 MC_PT_SYSTEM_1 7;
BA_ "FlexKomSigName" SG_ 34 MC_PT_SYSTEM_1 "PT_SYSTEM_1_PKT";
BA_ "FlexKomSigLaenge" SG_ 34 MC_PT_SYSTEM_1 64;
BA_ "FlexKomSID" SG_ 34 MC_PT_SYSTEM_1 3370;
BA_ "FlexKomIsMotorola" SG_ 34 MC_PT_SYSTEM_1 1;
BA_ "FlexKomComment" SG_ 34 MC_PT_SYSTEM_1 "PT_SYSTEM_1_PKT Packet";
BA_ "GenSigStartValue" SG_ 34 CRC_PT_SYSTEM_1 255;
BA_ "GenSigSNA" SG_ 34 CRC_PT_SYSTEM_1 "FFh";
BA_ "GenSigCycleTime" SG_ 34 CRC_PT_SYSTEM_1 10;
BA_ "FlexKomSigStartValue" SG_ 34 CRC_PT_SYSTEM_1 "FFFFFF01F40000FFh";
BA_ "FlexKomSigStartPos" SG_ 34 CRC_PT_SYSTEM_1 7;
BA_ "FlexKomSigName" SG_ 34 CRC_PT_SYSTEM_1 "PT_SYSTEM_1_PKT";
BA_ "FlexKomSigLaenge" SG_ 34 CRC_PT_SYSTEM_1 64;
BA_ "FlexKomSID" SG_ 34 CRC_PT_SYSTEM_1 3370;
BA_ "FlexKomIsMotorola" SG_ 34 CRC_PT_SYSTEM_1 1;
BA_ "FlexKomComment" SG_ 34 CRC_PT_SYSTEM_1 "PT_SYSTEM_1_PKT Packet";
BA_ "GenSigStartValue" SG_ 34 Hyb_SumTorqueMin_PT 500;
BA_ "GenSigSNA" SG_ 34 Hyb_SumTorqueMin_PT "7FFh";
BA_ "GenSigCycleTime" SG_ 34 Hyb_SumTorqueMin_PT 10;
BA_ "FlexKomSigStartValue" SG_ 34 Hyb_SumTorqueMin_PT "FFFFFF01F40000FFh";
BA_ "FlexKomSigStartPos" SG_ 34 Hyb_SumTorqueMin_PT 7;
BA_ "FlexKomSigName" SG_ 34 Hyb_SumTorqueMin_PT "PT_SYSTEM_1_PKT";
BA_ "FlexKomSigLaenge" SG_ 34 Hyb_SumTorqueMin_PT 64;
BA_ "FlexKomSID" SG_ 34 Hyb_SumTorqueMin_PT 3370;
BA_ "FlexKomIsMotorola" SG_ 34 Hyb_SumTorqueMin_PT 1;
BA_ "FlexKomComment" SG_ 34 Hyb_SumTorqueMin_PT "PT_SYSTEM_1_PKT Packet";
BA_ "GenSigSNA" SG_ 34 AccPosV_PT "0h";
BA_ "GenSigCycleTime" SG_ 34 AccPosV_PT 10;
BA_ "FlexKomSigStartValue" SG_ 34 AccPosV_PT "FFFFFF01F40000FFh";
BA_ "FlexKomSigStartPos" SG_ 34 AccPosV_PT 7;
BA_ "FlexKomSigName" SG_ 34 AccPosV_PT "PT_SYSTEM_1_PKT";
BA_ "FlexKomSigLaenge" SG_ 34 AccPosV_PT 64;
BA_ "FlexKomSID" SG_ 34 AccPosV_PT 3370;
BA_ "FlexKomIsMotorola" SG_ 34 AccPosV_PT 1;
BA_ "FlexKomComment" SG_ 34 AccPosV_PT "PT_SYSTEM_1_PKT Packet";
BA_ "GenSigStartValue" SG_ 34 RawPVS1_PT 255;
BA_ "GenSigSNA" SG_ 34 RawPVS1_PT "FFh";
BA_ "GenSigCycleTime" SG_ 34 RawPVS1_PT 10;
BA_ "FlexKomSigStartValue" SG_ 34 RawPVS1_PT "FFFFFF01F40000FFh";
BA_ "FlexKomSigStartPos" SG_ 34 RawPVS1_PT 7;
BA_ "FlexKomSigName" SG_ 34 RawPVS1_PT "PT_SYSTEM_1_PKT";
BA_ "FlexKomSigLaenge" SG_ 34 RawPVS1_PT 64;
BA_ "FlexKomSID" SG_ 34 RawPVS1_PT 3370;
BA_ "FlexKomIsMotorola" SG_ 34 RawPVS1_PT 1;
BA_ "FlexKomComment" SG_ 34 RawPVS1_PT "PT_SYSTEM_1_PKT Packet";
BA_ "GenSigStartValue" SG_ 34 RawPVS2_PT 255;
BA_ "GenSigSNA" SG_ 34 RawPVS2_PT "FFh";
BA_ "GenSigCycleTime" SG_ 34 RawPVS2_PT 10;
BA_ "FlexKomSigStartValue" SG_ 34 RawPVS2_PT "FFFFFF01F40000FFh";
BA_ "FlexKomSigStartPos" SG_ 34 RawPVS2_PT 7;
BA_ "FlexKomSigName" SG_ 34 RawPVS2_PT "PT_SYSTEM_1_PKT";
BA_ "FlexKomSigLaenge" SG_ 34 RawPVS2_PT 64;
BA_ "FlexKomSID" SG_ 34 RawPVS2_PT 3370;
BA_ "FlexKomIsMotorola" SG_ 34 RawPVS2_PT 1;
BA_ "FlexKomComment" SG_ 34 RawPVS2_PT "PT_SYSTEM_1_PKT Packet";
BA_ "GenSigStartValue" SG_ 34 ActlAccelPdlPosn_PT 255;
BA_ "GenSigSNA" SG_ 34 ActlAccelPdlPosn_PT "FFh";
BA_ "GenSigCycleTime" SG_ 34 ActlAccelPdlPosn_PT 10;
BA_ "FlexKomSigStartValue" SG_ 34 ActlAccelPdlPosn_PT "FFFFFF01F40000FFh";
BA_ "FlexKomSigStartPos" SG_ 34 ActlAccelPdlPosn_PT 7;
BA_ "FlexKomSigName" SG_ 34 ActlAccelPdlPosn_PT "PT_SYSTEM_1_PKT";
BA_ "FlexKomSigLaenge" SG_ 34 ActlAccelPdlPosn_PT 64;
BA_ "FlexKomSID" SG_ 34 ActlAccelPdlPosn_PT 3370;
BA_ "FlexKomIsMotorola" SG_ 34 ActlAccelPdlPosn_PT 1;
BA_ "FlexKomComment" SG_ 34 ActlAccelPdlPosn_PT "PT_SYSTEM_1_PKT Packet";
BA_ "GenSigSNA" SG_ 34 Warn_BTO_PT "0h";
BA_ "GenSigCycleTime" SG_ 34 Warn_BTO_PT 10;
BA_ "FlexKomSigStartValue" SG_ 34 Warn_BTO_PT "FFFFFF01F40000FFh";
BA_ "FlexKomSigStartPos" SG_ 34 Warn_BTO_PT 7;
BA_ "FlexKomSigName" SG_ 34 Warn_BTO_PT "PT_SYSTEM_1_PKT";
BA_ "FlexKomSigLaenge" SG_ 34 Warn_BTO_PT 64;
BA_ "FlexKomSID" SG_ 34 Warn_BTO_PT 3370;
BA_ "FlexKomIsMotorola" SG_ 34 Warn_BTO_PT 1;
BA_ "FlexKomComment" SG_ 34 Warn_BTO_PT "PT_SYSTEM_1_PKT Packet";
BA_ "GenSigSNA" SG_ 34 CRUISE_OVERRIDE_PT "0h";
BA_ "GenSigCycleTime" SG_ 34 CRUISE_OVERRIDE_PT 10;
BA_ "FlexKomSigStartValue" SG_ 34 CRUISE_OVERRIDE_PT "FFFFFF01F40000FFh";
BA_ "FlexKomSigStartPos" SG_ 34 CRUISE_OVERRIDE_PT 7;
BA_ "FlexKomSigName" SG_ 34 CRUISE_OVERRIDE_PT "PT_SYSTEM_1_PKT";
BA_ "FlexKomSigLaenge" SG_ 34 CRUISE_OVERRIDE_PT 64;
BA_ "FlexKomSID" SG_ 34 CRUISE_OVERRIDE_PT 3370;
BA_ "FlexKomIsMotorola" SG_ 34 CRUISE_OVERRIDE_PT 1;
BA_ "FlexKomComment" SG_ 34 CRUISE_OVERRIDE_PT "PT_SYSTEM_1_PKT Packet";
BA_ "GenSigSNA" SG_ 34 EngTrq_Enbl_Rq_ESC_PT "0h";
BA_ "GenSigCycleTime" SG_ 34 EngTrq_Enbl_Rq_ESC_PT 10;
BA_ "FlexKomSigStartValue" SG_ 34 EngTrq_Enbl_Rq_ESC_PT "FFFFFF01F40000FFh";
BA_ "FlexKomSigStartPos" SG_ 34 EngTrq_Enbl_Rq_ESC_PT 7;
BA_ "FlexKomSigName" SG_ 34 EngTrq_Enbl_Rq_ESC_PT "PT_SYSTEM_1_PKT";
BA_ "FlexKomSigLaenge" SG_ 34 EngTrq_Enbl_Rq_ESC_PT 64;
BA_ "FlexKomSID" SG_ 34 EngTrq_Enbl_Rq_ESC_PT 3370;
BA_ "FlexKomIsMotorola" SG_ 34 EngTrq_Enbl_Rq_ESC_PT 1;
BA_ "FlexKomComment" SG_ 34 EngTrq_Enbl_Rq_ESC_PT "PT_SYSTEM_1_PKT Packet";
BA_ "GenSigSNA" SG_ 34 EngTrq_Enbl_Rq_AS_PT "0h";
BA_ "GenSigCycleTime" SG_ 34 EngTrq_Enbl_Rq_AS_PT 10;
BA_ "FlexKomSigStartValue" SG_ 34 EngTrq_Enbl_Rq_AS_PT "FFFFFF01F40000FFh";
BA_ "FlexKomSigStartPos" SG_ 34 EngTrq_Enbl_Rq_AS_PT 7;
BA_ "FlexKomSigName" SG_ 34 EngTrq_Enbl_Rq_AS_PT "PT_SYSTEM_1_PKT";
BA_ "FlexKomSigLaenge" SG_ 34 EngTrq_Enbl_Rq_AS_PT 64;
BA_ "FlexKomSID" SG_ 34 EngTrq_Enbl_Rq_AS_PT 3370;
BA_ "FlexKomIsMotorola" SG_ 34 EngTrq_Enbl_Rq_AS_PT 1;
BA_ "FlexKomComment" SG_ 34 EngTrq_Enbl_Rq_AS_PT "PT_SYSTEM_1_PKT Packet";
BA_ "GenSigSNA" SG_ 2026 D_RS_EVCU2 "0h";
BA_ "GenSigSendType" SG_ 2026 D_RS_EVCU2 1;
BA_ "FlexKomSigStartValue" SG_ 2026 D_RS_EVCU2 "0000000000000000h";
BA_ "FlexKomSigStartPos" SG_ 2026 D_RS_EVCU2 7;
BA_ "FlexKomSigName" SG_ 2026 D_RS_EVCU2 "D_RS_EVCU2";
BA_ "FlexKomSigLaenge" SG_ 2026 D_RS_EVCU2 64;
BA_ "FlexKomSID" SG_ 2026 D_RS_EVCU2 3458;
BA_ "FlexKomIsMotorola" SG_ 2026 D_RS_EVCU2 1;
BA_ "FlexKomComment" SG_ 2026 D_RS_EVCU2 "Diagnostic-Response";
BA_ "GenSigSNA" SG_ 1594 SD_RS_EVCU2 "0h";
BA_ "GenSigSendType" SG_ 1594 SD_RS_EVCU2 9;
BA_ "GenSigCycleTime" SG_ 1594 SD_RS_EVCU2 200;
BA_ "FlexKomSigStartValue" SG_ 1594 SD_RS_EVCU2 "0000000000000000h";
BA_ "FlexKomSigStartPos" SG_ 1594 SD_RS_EVCU2 7;
BA_ "FlexKomSigName" SG_ 1594 SD_RS_EVCU2 "SD_RS_EVCU2";
BA_ "FlexKomSigLaenge" SG_ 1594 SD_RS_EVCU2 64;
BA_ "FlexKomSID" SG_ 1594 SD_RS_EVCU2 3462;
BA_ "FlexKomIsMotorola" SG_ 1594 SD_RS_EVCU2 1;
BA_ "FlexKomComment" SG_ 1594 SD_RS_EVCU2 "Response on Event - light";
BA_ "GenSigSNA" SG_ 2018 D_RQ_EVCU2 "0h";
BA_ "GenSigSendType" SG_ 2018 D_RQ_EVCU2 1;
BA_ "FlexKomSigStartValue" SG_ 2018 D_RQ_EVCU2 "0000000000000000h";
BA_ "FlexKomSigStartPos" SG_ 2018 D_RQ_EVCU2 7;
BA_ "FlexKomSigName" SG_ 2018 D_RQ_EVCU2 "D_RQ_EVCU2";
BA_ "FlexKomSigLaenge" SG_ 2018 D_RQ_EVCU2 64;
BA_ "FlexKomSID" SG_ 2018 D_RQ_EVCU2 3459;
BA_ "FlexKomIsMotorola" SG_ 2018 D_RQ_EVCU2 1;
BA_ "FlexKomComment" SG_ 2018 D_RQ_EVCU2 "Diagnostic-Request";
BA_ "GenSigSNA" SG_ 1466 ECU_APPL_EVCU2 "0h";
BA_ "GenSigSendType" SG_ 1466 ECU_APPL_EVCU2 1;
BA_ "FlexKomSigStartValue" SG_ 1466 ECU_APPL_EVCU2 "0000000000000000h";
BA_ "FlexKomSigStartPos" SG_ 1466 ECU_APPL_EVCU2 7;
BA_ "FlexKomSigName" SG_ 1466 ECU_APPL_EVCU2 "ECU_APPL_EVCU2";
BA_ "FlexKomSigLaenge" SG_ 1466 ECU_APPL_EVCU2 64;
BA_ "FlexKomSID" SG_ 1466 ECU_APPL_EVCU2 3460;
BA_ "FlexKomIsMotorola" SG_ 1466 ECU_APPL_EVCU2 1;
BA_ "FlexKomComment" SG_ 1466 ECU_APPL_EVCU2 "ECU to External Application";
BA_ "GenSigSNA" SG_ 1786 APPL_ECU_EVCU2 "0h";
BA_ "GenSigSendType" SG_ 1786 APPL_ECU_EVCU2 1;
BA_ "FlexKomSigStartValue" SG_ 1786 APPL_ECU_EVCU2 "0000000000000000h";
BA_ "FlexKomSigStartPos" SG_ 1786 APPL_ECU_EVCU2 7;
BA_ "FlexKomSigName" SG_ 1786 APPL_ECU_EVCU2 "APPL_ECU_EVCU2";
BA_ "FlexKomSigLaenge" SG_ 1786 APPL_ECU_EVCU2 64;
BA_ "FlexKomSID" SG_ 1786 APPL_ECU_EVCU2 3461;
BA_ "FlexKomIsMotorola" SG_ 1786 APPL_ECU_EVCU2 1;
BA_ "FlexKomComment" SG_ 1786 APPL_ECU_EVCU2 "External Application to ECU";
BA_ "GenSigStartValue" SG_ 1082 NM_Mode 255;
BA_ "GenSigSNA" SG_ 1082 NM_Mode "FFh";
BA_ "GenSigSendType" SG_ 1082 NM_Mode 1;
BA_ "FlexKomSigStartValue" SG_ 1082 NM_Mode "FFFFFFFFh";
BA_ "FlexKomSigStartPos" SG_ 1082 NM_Mode 7;
BA_ "FlexKomSigName" SG_ 1082 NM_Mode "NM";
BA_ "FlexKomSigLaenge" SG_ 1082 NM_Mode 32;
BA_ "FlexKomSID" SG_ 1082 NM_Mode 472;
BA_ "FlexKomIsMotorola" SG_ 1082 NM_Mode 1;
BA_ "FlexKomComment" SG_ 1082 NM_Mode "Network management state";
BA_ "GenSigStartValue" SG_ 1082 NM_Sleep_Ack 1;
BA_ "GenSigSNA" SG_ 1082 NM_Sleep_Ack "1h";
BA_ "GenSigSendType" SG_ 1082 NM_Sleep_Ack 1;
BA_ "FlexKomSigStartValue" SG_ 1082 NM_Sleep_Ack "FFFFFFFFh";
BA_ "FlexKomSigStartPos" SG_ 1082 NM_Sleep_Ack 7;
BA_ "FlexKomSigName" SG_ 1082 NM_Sleep_Ack "NM";
BA_ "FlexKomSigLaenge" SG_ 1082 NM_Sleep_Ack 32;
BA_ "FlexKomSID" SG_ 1082 NM_Sleep_Ack 472;
BA_ "FlexKomIsMotorola" SG_ 1082 NM_Sleep_Ack 1;
BA_ "FlexKomComment" SG_ 1082 NM_Sleep_Ack "Network management state";
BA_ "GenSigStartValue" SG_ 1082 Nw_Id 255;
BA_ "GenSigSNA" SG_ 1082 Nw_Id "FFh";
BA_ "GenSigSendType" SG_ 1082 Nw_Id 1;
BA_ "FlexKomSigStartValue" SG_ 1082 Nw_Id "FFh";
BA_ "FlexKomSigStartPos" SG_ 1082 Nw_Id 63;
BA_ "FlexKomSigName" SG_ 1082 Nw_Id "Nw_Id";
BA_ "FlexKomSigLaenge" SG_ 1082 Nw_Id 8;
BA_ "FlexKomSID" SG_ 1082 Nw_Id 535;
BA_ "FlexKomIsMotorola" SG_ 1082 Nw_Id 1;
BA_ "FlexKomComment" SG_ 1082 Nw_Id "Network identification no.";
BA_ "GenSigStartValue" SG_ 1082 NM_Successor 255;
BA_ "GenSigSNA" SG_ 1082 NM_Successor "FFh";
BA_ "GenSigSendType" SG_ 1082 NM_Successor 1;
BA_ "FlexKomSigStartValue" SG_ 1082 NM_Successor "FFFFFFFFh";
BA_ "FlexKomSigStartPos" SG_ 1082 NM_Successor 7;
BA_ "FlexKomSigName" SG_ 1082 NM_Successor "NM";
BA_ "FlexKomSigLaenge" SG_ 1082 NM_Successor 32;
BA_ "FlexKomSID" SG_ 1082 NM_Successor 472;
BA_ "FlexKomIsMotorola" SG_ 1082 NM_Successor 1;
BA_ "FlexKomComment" SG_ 1082 NM_Successor "Network management state";
BA_ "GenSigStartValue" SG_ 1082 NM_Ud_Launch 63;
BA_ "GenSigSNA" SG_ 1082 NM_Ud_Launch "3Fh";
BA_ "GenSigSendType" SG_ 1082 NM_Ud_Launch 1;
BA_ "FlexKomSigStartValue" SG_ 1082 NM_Ud_Launch "FFFFFFFFh";
BA_ "FlexKomSigStartPos" SG_ 1082 NM_Ud_Launch 7;
BA_ "FlexKomSigName" SG_ 1082 NM_Ud_Launch "NM";
BA_ "FlexKomSigLaenge" SG_ 1082 NM_Ud_Launch 32;
BA_ "FlexKomSID" SG_ 1082 NM_Ud_Launch 472;
BA_ "FlexKomIsMotorola" SG_ 1082 NM_Ud_Launch 1;
BA_ "FlexKomComment" SG_ 1082 NM_Ud_Launch "Network management state";
BA_ "GenSigStartValue" SG_ 1082 NM_Sleep_Ind 1;
BA_ "GenSigSNA" SG_ 1082 NM_Sleep_Ind "1h";
BA_ "GenSigSendType" SG_ 1082 NM_Sleep_Ind 1;
BA_ "FlexKomSigStartValue" SG_ 1082 NM_Sleep_Ind "FFFFFFFFh";
BA_ "FlexKomSigStartPos" SG_ 1082 NM_Sleep_Ind 7;
BA_ "FlexKomSigName" SG_ 1082 NM_Sleep_Ind "NM";
BA_ "FlexKomSigLaenge" SG_ 1082 NM_Sleep_Ind 32;
BA_ "FlexKomSID" SG_ 1082 NM_Sleep_Ind 472;
BA_ "FlexKomIsMotorola" SG_ 1082 NM_Sleep_Ind 1;
BA_ "FlexKomComment" SG_ 1082 NM_Sleep_Ind "Network management state";
BA_ "GenSigStartValue" SG_ 1082 NM_Ud_Srv 255;
BA_ "GenSigSNA" SG_ 1082 NM_Ud_Srv "FFh";
BA_ "GenSigSendType" SG_ 1082 NM_Ud_Srv 1;
BA_ "FlexKomSigStartValue" SG_ 1082 NM_Ud_Srv "FFFFFFFFh";
BA_ "FlexKomSigStartPos" SG_ 1082 NM_Ud_Srv 7;
BA_ "FlexKomSigName" SG_ 1082 NM_Ud_Srv "NM";
BA_ "FlexKomSigLaenge" SG_ 1082 NM_Ud_Srv 32;
BA_ "FlexKomSID" SG_ 1082 NM_Ud_Srv 472;
BA_ "FlexKomIsMotorola" SG_ 1082 NM_Ud_Srv 1;
BA_ "FlexKomComment" SG_ 1082 NM_Ud_Srv "Network management state";
BA_ "GenSigStartValue" SG_ 1082 WakeupRsn_EVCU2 255;
BA_ "GenSigSNA" SG_ 1082 WakeupRsn_EVCU2 "FFh";
BA_ "GenSigSendType" SG_ 1082 WakeupRsn_EVCU2 1;
BA_ "FlexKomSigStartValue" SG_ 1082 WakeupRsn_EVCU2 "FFFF00h";
BA_ "FlexKomSigStartPos" SG_ 1082 WakeupRsn_EVCU2 39;
BA_ "FlexKomSigName" SG_ 1082 WakeupRsn_EVCU2 "Wakeup_EVCU2";
BA_ "FlexKomSigLaenge" SG_ 1082 WakeupRsn_EVCU2 24;
BA_ "FlexKomSID" SG_ 1082 WakeupRsn_EVCU2 2123;
BA_ "FlexKomIsMotorola" SG_ 1082 WakeupRsn_EVCU2 1;
BA_ "FlexKomComment" SG_ 1082 WakeupRsn_EVCU2 "Mode 2 of NM_Ud_Srv";
BA_ "GenSigSNA" SG_ 1082 Awake_Chg_ST "0h";
BA_ "GenSigSendType" SG_ 1082 Awake_Chg_ST 1;
BA_ "FlexKomSigStartValue" SG_ 1082 Awake_Chg_ST "000000h";
BA_ "FlexKomSigStartPos" SG_ 1082 Awake_Chg_ST 39;
BA_ "FlexKomSigName" SG_ 1082 Awake_Chg_ST "Awake_EVCU2";
BA_ "FlexKomSigLaenge" SG_ 1082 Awake_Chg_ST 24;
BA_ "FlexKomSID" SG_ 1082 Awake_Chg_ST 2122;
BA_ "FlexKomIsMotorola" SG_ 1082 Awake_Chg_ST 1;
BA_ "FlexKomComment" SG_ 1082 Awake_Chg_ST "Mode 15 of NM_Ud_Srv";
BA_ "GenSigSNA" SG_ 1082 Awake_OBCM_WU "0h";
BA_ "GenSigSendType" SG_ 1082 Awake_OBCM_WU 1;
BA_ "FlexKomSigStartValue" SG_ 1082 Awake_OBCM_WU "000000h";
BA_ "FlexKomSigStartPos" SG_ 1082 Awake_OBCM_WU 39;
BA_ "FlexKomSigName" SG_ 1082 Awake_OBCM_WU "Awake_EVCU2";
BA_ "FlexKomSigLaenge" SG_ 1082 Awake_OBCM_WU 24;
BA_ "FlexKomSID" SG_ 1082 Awake_OBCM_WU 2122;
BA_ "FlexKomIsMotorola" SG_ 1082 Awake_OBCM_WU 1;
BA_ "FlexKomComment" SG_ 1082 Awake_OBCM_WU "Mode 15 of NM_Ud_Srv";
BA_ "GenSigSNA" SG_ 1082 Awake_Diag_Actv "0h";
BA_ "GenSigSendType" SG_ 1082 Awake_Diag_Actv 1;
BA_ "FlexKomSigStartValue" SG_ 1082 Awake_Diag_Actv "000000h";
BA_ "FlexKomSigStartPos" SG_ 1082 Awake_Diag_Actv 39;
BA_ "FlexKomSigName" SG_ 1082 Awake_Diag_Actv "Awake_EVCU2";
BA_ "FlexKomSigLaenge" SG_ 1082 Awake_Diag_Actv 24;
BA_ "FlexKomSID" SG_ 1082 Awake_Diag_Actv 2122;
BA_ "FlexKomIsMotorola" SG_ 1082 Awake_Diag_Actv 1;
BA_ "FlexKomComment" SG_ 1082 Awake_Diag_Actv "Mode 15 of NM_Ud_Srv";
BA_ "GenSigSNA" SG_ 1082 Awake_NwSt "0h";
BA_ "GenSigSendType" SG_ 1082 Awake_NwSt 1;
BA_ "FlexKomSigStartValue" SG_ 1082 Awake_NwSt "000000h";
BA_ "FlexKomSigStartPos" SG_ 1082 Awake_NwSt 39;
BA_ "FlexKomSigName" SG_ 1082 Awake_NwSt "Awake_EVCU2";
BA_ "FlexKomSigLaenge" SG_ 1082 Awake_NwSt 24;
BA_ "FlexKomSID" SG_ 1082 Awake_NwSt 2122;
BA_ "FlexKomIsMotorola" SG_ 1082 Awake_NwSt 1;
BA_ "FlexKomComment" SG_ 1082 Awake_NwSt "Mode 15 of NM_Ud_Srv";
BA_ "GenSigStartValue" SG_ 1082 WakeupCnt 255;
BA_ "GenSigSNA" SG_ 1082 WakeupCnt "FFh";
BA_ "GenSigSendType" SG_ 1082 WakeupCnt 1;
BA_ "FlexKomSigStartValue" SG_ 1082 WakeupCnt "FFFF00h";
BA_ "FlexKomSigStartPos" SG_ 1082 WakeupCnt 39;
BA_ "FlexKomSigName" SG_ 1082 WakeupCnt "Wakeup_EVCU2";
BA_ "FlexKomSigLaenge" SG_ 1082 WakeupCnt 24;
BA_ "FlexKomSID" SG_ 1082 WakeupCnt 2123;
BA_ "FlexKomIsMotorola" SG_ 1082 WakeupCnt 1;
BA_ "FlexKomComment" SG_ 1082 WakeupCnt "Mode 2 of NM_Ud_Srv";
BA_ "GenSigSNA" SG_ 1268 D_RS_MCPB "0h";
BA_ "GenSigSendType" SG_ 1268 D_RS_MCPB 1;
BA_ "FlexKomSigStartValue" SG_ 1268 D_RS_MCPB "0000000000000000h";
BA_ "FlexKomSigStartPos" SG_ 1268 D_RS_MCPB 7;
BA_ "FlexKomSigName" SG_ 1268 D_RS_MCPB "D_RS_MCPB";
BA_ "FlexKomSigLaenge" SG_ 1268 D_RS_MCPB 64;
BA_ "FlexKomSID" SG_ 1268 D_RS_MCPB 2130709670;
BA_ "FlexKomIsMotorola" SG_ 1268 D_RS_MCPB 1;
BA_ "FlexKomComment" SG_ 1268 D_RS_MCPB "Diagnostic-Response";
VAL_ 966 VC_VehCfgCSO4_Stat 0 "NA" 1 "PROGAMMED" 2 "REQUEST_DATA" 3 "SNA" ;
VAL_ 1040 VC_BU_VehCfgCSO4_Stat 0 "NA" 1 "PROGAMMED" 2 "REQUEST_DATA" 3 "SNA" ;
VAL_ 909 VC_VehCfg9_Stat 0 "NA" 1 "PROGAMMED" 2 "REQUEST_DATA" 3 "SNA" ;
VAL_ 915 VC_BU_VehCfg9_Stat 0 "NA" 1 "PROGAMMED" 2 "NA1" 3 "SNA" ;
VAL_ 232 HMI_Screens 255 "SNA" ;
VAL_ 232 SetSpeed_KPH 255 "SNA" ;
VAL_ 232 SetSpeed_MPH 255 "SNA" ;
VAL_ 232 FCW_Error 0 "No_Error" 1 "FCW_Error" 2 "Limited_FCW" 3 "SNA" ;
VAL_ 232 ACCOnOff 0 "OFF" 1 "NCC" 2 "NCC_SET" 3 "ACC_ON" 4 "ACC_SET" 7 "SNA" ;
VAL_ 232 ObjIntrstDist 255 "SNA" ;
VAL_ 232 Sm_ICON_Dspl 0 "NONE" 1 "OFF" 2 "READY_TG1" 3 "READY_TG2" 4 "READY_TG3" 5 "READY_TG4" 8 "ACC_E_NT_TG1" 9 "ACC_E_NT_TG2" 10 "ACC_E_NT_TG3" 11 "ACC_E_NT_TG4" 12 "ACC_E_WT_TG1" 13 "ACC_E_WT_TG2" 14 "ACC_E_WT_TG3" 15 "ACC_E_WT_TG4" 33 "NCC_OFF" 34 "NCC_READY" 40 "NCC_ENGAGED" 63 "SNA" ;
VAL_ 712 EC_ECUCfg19_Stat 0 "NA" 1 "PROGAMMED" 2 "REQUEST_DATA" 3 "SNA" ;
VAL_ 809 EC_BU_ECUCfg19_Stat 0 "NA" 1 "PROGAMMED" 2 "REQUEST_DATA" 3 "SNA" ;
VAL_ 34 AccPos_PT 255 "SNA" ;
VAL_ 34 Hyb_SumTorqueMin_PT 2047 "SNA" ;
VAL_ 34 AccPosV_PT 0 "Valid" 1 "Invalid" ;
VAL_ 34 RawPVS1_PT 255 "SNA" ;
VAL_ 34 RawPVS2_PT 255 "SNA" ;
VAL_ 34 ActlAccelPdlPosn_PT 255 "SNA" ;
VAL_ 34 Warn_BTO_PT 0 "Not_Active" 1 "Active" ;
VAL_ 34 CRUISE_OVERRIDE_PT 0 "Not_Valid" 1 "Valid" ;
VAL_ 34 EngTrq_Enbl_Rq_ESC_PT 0 "Not_Valid" 1 "Valid" ;
VAL_ 34 EngTrq_Enbl_Rq_AS_PT 0 "Not_Valid" 1 "Valid" ;
VAL_ 1082 NM_Mode 252 "LHOM" 253 "RING" 254 "ALIVE" 255 "SNA" ;
VAL_ 1082 Nw_Id 0 "POWERTRAIN" 1 "BODY" 2 "AUDIO_TELE" 255 "SNA" ;
VAL_ 1082 NM_Successor 255 "SNA" ;
VAL_ 1082 NM_Ud_Launch 4 "BROADCAST" 63 "SNA" ;
VAL_ 1082 NM_Ud_Srv 2 "WAKEUP_SA" 15 "AWAKE_BC" 255 "NO_USER_DATA" ;
VAL_ 1082 WakeupRsn_EVCU2 0 "NETWORK" 1 "CBC_WU" 2 "IGN_WU" 3 "OBCM_WU" 255 "SNA" ;
VAL_ 1082 WakeupCnt 255 "SNA" ;
